VERSION ""

NS_ :

BS_:

BU_: PPIM HCP VDCM APM2 SGW IDCM EVCU2 BPCM

BO_ 2564455666 DIAGNOSTIC_REQUEST_FD_SGCP: 64 SGW
 SG_ N_PDU_18DA7CF2 : 7|64@0+ (1,0) [0|0] "" EVCU2

BO_ 1064 SGCP_DATA2: 64 EVCU2
 SG_ SGCP_Temp : 7|8@0+ (1,-40) [-40|215] "°C"  SGW

BO_ 263 PT_SYSTEM_FD_1: 64 EVCU2
 SG_ PowertrainPrplsnActv_PT : 146|1@0+ (1,0) [0|1] "" IDCM,BPCM
 SG_ GearEngagedForDisplay_PT : 12|5@0+ (1,0) [0|31] "" IDCM,BPCM
 SG_ GearEngaged_PT : 132|4@0+ (1,0) [0|15] "" Vector__XXX
 SG_ DriveReady_PT : 166|1@0+ (1,0) [0|1] "" BPCM

BO_ 2654339197 PDC_INFO_FD_IDCM: 32 IDCM
 SG_ EOL_FD11_IDCM : 7|1@0+ (1,0) [0|1] "-"  EVCU2,SGW
 SG_ WakeupSource_FD11_IDCM : 95|8@0+ (1,0) [0|255] "" EVCU2,SGW
 SG_ StayActiveSource_FD11_IDCM : 111|64@0+ (1,0) [0|0] "" EVCU2,SGW
 SG_ PreviousCanNMState_FD11_IDCM : 103|4@0+ (1,0) [0|15] "" EVCU2,SGW
 SG_ GenericFailSts_FD11_IDCM : 180|1@0+ (1,0) [0|1] "" EVCU2,SGW
 SG_ DES_FD11_IDCM : 183|2@0+ (1,0) [0|3] "" EVCU2,SGW
 SG_ CurrentFailSts_FD11_IDCM : 181|1@0+ (1,0) [0|1] "" EVCU2,SGW
 SG_ CurrentCanNMState_FD11_IDCM : 99|4@0+ (1,0) [0|15] "" EVCU2,SGW
 SG_ WakeupSource_FD05_IDCM : 23|8@0+ (1,0) [0|255] "" EVCU2,SGW
 SG_ StayActiveSource_FD05_IDCM : 31|64@0+ (1,0) [0|0] "" EVCU2,SGW
 SG_ PreviousCanNMState_FD05_IDCM : 11|4@0+ (1,0) [0|15] "" EVCU2,SGW
 SG_ GenericFailSts_FD05_IDCM : 5|1@0+ (1,0) [0|1] "" EVCU2,SGW
 SG_ EOL_FD05_IDCM : 2|1@0+ (1,0) [0|1] "-"  EVCU2,SGW
 SG_ DES_FD05_IDCM : 4|2@0+ (1,0) [0|3] "" EVCU2,SGW
 SG_ CurrentFailSts_FD05_IDCM : 6|1@0+ (1,0) [0|1] "" EVCU2,SGW
 SG_ CurrentCanNMState_FD05_IDCM : 15|4@0+ (1,0) [0|15] "" EVCU2,SGW

BO_ 216 PT_ENERGY_FD_1: 64 EVCU2
 SG_ MC_PT_ENERGY_FD_1 : 435|4@0+ (1,0) [0|15] "-"  IDCM,BPCM
 SG_ DCChrgVoltMin_PT : 55|14@0+ (0.1,0) [0|1638.30] "" APM2
 SG_ DCChrgVoltMax_PT : 151|14@0+ (0.1,0) [0|1638.30] "V"  APM2
 SG_ DCChrgPwrLim_PT : 119|14@0+ (0.1,-815) [-815|823.30] "kW"  APM2
 SG_ DCChrgCurrentRq_PT : 95|14@0+ (0.1,-815) [-815|823.30] "A"  APM2
 SG_ DCChrgCurrentLimit_PT : 21|14@0+ (0.1,-815) [-815|823.30] "A"  APM2
 SG_ DCChargeInitialized_PT : 56|1@0+ (1,0) [0|1] "" BPCM
 SG_ DCChargeEnRq_PT : 38|1@0+ (1,0) [0|1] "" APM2
 SG_ CRC_PT_ENERGY_FD_1 : 447|8@0+ (1,0) [0|255] "-"  IDCM,BPCM
 SG_ BPCM_OBCM_AC_ContactorCmd_PT : 140|3@0+ (1,0) [0|7] "" IDCM,BPCM
 SG_ BMS_HV_TracCntctr_Cmd_PT : 4|3@0+ (1,0) [0|7] "" IDCM,BPCM
 SG_ BMS_HV_RefTracHVBus_V_Vldty_PT : 23|1@0+ (1,0) [0|1] "" BPCM
 SG_ BMS_HV_RefTracHVBus_V_PT : 1|10@0+ (1,0) [0|1023] "" BPCM
 SG_ BMS_HV_GFD_Inhibition_PT : 39|1@0+ (1,0) [0|1] "" BPCM
 SG_ BMS_HV_DC_Chrgng_Cntct_K_Cmd_PT : 82|3@0+ (1,0) [0|7] "" APM2,IDCM,BPCM
 SG_ BatteryVoltage_Raw_PT : 97|10@0+ (0.2,0) [0|204.60] "V"  IDCM,BPCM
 SG_ APM2_TypeCtrl_PT : 7|3@0+ (1,0) [0|7] "" APM2
 SG_ APM_LV_VsetPoint_PT : 135|11@0+ (0.01,0) [0|20.47] "V"  IDCM
 SG_ APM_LV_VActual_PT : 71|9@0+ (0.04,0) [0|20.44] "V"  IDCM
 SG_ APM_LV_IMax_PT : 167|9@0+ (1,0) [0|511] "A"  IDCM
 SG_ APM_HV_IMax_PT : 87|5@0+ (0.8,0) [0|24.8] "A"  IDCM
 SG_ APM_TypeCtrl_PT : 78|4@0+ (1,0) [0|15] "" IDCM
 SG_ EVCU_Resp_AUX_LoadTurned_Off : 174|1@0+ (1,0) [0|1] "" BPCM
 SG_ DC_Charge_Type_Command : 121|2@0+ (1,0) [0|3] "" BPCM
 SG_ BMS_HV_Char_Main_Contac_Cmd_PT : 173|3@0+ (1,0) [0|7] "" BPCM
 SG_ APM2_EVSEBusPrechargeReq_PT : 57|1@0+ (1,0) [0|1] "" APM2
 SG_ APM2_EVSEBusVoltSetPoint_PT : 37|14@0+ (0.1,0) [0|1638.30] "V"  APM2
 SG_ APM2ActDischRq_PT : 22|1@0+ (1,0) [0|1] "" APM2
 SG_ APM2_BoostSwitchControl : 137|2@0+ (1,0) [0|3] "" APM2
 SG_ APM2_ModeRequest_PT : 183|4@0+ (1,0) [0|15] "" APM2

BO_ 1042 IDCM_ISO15118_STATUS1: 64 IDCM
 SG_ PMax_RelStart_Interval : 79|24@0+ (1,0) [0|16777215] "Seconds"  EVCU2
 SG_ PMax_RelDuration_Interval : 103|24@0+ (1,0) [0|16777215] "Seconds"  EVCU2
 SG_ ParameterID_Update : 235|1@0+ (1,0) [0|1] "" EVCU2
 SG_ ParameterID_Installation : 192|1@0+ (1,0) [0|1] "" EVCU2
 SG_ ISO15118_VersionNumMinor : 4|3@0+ (1,0) [0|7] "" EVCU2
 SG_ ISO15118_VersionNumMajor : 7|3@0+ (1,0) [0|7] "" EVCU2
 SG_ ISO15118_TLS_Status : 191|3@0+ (1,0) [0|4] "" EVCU2
 SG_ ISO15118_TLS_Offered : 176|1@0+ (1,0) [0|1] "" EVCU2
 SG_ ISO15118_ServiceID : 143|16@0+ (1,0) [0|65535] "" EVCU2
 SG_ ISO15118_SchemaID : 199|7@0+ (1,0) [0|127] "" EVCU2
 SG_ ISO15118_SAScheduleTupleID : 127|8@0+ (1,0) [0|255] "" EVCU2
 SG_ ISO15118_ResponseCode : 181|5@0+ (1,0) [0|31] "" EVCU2
 SG_ ISO15118_PMaxScheduleID : 135|8@0+ (1,0) [0|255] "" EVCU2
 SG_ ISO15118_PMax : 167|18@0+ (1,0) [0|262143] "W"  EVCU2
 SG_ ISO15118_NotificationMaxDelay : 207|18@0+ (1,0) [0|262143] "Seconds"  EVCU2
 SG_ ISO15118_MessageResponse : 188|5@0+ (1,0) [0|31] "" EVCU2
 SG_ ISO15118_EVSETimeStamp : 15|64@0+ (1,0) [0|0] "Unix Time"  EVCU2
 SG_ ISO15118_EVCC_ActionRequest : 1|2@0+ (1,0) [0|3] "" EVCU2
 SG_ ISO15118_EnergyToDeliver : 221|18@0+ (1,0) [0|262143] "Wh"  EVCU2
 SG_ EVSE_Service4_UseCaseInfo : 156|1@0+ (1,0) [0|1] "" EVCU2
 SG_ EVSE_Service4_Free : 152|1@0+ (1,0) [0|1] "" EVCU2
 SG_ EVSE_Service3_Internet : 157|1@0+ (1,0) [0|1] "" EVCU2
 SG_ EVSE_Service3_Free : 153|1@0+ (1,0) [0|1] "" EVCU2
 SG_ EVSE_Service2_Free : 154|1@0+ (1,0) [0|1] "" EVCU2
 SG_ EVSE_Service2_Certificates : 158|1@0+ (1,0) [0|1] "" EVCU2
 SG_ EVSE_Service1_Free : 155|1@0+ (1,0) [0|1] "" EVCU2
 SG_ EVSE_Service1_Charging : 159|1@0+ (1,0) [0|1] "" EVCU2
 SG_ MC_IDCM_ISO15118_STATUS1 : 435|4@0+ (1,0) [0|15] "" EVCU2
 SG_ CRC_IDCM_ISO15118_STATUS1 : 447|8@0+ (1,0) [0|255] "" EVCU2
 SG_ Contract_Certificate_Present : 244|1@0+ (1,0) [0|1] "" EVCU2
 SG_ EVSE_Offered_AC_Single_Phase : 234|1@0+ (1,0) [0|1] "" EVCU2
 SG_ EVSE_Offered_AC_Three_Phase : 233|1@0+ (1,0) [0|1] "" EVCU2
 SG_ EVSE_Offered_DC_Combo_Core : 246|1@0+ (1,0) [0|1] "" EVCU2
 SG_ EVSE_Offered_DC_Core : 232|1@0+ (1,0) [0|1] "" EVCU2
 SG_ EVSE_Offered_DC_Extended : 247|1@0+ (1,0) [0|1] "" EVCU2
 SG_ EVSE_Offered_DC_Unique : 245|1@0+ (1,0) [0|1] "" EVCU2
 SG_ V2X_EVSE_Service_6_Free : 242|1@0+ (1,0) [0|1] "-"  EVCU2
 SG_ V2X_EVSE_Service_5_Free : 243|1@0+ (1,0) [0|1] "-"  EVCU2

BO_ 1041 EVCU_ISO15118_STATUS1: 64 EVCU2
 SG_ SelectionParameterSetID : 1|2@0+ (1,0) [0|2] "" IDCM
 SG_ Protocol_Priority3 : 3|2@0+ (1,0) [0|3] "" IDCM
 SG_ Protocol_Priority2 : 5|2@0+ (1,0) [0|3] "" IDCM
 SG_ Protocol_Priority1 : 7|2@0+ (1,0) [0|3] "" IDCM
 SG_ MaxEntriesSASScheduleTuple : 127|10@0+ (1,0) [0|1023] "" IDCM
 SG_ ISO15118_TLS_Connected : 152|1@0+ (1,0) [0|1] "" IDCM
 SG_ ISO15118_TimeToFullSOC : 143|21@0+ (1,0) [0|2097151] "Seconds"  IDCM
 SG_ ISO15118_TimeToBulkSOC : 223|21@0+ (1,0) [0|2097151] "Seconds"  IDCM
 SG_ ISO15118_SessionID : 15|64@0+ (1,0) [0|0] "HexBinary"  IDCM
 SG_ ISO15118_EVErrorCode : 133|4@0+ (1,0) [0|15] "" IDCM
 SG_ ISO15118_EVEnergyRequest : 193|18@0+ (1,0) [0|262143] "Wh"  IDCM
 SG_ ISO15118_EVEnergyCapacity : 179|18@0+ (1,0) [0|262143] "Wh"  IDCM
 SG_ ISO15118_EVCCID : 79|48@0+ (1,0) [0|0] "HexBinary"  IDCM
 SG_ ISO15118_DepartureTime : 167|20@0+ (1,0) [0|1048575] "Seconds"  IDCM
 SG_ ISO15118_ChargeSession : 154|2@0+ (1,0) [0|2] "" IDCM
 SG_ ISO15118_ChargeProgress : 129|2@0+ (1,0) [0|3] "" IDCM
 SG_ EVMinCurrent : 264|9@0+ (1,0) [0|511] "A"  IDCM
 SG_ EVMaxVoltage : 233|10@0+ (1,0) [0|1023] "V"  IDCM
 SG_ EVMaxCurrent : 248|9@0+ (1,0) [0|511] "A"  IDCM
 SG_ Eamount : 281|18@0+ (1,0) [0|262143] "Wh"  IDCM
 SG_ MC_EVCU_ISO15118_STATUS1 : 435|4@0+ (1,0) [0|15] "" IDCM
 SG_ CRC_EVCU_ISO15118_STATUS1 : 447|8@0+ (1,0) [0|255] "" IDCM
 SG_ Protocol_Namespace_Priority_4 : 287|3@0+ (1,0) [0|7] "" IDCM
 SG_ Protocol_Namespace_Priority_3 : 271|3@0+ (1,0) [0|7] "" IDCM
 SG_ Protocol_Namespace_Priority_2 : 252|3@0+ (1,0) [0|7] "" IDCM
 SG_ Protocol_Namespace_Priority_1 : 255|3@0+ (1,0) [0|7] "" IDCM

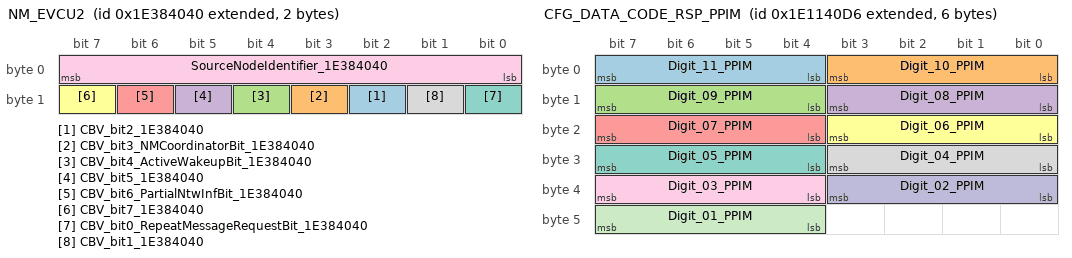
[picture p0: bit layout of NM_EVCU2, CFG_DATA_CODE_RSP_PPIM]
BO_ 2654486592 NM_EVCU2: 2 EVCU2
 SG_ CBV_bit2_1E384040 : 10|1@0+ (1,0) [0|1] "" PPIM,APM2,IDCM,SGW,BPCM,HCP
 SG_ CBV_bit3_NMCoordinatorBit_1E384040 : 11|1@0+ (1,0) [0|1] "" PPIM,APM2,IDCM,SGW,BPCM,HCP
 SG_ CBV_bit4_ActiveWakeupBit_1E384040 : 12|1@0+ (1,0) [0|1] "" PPIM,APM2,IDCM,SGW,BPCM,HCP
 SG_ CBV_bit5_1E384040 : 13|1@0+ (1,0) [0|1] "" PPIM,APM2,IDCM,SGW,BPCM,HCP
 SG_ CBV_bit6_PartialNtwInfBit_1E384040 : 14|1@0+ (1,0) [0|1] "" PPIM,APM2,IDCM,SGW,BPCM,HCP
 SG_ CBV_bit7_1E384040 : 15|1@0+ (1,0) [0|1] "" PPIM,APM2,IDCM,SGW,BPCM,HCP
 SG_ CBV_bit0_RepeatMessageRequestBit_1E384040 : 8|1@0+ (1,0) [0|1] "" PPIM,APM2,IDCM,SGW,BPCM,HCP
 SG_ CBV_bit1_1E384040 : 9|1@0+ (1,0) [0|1] "" PPIM,APM2,IDCM,SGW,BPCM,HCP
 SG_ SourceNodeIdentifier_1E384040 : 7|8@0+ (1,0) [0|255] "-"  PPIM,APM2,IDCM,SGW,BPCM,HCP

BO_ 1044 HYBRID_DISPLAY2: 64 EVCU2
 SG_ DischargingSysStatus : 66|2@0+ (0,0) [0|0] "" PPIM,APM2,IDCM
 SG_ Max_Allwd_AC_Output_Voltage_L1 : 128|9@0+ (1,0) [0|511] "V"  IDCM
 SG_ Max_Allwd_AC_Output_Current_L1 : 134|6@0+ (1,0) [0|63] "A"  IDCM
 SG_ LID_Status_120V_Socket_B : 167|1@0+ (1,0) [0|1] "" IDCM
 SG_ LID_Status_120V_Socket_A : 151|1@0+ (1,0) [0|1] "" IDCM
 SG_ LID_Status_240V_Socket : 135|1@0+ (1,0) [0|1] "" IDCM
 SG_ CRC_HYBRID_DISPLAY2 : 447|8@0+ (1,0) [0|255] "" PPIM,IDCM
 SG_ MC_HYBRID_DISPLAY2 : 435|4@0+ (1,0) [0|15] "" PPIM,IDCM

BO_ 2654408730 PLUG_AND_CHARGE_CONTRACT: 64 SGW
 SG_ PLUG_AND_CHARGE_CONTRACT_Sig8 : 455|64@0+ (0,0) [0|0] "" IDCM
 SG_ PLUG_AND_CHARGE_CONTRACT_Sig7 : 391|64@0+ (0,0) [0|0] "" IDCM
 SG_ PLUG_AND_CHARGE_CONTRACT_Sig6 : 327|64@0+ (0,0) [0|0] "" IDCM
 SG_ PLUG_AND_CHARGE_CONTRACT_Sig5 : 263|64@0+ (0,0) [0|0] "" IDCM
 SG_ PLUG_AND_CHARGE_CONTRACT_Sig4 : 199|64@0+ (0,0) [0|0] "" IDCM
 SG_ PLUG_AND_CHARGE_CONTRACT_Sig3 : 135|64@0+ (0,0) [0|0] "" IDCM
 SG_ PLUG_AND_CHARGE_CONTRACT_Sig2 : 71|64@0+ (0,0) [0|0] "" IDCM
 SG_ PLUG_AND_CHARGE_CONTRACT_Sig1 : 7|64@0+ (0,0) [0|0] "" IDCM

BO_ 2654339286 PDC_INFO_FD_PPIM: 32 PPIM
 SG_ WakeupSource_FD11_PPIM : 95|8@0+ (1,0) [0|255] "" SGW
 SG_ WakeupSource_FD05_PPIM : 23|8@0+ (1,0) [0|255] "" SGW
 SG_ StayActiveSource_FD11_PPIM : 111|64@0+ (1,0) [0|0] "" SGW
 SG_ StayActiveSource_FD05_PPIM : 31|64@0+ (1,0) [0|0] "" SGW
 SG_ PreviousCanNMState_FD11_PPIM : 103|4@0+ (1,0) [0|15] "" SGW
 SG_ PreviousCanNMState_FD05_PPIM : 11|4@0+ (1,0) [0|15] "" SGW
 SG_ GenericFailSts_FD11_PPIM : 180|1@0+ (1,0) [0|1] "" EVCU2,SGW
 SG_ GenericFailSts_FD05_PPIM : 5|1@0+ (1,0) [0|1] "" SGW
 SG_ EOL_FD11_PPIM : 7|1@0+ (1,0) [0|1] "-"  EVCU2,SGW
 SG_ EOL_FD05_PPIM : 2|1@0+ (1,0) [0|1] "-"  SGW
 SG_ DES_FD11_PPIM : 183|2@0+ (1,0) [0|3] "" SGW
 SG_ DES_FD05_PPIM : 4|2@0+ (1,0) [0|3] "" SGW
 SG_ CurrentFailSts_FD11_PPIM : 181|1@0+ (1,0) [0|1] "" EVCU2,SGW
 SG_ CurrentFailSts_FD05_PPIM : 6|1@0+ (1,0) [0|1] "" SGW
 SG_ CurrentCanNMState_FD11_PPIM : 99|4@0+ (1,0) [0|15] "" SGW
 SG_ CurrentCanNMState_FD05_PPIM : 15|4@0+ (1,0) [0|15] "" SGW

BO_ 2564430833 DIAGNOSTIC_REQUEST_PPIM: 8 SGW
 SG_ N_PDU_18DA1BF1 : 7|64@0+ (1,0) [0|0] "" PPIM

BO_ 2564430834 DIAGNOSTIC_REQUEST_FD_PPIM: 64 SGW
 SG_ N_PDU_18DA1BF2 : 7|64@0+ (1,0) [0|0] "" PPIM

BO_ 2651930838 CFG_DATA_CODE_RSP_PPIM: 6 PPIM
 SG_ Digit_11_PPIM : 7|4@0+ (1,0) [0|15] "-"  EVCU2
 SG_ Digit_10_PPIM : 3|4@0+ (1,0) [0|15] "-"  EVCU2
 SG_ Digit_09_PPIM : 15|4@0+ (1,0) [0|15] "-"  EVCU2
 SG_ Digit_08_PPIM : 11|4@0+ (1,0) [0|15] "-"  EVCU2
 SG_ Digit_07_PPIM : 23|4@0+ (1,0) [0|15] "-"  EVCU2
 SG_ Digit_06_PPIM : 19|4@0+ (1,0) [0|15] "-"  EVCU2
 SG_ Digit_05_PPIM : 31|4@0+ (1,0) [0|15] "-"  EVCU2
 SG_ Digit_04_PPIM : 27|4@0+ (1,0) [0|15] "-"  EVCU2
 SG_ Digit_03_PPIM : 39|4@0+ (1,0) [0|15] "-"  EVCU2
 SG_ Digit_02_PPIM : 35|4@0+ (1,0) [0|15] "-"  EVCU2
 SG_ Digit_01_PPIM : 47|4@0+ (1,0) [0|15] "-"  EVCU2

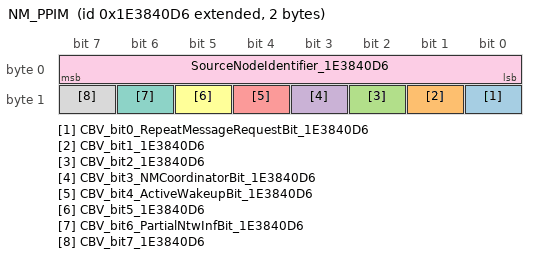
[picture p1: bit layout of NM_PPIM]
BO_ 2654486742 NM_PPIM: 2 PPIM
 SG_ CBV_bit0_RepeatMessageRequestBit_1E3840D6 : 8|1@0+ (1,0) [0|1] "" EVCU2,IDCM,SGW,BPCM,HCP
 SG_ CBV_bit1_1E3840D6 : 9|1@0+ (1,0) [0|1] "" EVCU2,IDCM,SGW,BPCM,HCP
 SG_ CBV_bit2_1E3840D6 : 10|1@0+ (1,0) [0|1] "" EVCU2,IDCM,SGW,BPCM,HCP
 SG_ CBV_bit3_NMCoordinatorBit_1E3840D6 : 11|1@0+ (1,0) [0|1] "" EVCU2,IDCM,SGW,BPCM,HCP
 SG_ CBV_bit4_ActiveWakeupBit_1E3840D6 : 12|1@0+ (1,0) [0|1] "" EVCU2,IDCM,SGW,BPCM,HCP
 SG_ CBV_bit5_1E3840D6 : 13|1@0+ (1,0) [0|1] "" EVCU2,IDCM,SGW,BPCM,HCP
 SG_ CBV_bit6_PartialNtwInfBit_1E3840D6 : 14|1@0+ (1,0) [0|1] "" EVCU2,IDCM,SGW,BPCM,HCP
 SG_ CBV_bit7_1E3840D6 : 15|1@0+ (1,0) [0|1] "" EVCU2,IDCM,SGW,BPCM,HCP
 SG_ SourceNodeIdentifier_1E3840D6 : 7|8@0+ (1,0) [0|255] "-"  EVCU2,IDCM,SGW,BPCM,HCP

BO_ 2564455444 DIAGNOSTIC_RESPONSE_FOTA_SGCP: 64 EVCU2
 SG_ N_PDU_18DA7C14 : 7|64@0+ (1,0) [0|0] "" SGW

BO_ 2564455669 DIAGNOSTIC_REQUEST_FOTA_SGCP: 64 SGW
 SG_ N_PDU_18DA7CF5 : 7|64@0+ (1,0) [0|0] "" EVCU2

BO_ 2564682011 DIAGNOSTIC_ROE_PPIM: 8 PPIM
 SG_ N_PDU_18DDF11B : 7|64@0+ (1,0) [0|0] "" SGW

BO_ 2564682267 DIAGNOSTIC_ROE_FD_PPIM: 64 PPIM
 SG_ N_PDU_18DDF21B : 7|64@0+ (1,0) [0|0] "" SGW

BO_ 2564485403 DIAGNOSTIC_RESPONSE_PPIM: 8 PPIM
 SG_ N_PDU_18DAF11B : 7|64@0+ (1,0) [0|0] "" SGW

BO_ 2564485659 DIAGNOSTIC_RESPONSE_FD_PPIM: 64 PPIM
 SG_ N_PDU_18DAF21B : 7|64@0+ (1,0) [0|0] "" SGW

BO_ 1048 RPF_FD_3: 64 EVCU2
 SG_ V2H_HVCMS_EVMax_P_Limit : 21|14@0+ (0.1,-819.1) [-819.1|819.2] "kW"  IDCM
 SG_ V2X_ModeRequest : 7|2@0+ (1,0) [0|3] "" PPIM
 SG_ DCInputCurrentLimit_V2X : 5|6@0+ (1,0) [0|63] "A"  PPIM
 SG_ ACFrequencyCommand : 13|1@0+ (1,0) [0|1] "" PPIM,IDCM
 SG_ CRC_RPF_FD_3 : 447|8@0+ (1,0) [0|255] "" IDCM
 SG_ MC_RPF_FD_3 : 435|4@0+ (1,0) [0|15] "" IDCM

BO_ 1046 RPF_FD_1: 64 IDCM
 SG_ V2H_HVCMS_EVSEMaxPowerLimit : 7|14@0+ (0.1,-819.1) [-819.1|819.2] "kW"  EVCU2
 SG_ V2X_Status : 343|2@0+ (1,0) [0|3] "" EVCU2
 SG_ V2X_Frequency : 341|10@0+ (1,0) [0|1023] "Hz"  EVCU2
 SG_ DischargeFaultStatus : 319|3@0+ (1,0) [0|7] "" EVCU2
 SG_ DCInputVoltage : 316|13@0+ (0.1,180) [180|999.1] "V"  EVCU2
 SG_ DCInputCurrent : 347|10@0+ (0.1,0) [0|102.3] "A"  EVCU2
 SG_ ACOutputVoltage3 : 387|12@0+ (0.1,0) [0|409.5] "V"  EVCU2
 SG_ ACOutputVoltage2 : 407|12@0+ (0.1,0) [0|409.5] "V"  EVCU2
 SG_ ACOutputVoltage1 : 411|12@0+ (0.1,0) [0|409.5] "V"  EVCU2
 SG_ ACOutputCurrent3 : 353|10@0+ (0.1,0) [0|102.3] "A"  EVCU2
 SG_ ACOutputCurrent2 : 375|10@0+ (0.1,0) [0|102.3] "A"  EVCU2
 SG_ ACOutputCurrent1 : 381|10@0+ (0.1,0) [0|102.3] "A"  EVCU2
 SG_ ACOutput_Frequency : 334|7@0+ (1,0) [0|127] "Hz"  EVCU2
 SG_ IDCM_GFCI_Fault_Status : 335|1@0+ (1,0) [0|1] "" EVCU2
 SG_ CRC_RPF_FD_1 : 447|8@0+ (1,0) [0|255] "" EVCU2
 SG_ MC_RPF_FD_1 : 435|4@0+ (1,0) [0|15] "" EVCU2

BO_ 1050 RPF_FD_2: 64 PPIM
 SG_ V2X_Modefeedback : 7|2@0+ (1,0) [0|3] "" EVCU2
 SG_ V2X_LV_Feed : 79|12@0+ (0.0097703,0) [0|40.00] "V"  EVCU2
 SG_ V2X_InterlockSts : 52|2@0+ (1,0) [0|3] "" EVCU2
 SG_ V2X_InputVoltage : 5|10@0+ (1,0) [0|1023] "V"  EVCU2
 SG_ V2X_InputCurrent : 11|10@0+ (0.1,0) [0|102.3] "A"  EVCU2
 SG_ V2X_FailSts : 17|1@0+ (1,0) [0|1] "" EVCU2
 SG_ V2X_Derate_Status : 16|1@0+ (1,0) [0|1] "" EVCU2
 SG_ V2X_Derate_Reason : 34|3@0+ (1,0) [0|7] "" EVCU2
 SG_ Available_Power : 71|7@0+ (0.1,0) [0|12.70] "kW"  EVCU2
 SG_ AcOutputVoltage : 47|11@0+ (0.1,0) [0|204.70] "V"  EVCU2
 SG_ AcOutputFrequency : 63|7@0+ (1,0) [0|127] "Hz"  EVCU2
 SG_ AcOuputCurrent : 31|10@0+ (0.1,0) [0|102.30] "A"  EVCU2
 SG_ V2X_FaultRsn : 83|4@0+ (1,0) [0|15] "" EVCU2
 SG_ CRC_RPF_FD_2 : 447|8@0+ (1,0) [0|255] "" EVCU2
 SG_ MC_RPF_FD_2 : 435|4@0+ (1,0) [0|15] "" EVCU2

BO_ 505 SGCP_STATUS: 32 EVCU2
 SG_ SGCP_DC_Current_P : 38|15@0+ (0.1,-1638.4) [-1638.4|1638.3] "A"  BPCM

BO_ 504 MCPB_STATUS: 32 EVCU2
 SG_ MCPB_DC_Current_P : 38|15@0+ (0.1,-1638.4) [-1638.4|1638.3] "A"  BPCM
 SG_ MC_MCPB_STATUS : 179|4@0+ (1,0) [0|15] "-"  BPCM
 SG_ CRC_MCPB_STATUS : 191|8@0+ (1,0) [0|255] "-"  BPCM

BO_ 503 MCPA_STATUS: 32 EVCU2
 SG_ MCPA_DC_Current_P : 38|15@0+ (0.1,-1638.4) [-1638.4|1638.3] "A"  BPCM
 SG_ MC_MCPA_STATUS : 179|4@0+ (1,0) [0|15] "-"  BPCM
 SG_ CRC_MCPA_STATUS : 191|8@0+ (1,0) [0|255] "-"  BPCM

BO_ 124 GLIWA_MCPB_TX: 8 EVCU2
 SG_ N_PDU_7C : 7|64@0+ (1,0) [0|0] "" SGW

BO_ 127 GLIWA_MCPB_RX: 8 SGW
 SG_ N_PDU_7F : 7|64@0+ (1,0) [0|0] "" EVCU2

BO_ 123 GLIWA_MCPA_TX: 8 EVCU2
 SG_ N_PDU_7B : 7|64@0+ (1,0) [0|0] "" SGW

BO_ 126 GLIWA_MCPA_RX: 8 SGW
 SG_ N_PDU_7E : 7|64@0+ (1,0) [0|0] "" EVCU2

BO_ 1072 IDCM_CHADEMO_STATUS1: 64 IDCM
 SG_ EVSE_ThrshldVoltage : 399|10@0+ (1,0) [0|1023] "V"  EVCU2
 SG_ EVSE_RemainingSec : 423|8@0+ (10,0) [0|2550] "sec"  EVCU2
 SG_ EVSE_RemainingMin : 415|8@0+ (1,0) [0|255] "min"  EVCU2
 SG_ EVSE_EnergizingState : 402|1@0+ (1,0) [0|1] "" EVCU2
 SG_ EVSE_ChargingSystemError : 400|1@0+ (1,0) [0|1] "" EVCU2
 SG_ EVSE_CHAdeMOProtocol : 405|3@0+ (1,0) [0|7] "" EVCU2
 SG_ EVSE_BatteryCompatibilty : 401|1@0+ (1,0) [0|1] "" EVCU2
 SG_ CdM_Charger_connector_lock : 7|1@0+ (1,0) [0|1] "" EVCU2
 SG_ CdM_ExtFun_Thres_Volt : 356|11@0+ (1,0) [0|2047] "V"  EVCU2
 SG_ CdM_Avail_output_current_EXT : 370|10@0+ (1,0) [0|1023] "A"  EVCU2

BO_ 1073 EVCU_CHADEMO_STATUS1: 64 EVCU2
 SG_ VehicleDriveSts : 402|1@0+ (1,0) [0|1] "" IDCM
 SG_ TotalBatteryCapacity : 415|16@0+ (0.1,0) [0|6553.5] "KWh"  IDCM
 SG_ StopReqBeforeCharge : 400|1@0+ (1,0) [0|1] "" IDCM
 SG_ MinBatteryPackVoltage : 399|10@0+ (1,0) [0|1023] "V"  IDCM
 SG_ EVContactorSts : 401|1@0+ (1,0) [0|1] "" IDCM
 SG_ DisplaySOC : 390|7@0+ (1,0) [0|127] "%"  IDCM
 SG_ ChargedReferenceConstant : 374|7@0+ (1,0) [0|127] "%"  IDCM
 SG_ ChargedCurrentMin : 383|8@0+ (1,0) [0|255] "A"  IDCM
 SG_ CHAdeMOProtocol : 405|3@0+ (1,0) [0|7] "" IDCM
 SG_ BattVoltDeviationErr : 391|1@0+ (1,0) [0|1] "" IDCM
 SG_ EVCU_CP3Cmd : 375|1@0+ (1,0) [0|1] "" IDCM
 SG_ CdM_Remained_batt_capacity : 367|8@0+ (0.1,0) [0|25.5] "kWh"  IDCM
 SG_ CdM_ExtFun_Veh_HC_Control_Comp : 347|1@0+ (1,0) [0|1] "" IDCM
 SG_ CdM_ExtFun_Veh_Dyn_Control_Comp : 348|1@0+ (1,0) [0|1] "" IDCM
 SG_ CdM_ExtFun_Min_Batt_Volt : 346|11@0+ (1,0) [0|2047] "V"  IDCM
 SG_ CdM_Chrg_current_req_ext : 342|10@0+ (1,0) [0|1023] "A"  IDCM

BO_ 577 SYNCHRO_DC_GLOBAL: 32 EVCU2
 SG_ QualifyDriveCycle : 7|1@0+ (1,0) [0|1] "" BPCM

BO_ 129 GLIWA_SGCP_RX: 8 SGW
 SG_ N_PDU_81 : 7|64@0+ (1,0) [0|0] "" EVCU2

BO_ 219 J1979_03_CARB_1: 64 BPCM
 SG_ HVBat_Rsrv_Enrgy_Remain : 31|16@0+ (0.1,0) [0|6553.5] "kwh"  SGW
 SG_ HVBatSOH_Distance_Last_Calc : 15|16@0+ (1,0) [0|65535] "km"  SGW
 SG_ HVBatSOH_reg : 7|8@0+ (0.4,0) [0|102] "%"  SGW

BO_ 134 GLIWA_SGCP_TX: 8 EVCU2
 SG_ N_PDU_86 : 7|64@0+ (1,0) [0|0] "" SGW

BO_ 222 IDCM_OBD_DTC: 32 IDCM
 SG_ IDCM_DTC_Idx8 : 79|5@0+ (1,0) [0|31] "" EVCU2
 SG_ IDCM_DTC_Stat1 : 18|3@0+ (1,0) [0|7] "" EVCU2
 SG_ IDCM_DTC_Stat2 : 26|3@0+ (1,0) [0|7] "" EVCU2
 SG_ IDCM_DTC_Stat3 : 34|3@0+ (1,0) [0|7] "" EVCU2
 SG_ IDCM_DTC_Stat4 : 42|3@0+ (1,0) [0|7] "" EVCU2
 SG_ IDCM_DTC_Stat5 : 50|3@0+ (1,0) [0|7] "" EVCU2
 SG_ IDCM_DTC_Idx2 : 31|5@0+ (1,0) [0|31] "" EVCU2
 SG_ IDCM_DTC_Idx3 : 39|5@0+ (1,0) [0|31] "" EVCU2
 SG_ IDCM_DTC_Idx4 : 47|5@0+ (1,0) [0|31] "" EVCU2
 SG_ IDCM_DTC_Idx5 : 55|5@0+ (1,0) [0|31] "" EVCU2
 SG_ IDCM_DTC_Idx6 : 63|5@0+ (1,0) [0|31] "" EVCU2
 SG_ IDCM_DTC_Idx7 : 71|5@0+ (1,0) [0|31] "" EVCU2
 SG_ CRC_IDCM_OBD_DTC : 191|8@0+ (1,0) [0|255] "" EVCU2
 SG_ IDCM_CAL_ID : 7|6@0+ (1,0) [0|63] "" EVCU2
 SG_ IDCM_CAL_VN : 95|8@0+ (1,0) [0|255] "" EVCU2
 SG_ IDCM_DTC_Idx1 : 23|5@0+ (1,0) [0|31] "" EVCU2
 SG_ IDCM_DTC_Stat6 : 58|3@0+ (1,0) [0|7] "" EVCU2
 SG_ IDCM_DTC_Stat7 : 66|3@0+ (1,0) [0|7] "" EVCU2
 SG_ IDCM_DTC_Stat8 : 74|3@0+ (1,0) [0|7] "" EVCU2
 SG_ IDCM_RBM_Idx : 87|5@0+ (1,0) [0|31] "" EVCU2
 SG_ IDCM_RBM_Stat : 82|3@0+ (1,0) [0|7] "" EVCU2
 SG_ MessageCounter_IDCM_OBD_DTC : 179|4@0+ (1,0) [0|15] "" EVCU2

CM_ SG_ 2654339197 EOL_FD11_IDCM "Indicates if the ECU requires configuration data at the assembly plant End Of Line";
CM_ SG_ 1064 SGCP_Temp "SGCP temperature";
CM_ SG_ 2654339197 WakeupSource_FD11_IDCM "Indicates the reason the ECU was most recently awakened";
CM_ SG_ 2654339197 StayActiveSource_FD11_IDCM "Indicates the source that requests the ECU to stay active";
CM_ SG_ 2654339197 PreviousCanNMState_FD11_IDCM "Indicates the last CanNM state that the ECU existed in";
CM_ SG_ 2654339197 GenericFailSts_FD11_IDCM "Indicates the presence/absent of at least one DTC in the System Memory";
CM_ SG_ 2654339197 DES_FD11_IDCM "Indicates whether the ECU?s CAN cell is in either ErrorActive, or ErrorPassive state OR has just now recovered from a BusOff condition";
CM_ SG_ 2654339197 CurrentFailSts_FD11_IDCM "Indicates the presence/absence of at least one DTC with DTCStatus = present in the System Memory";
CM_ SG_ 2654339197 CurrentCanNMState_FD11_IDCM "Indicates that CanNM state the ECU is currently executing";
CM_ SG_ 263 PowertrainPrplsnActv_PT "Powertrain Propulsion System Status";
CM_ SG_ 263 GearEngagedForDisplay_PT "Transmission Gear Engaged signal for the instrument cluster display";
CM_ SG_ 263 GearEngaged_PT "Current engaged gear";
CM_ SG_ 263 DriveReady_PT "Drive Ready allowed status";
CM_ SG_ 216 MC_PT_ENERGY_FD_1 "Message counter according to SAE J1850 standard that has to be calculated from bit 63 to bit 8 at each frame transmission.";
CM_ SG_ 216 DCChrgVoltMin_PT "This signal indicates the DC charging voltage min for DC-DC";
CM_ SG_ 216 DCChrgVoltMax_PT "This signal indicates the DC charging voltage max for DC-DC";
CM_ SG_ 216 DCChrgPwrLim_PT "This signal indicates the DC Charging power limit for the DC-DC";
CM_ SG_ 216 DCChrgCurrentRq_PT "This signal indicates the Requested charging current to DC-DC";
CM_ SG_ 216 DCChrgCurrentLimit_PT "This signal indicates the DC charging current limit to DC-DC";
CM_ SG_ 216 DCChargeEnRq_PT "This signal indicates the DC charge enable request";
CM_ SG_ 216 CRC_PT_ENERGY_FD_1 "CRC according to SAE J1850 standard that has to be calculated from bit 63 to bit 8 at each frame transmission.";
CM_ SG_ 216 BPCM_OBCM_AC_ContactorCmd_PT "AC Charging Strategy Status";
CM_ SG_ 216 BMS_HV_TracCntctr_Cmd_PT "This signal indicates the contactor closure command";
CM_ SG_ 216 BMS_HV_RefTracHVBus_V_Vldty_PT "This signal indicates the HV bus voltage reference for HV Precharge validity";
CM_ SG_ 216 BMS_HV_RefTracHVBus_V_PT "This signal indicates the HV bus volatage reference for HV Precharge";
CM_ SG_ 216 BMS_HV_GFD_Inhibition_PT "This signal indicates the Battery GFD Inhibition, used when an external GFD detection is performed";
CM_ SG_ 216 BMS_HV_DC_Chrgng_Cntct_K_Cmd_PT "DC Charging K7 contactor command signal";
CM_ SG_ 216 BatteryVoltage_Raw_PT "Battery Voltage value measured from the electrified powertrain control module pin";
CM_ SG_ 216 APM2_TypeCtrl_PT "This signal indicates the DC-DC control type";
CM_ SG_ 216 APM_LV_VsetPoint_PT "The signal indicates the desired Low Voltage Set Point of Electronic Voltage Regulator";
CM_ SG_ 216 APM_LV_VActual_PT "This signal indicates the Low Voltage bus actual voltage";
CM_ SG_ 216 APM_LV_IMax_PT "This signal indicates the DC-DC maximun current limitations from the LV";
CM_ SG_ 216 APM_HV_IMax_PT "This signal indicates the DC-DC maximum current limitation from HV";
CM_ SG_ 2654339197 WakeupSource_FD05_IDCM "Indicates the reason the ECU was most recently awakened";
CM_ SG_ 2654339197 StayActiveSource_FD05_IDCM "Indicates the source that requests the ECU to stay active";
CM_ SG_ 2654339197 PreviousCanNMState_FD05_IDCM "Indicates the last CanNM state that the ECU existed in";
CM_ SG_ 2654339197 GenericFailSts_FD05_IDCM "Indicates the presence/absent of at least one DTC in the System Memory";
CM_ SG_ 2654339197 EOL_FD05_IDCM "Indicates if the ECU requires configuration data at the assembly plant End Of Line";
CM_ SG_ 2654339197 DES_FD05_IDCM "Indicates whether the ECU?s CAN cell is in either ErrorActive, or ErrorPassive state OR has just now recovered from a BusOff condition";
CM_ SG_ 2654339197 CurrentFailSts_FD05_IDCM "Indicates the presence/absence of at least one DTC with DTCStatus = present in the System Memory";
CM_ SG_ 2654339197 CurrentCanNMState_FD05_IDCM "Indicates that CanNM state the ECU is currently executing";
CM_ SG_ 1042 PMax_RelStart_Interval "Relative time interval from which the specific maximum power is valid";
CM_ SG_ 1042 PMax_RelDuration_Interval "Relative duration the specified maximum power is valid";
CM_ SG_ 1042 ParameterID_Update "Availability of certificate update service";
CM_ SG_ 1042 ParameterID_Installation "Availability of installation service";
CM_ SG_ 1042 ISO15118_VersionNumMinor "Minor version number of the protocol indicated by the EVCC";
CM_ SG_ 1042 ISO15118_VersionNumMajor "Major version number of the protocol indicated by the EVCC";
CM_ SG_ 1042 ISO15118_TLS_Status "Transport Layer Security connection status";
CM_ SG_ 1042 ISO15118_TLS_Offered "TLS offered";
CM_ SG_ 1042 ISO15118_ServiceID "The unique identifier of the services offered by the EVSE";
CM_ SG_ 1042 ISO15118_SchemaID "Schema ID assigned by the EVCC to the protocol";
CM_ SG_ 1042 ISO15118_SAScheduleTupleID "Schedule tuple ID for charging";
CM_ SG_ 1042 ISO15118_ResponseCode "Response Code received from the EVCC by the SECC";
CM_ SG_ 1042 ISO15118_PMaxScheduleID "PMax Schedule ID";
CM_ SG_ 1042 ISO15118_PMax "Maximum amount of power for a time interval to be drawn from the EVSE";
CM_ SG_ 1042 ISO15118_NotificationMaxDelay "Time (in seconds) until the SECC expects the EVCC to react on the action request";
CM_ SG_ 1042 ISO15118_MessageResponse "Message response";
CM_ SG_ 1042 ISO15118_EVSETimeStamp "Unix time timestamp received from the EVSE";
CM_ SG_ 1042 ISO15118_EVCC_ActionRequest "Action request from SECC to EVCC";
CM_ SG_ 1042 ISO15118_EnergyToDeliver "Energy to be delivered to the EV";
CM_ SG_ 1042 EVSE_Service4_UseCaseInfo "Use case information is available via the EVSE";
CM_ SG_ 1042 EVSE_Service4_Free "Use case information free/paid status";
CM_ SG_ 1042 EVSE_Service3_Internet "Internet access is available via the EVSE";
CM_ SG_ 1042 EVSE_Service3_Free "Internet access free/paid status";
CM_ SG_ 1042 EVSE_Service2_Free "Certificate services free/paid status";
CM_ SG_ 1042 EVSE_Service2_Certificates "Certificate services are available at the EVSE";
CM_ SG_ 1042 EVSE_Service1_Free "AC/DC charging free/paid status";
CM_ SG_ 1042 EVSE_Service1_Charging "AC/DC charging is available at the EVSE";
CM_ SG_ 1041 SelectionParameterSetID "This signal is used to select a specific parameter set for a specific Service ID";
CM_ SG_ 1041 Protocol_Priority3 "Third priority for protocol selection";
CM_ SG_ 1041 Protocol_Priority2 "Second priority for protocol selection";
CM_ SG_ 1041 Protocol_Priority1 "First priority for protocol selection";
CM_ SG_ 1041 MaxEntriesSASScheduleTuple "Maximum number of entries in the SAS Schedule Tuple";
CM_ SG_ 1041 ISO15118_TLS_Connected "TLS communication established";
CM_ SG_ 1041 ISO15118_TimeToFullSOC "Time remaining to reach full SOC";
CM_ SG_ 1041 ISO15118_TimeToBulkSOC "Time remaining to reach bulk SOC";
CM_ SG_ 1041 ISO15118_SessionID "Session ID sent from the vehicle to the EVSE";
CM_ SG_ 1041 ISO15118_EVErrorCode "EV internal status";
CM_ SG_ 1041 ISO15118_EVEnergyRequest "HVCMS Energy Request";
CM_ SG_ 1041 ISO15118_EVEnergyCapacity "HVCMS Energy Capacity";
CM_ SG_ 1041 ISO15118_EVCCID "Electric Vehicle Communications Controller ID";
CM_ SG_ 1041 ISO15118_DepartureTime "This signal is used to indicate when the vehicel intends to finish the charging process";
CM_ SG_ 1041 ISO15118_ChargeSession "EVCC intention to pause or terminate the session";
CM_ SG_ 1041 ISO15118_ChargeProgress "Charge Process status request to EVSE";
CM_ SG_ 2654339286 WakeupSource_FD11_PPIM "Indicates the reason the ECU was most recently awakened";
CM_ SG_ 2654339286 WakeupSource_FD05_PPIM "Indicates the reason the ECU was most recently awakened";
CM_ SG_ 2654339286 StayActiveSource_FD11_PPIM "Indicates the source that requests the ECU to stay active";
CM_ SG_ 2654339286 StayActiveSource_FD05_PPIM "Indicates the source that requests the ECU to stay active";
CM_ SG_ 2654339286 PreviousCanNMState_FD11_PPIM "Indicates the last CanNM state that the ECU existed in";
CM_ SG_ 2654339286 PreviousCanNMState_FD05_PPIM "Indicates the last CanNM state that the ECU existed in";
CM_ SG_ 2654339286 GenericFailSts_FD11_PPIM "Indicates the presence/absent of at least one DTC in the System Memory";
CM_ SG_ 2654339286 GenericFailSts_FD05_PPIM "Indicates the presence/absent of at least one DTC in the System Memory";
CM_ SG_ 2654339286 EOL_FD11_PPIM "Indicates if the ECU requires configuration data at the assembly plant End Of Line";
CM_ SG_ 2654339286 EOL_FD05_PPIM "Indicates if the ECU requires configuration data at the assembly plant End Of Line";
CM_ SG_ 2654339286 DES_FD11_PPIM "Indicates whether the ECU?s CAN cell is in either ErrorActive, or ErrorPassive state OR has just now recovered from a BusOff condition";
CM_ SG_ 2654339286 DES_FD05_PPIM "Indicates whether the ECU?s CAN cell is in either ErrorActive, or ErrorPassive state OR has just now recovered from a BusOff condition";
CM_ SG_ 2654339286 CurrentFailSts_FD11_PPIM "Indicates the presence/absence of at least one DTC with DTCStatus = present in the System Memory";
CM_ SG_ 2654339286 CurrentFailSts_FD05_PPIM "Indicates the presence/absence of at least one DTC with DTCStatus = present in the System Memory";
CM_ SG_ 2654339286 CurrentCanNMState_FD11_PPIM "Indicates that CanNM state the ECU is currently executing";
CM_ SG_ 2654339286 CurrentCanNMState_FD05_PPIM "Indicates that CanNM state the ECU is currently executing";
CM_ SG_ 2564430833 N_PDU_18DA1BF1 "This signal is used for diagnostic purposes";
CM_ SG_ 2564455666 N_PDU_18DA7CF2 "This signal is used for diagnostic purposes";
CM_ SG_ 2564430834 N_PDU_18DA1BF2 "This signal is used for diagnostic purposes";
CM_ SG_ 2654486742 CBV_bit0_RepeatMessageRequestBit_1E3840D6 "Repeat Message Request Bit";
CM_ SG_ 2654486742 CBV_bit3_NMCoordinatorBit_1E3840D6 "NM Coordinator Sleep Bit";
CM_ SG_ 2654486742 CBV_bit4_ActiveWakeupBit_1E3840D6 "Active Wakeup Bit";
CM_ SG_ 2654486742 CBV_bit6_PartialNtwInfBit_1E3840D6 "Partial Network Information Bit (PNI)";
CM_ SG_ 2654486742 SourceNodeIdentifier_1E3840D6 "Source Node Identifier";
CM_ SG_ 2564455444 N_PDU_18DA7C14 "This signal is used for diagnostic purposes";
CM_ SG_ 2564455669 N_PDU_18DA7CF5 "This signal is used for diagnostic purposes";
CM_ SG_ 2564682011 N_PDU_18DDF11B "This signal is used for diagnostic purposes";
CM_ SG_ 2564682267 N_PDU_18DDF21B "This signal is used for diagnostic purposes";
CM_ SG_ 2564485403 N_PDU_18DAF11B "This signal is used for diagnostic purposes";
CM_ SG_ 2564485659 N_PDU_18DAF21B "This signal is used for diagnostic purposes";
CM_ SG_ 1044 DischargingSysStatus "Vehicle to Load/Vehicle - Discharging system status";
CM_ SG_ 1048 V2H_HVCMS_EVMax_P_Limit "This signal indicates the HVCMS EV Max Power Limit.";
CM_ SG_ 1046 V2H_HVCMS_EVSEMaxPowerLimit "This signal indicates the HVCMS EVSE Max Power Limit.";
CM_ SG_ 1041 EVMinCurrent "EV Minumum current below which it is not energy or cost efficient";
CM_ SG_ 1041 EVMaxVoltage "RMS of the maximum voltage vehicle can accept";
CM_ SG_ 1041 EVMaxCurrent "EV Maximum current supported per Phase";
CM_ SG_ 1041 Eamount "Estimated Energy to Full charge";
CM_ SG_ 1048 V2X_ModeRequest "PowerPanel Inverter Module mode request";
CM_ SG_ 1048 DCInputCurrentLimit_V2X "DC input current limit for PowerPanel Inverter Module";
CM_ SG_ 1050 V2X_Modefeedback "PowerPanel Inverter Module Mode feedback";
CM_ SG_ 1050 V2X_LV_Feed "PowerPanel Inverter Module  LV feed Voltage";
CM_ SG_ 1050 V2X_InterlockSts "PPIM  interlock status";
CM_ SG_ 1050 V2X_InputVoltage "PowerPanel Inverter Module input voltage";
CM_ SG_ 1050 V2X_InputCurrent "PowerPanel Inverter Module  input current";
CM_ SG_ 1050 V2X_FailSts "PowerPanel Inverter Module  fail status";
CM_ SG_ 1050 V2X_Derate_Status "PowerPanel Inverter Module  Derating status";
CM_ SG_ 1050 V2X_Derate_Reason "PowerPanel Inverter Module  derating reason";
CM_ SG_ 1050 Available_Power "PowerPanel Inverter Module  Available output power";
CM_ SG_ 1050 AcOutputVoltage "PowerPanel Inverter Module  AC output voltage";
CM_ SG_ 1050 AcOutputFrequency "PowerPanel Inverter Module  AC output frequency";
CM_ SG_ 1050 AcOuputCurrent "PowerPanel Inverter Module  AC output current";
CM_ SG_ 1046 V2X_Status "Vehicle to Load/Vehicle coupler detection by IDCM";
CM_ SG_ 1046 V2X_Frequency "Vehicle to Load/Vehicle frequency detected by IDCM";
CM_ SG_ 1046 DischargeFaultStatus "Discharging Fault reported by the IDCM";
CM_ SG_ 1046 DCInputVoltage "IDCM DC Input Voltage";
CM_ SG_ 1046 DCInputCurrent "IDCM DC Input Current";
CM_ SG_ 1046 ACOutputVoltage3 "IDCM AC Output Voltage  - Phase 3";
CM_ SG_ 1046 ACOutputVoltage2 "IDCM AC Output Voltage  - Phase 2";
CM_ SG_ 1046 ACOutputVoltage1 "IDCM AC Output Voltage  - Phase 1";
CM_ SG_ 1046 ACOutputCurrent3 "IDCM AC Output Current - Phase 3";
CM_ SG_ 1046 ACOutputCurrent2 "IDCM AC Output Current - Phase 2";
CM_ SG_ 1046 ACOutputCurrent1 "IDCM AC Output Current - Phase 1";
CM_ SG_ 1046 ACOutput_Frequency "IDCM AC Output Frequency";
CM_ SG_ 216 APM_TypeCtrl_PT "This signal indicates the DC-DC request mode";
CM_ SG_ 1072 EVSE_ThrshldVoltage "Voltage to judge changing stop which shall be used for the protection of traction battery";
CM_ SG_ 1072 EVSE_RemainingSec "Remaining charging time managed by charger";
CM_ SG_ 1072 EVSE_RemainingMin "Remaining charging time managed by charger";
CM_ SG_ 1072 EVSE_EnergizingState "Status flag indicating a state in which voltage can be applied from charge";
CM_ SG_ 1072 EVSE_ChargingSystemError "flag indicating vehicle error or charger error";
CM_ SG_ 1072 EVSE_CHAdeMOProtocol "Charging control version that charger corresponds with.";
CM_ SG_ 1072 EVSE_BatteryCompatibilty "available output voltage of charger  is not suitable for charging to battery.";
CM_ SG_ 1073 VehicleDriveSts "flag indicating position of a shift lever of vehicle";
CM_ SG_ 1073 TotalBatteryCapacity "Charged rate of battery calculated by vehicle that is only used for display on charger";
CM_ SG_ 1073 StopReqBeforeCharge "Stop request of charging control from vehicle before charging";
CM_ SG_ 1073 MinBatteryPackVoltage "The minimum voltage of the vehicle traction battery";
CM_ SG_ 1073 EVContactorSts "closing / opening of EV contactor and a termination of weldingdetection";
CM_ SG_ 1073 DisplaySOC "Charged rate of battery calculated by vehicle that is only used for display on charger";
CM_ SG_ 1073 ChargedReferenceConstant "Fixed value to display charged rate";
CM_ SG_ 1073 ChargedCurrentMin "Minimum current required for charging";
CM_ SG_ 1073 CHAdeMOProtocol "Charging control version that charger corresponds with.";
CM_ SG_ 1073 BattVoltDeviationErr "Error flag indicating a voltage deviation";
CM_ SG_ 216 EVCU_Resp_AUX_LoadTurned_Off "Status of AUX load turned off";
CM_ SG_ 216 DC_Charge_Type_Command "800 V charging type information";
CM_ SG_ 1050 V2X_FaultRsn "PowerPanel Inverter Module  Fault reason";
CM_ SG_ 216 BMS_HV_Char_Main_Contac_Cmd_PT "DC charging main contactor command";
CM_ SG_ 1042 MC_IDCM_ISO15118_STATUS1 "This signal is a counter used for safety checks strategies. This counter is incremented of 1 (one) unit at each frame transmission.";
CM_ SG_ 1042 CRC_IDCM_ISO15118_STATUS1 "CRC according to SAE J1850 standard at each frame transmission.";
CM_ SG_ 1041 MC_EVCU_ISO15118_STATUS1 "This signal is a counter used for safety checks strategies. This counter is incremented of 1 (one) unit at each frame transmission.";
CM_ SG_ 1041 CRC_EVCU_ISO15118_STATUS1 "CRC according to SAE J1850 standard at each frame transmission.";
CM_ SG_ 505 SGCP_DC_Current_P "SGCP DC Current";
CM_ SG_ 504 MCPB_DC_Current_P "Motor B DC Current";
CM_ SG_ 504 MC_MCPB_STATUS "Message counter according to SAE J1850 standard that has to be calculated from bit 63 to bit 8 at each frame transmission.";
CM_ SG_ 504 CRC_MCPB_STATUS "CRC according to SAE J1850 standard that has to be calculated from bit 63 to bit 8 at each frame transmission.";
CM_ SG_ 503 MCPA_DC_Current_P "Motor A DC Current";
CM_ SG_ 503 MC_MCPA_STATUS "Message counter according to SAE J1850 standard that has to be calculated from bit 63 to bit 8 at each frame transmission.";
CM_ SG_ 503 CRC_MCPA_STATUS "CRC according to SAE J1850 standard that has to be calculated from bit 63 to bit 8 at each frame transmission.";
CM_ SG_ 1041 Protocol_Namespace_Priority_4 "Fourth priority for protocol selection";
CM_ SG_ 1041 Protocol_Namespace_Priority_3 "Third priority for protocol selection";
CM_ SG_ 1041 Protocol_Namespace_Priority_2 "Second priority for protocol selection";
CM_ SG_ 1041 Protocol_Namespace_Priority_1 "First priority for protocol selection";
CM_ SG_ 1042 Contract_Certificate_Present "If a contract certifiacte is available";
CM_ SG_ 1042 EVSE_Offered_AC_Single_Phase "AC Single Phase is offered";
CM_ SG_ 1042 EVSE_Offered_AC_Three_Phase "AC Three Phase is offered";
CM_ SG_ 1042 EVSE_Offered_DC_Combo_Core "DC Combo Core is offered";
CM_ SG_ 1042 EVSE_Offered_DC_Core "DC Core is offered";
CM_ SG_ 1042 EVSE_Offered_DC_Extended "DC Extended is offered";
CM_ SG_ 1042 EVSE_Offered_DC_Unique "DC Unique is offered";
CM_ SG_ 216 APM2_EVSEBusPrechargeReq_PT "This signal indicates the request to the DC-DC to precharge the external bus - only in GBT/CHADEMO markets";
CM_ SG_ 216 APM2_EVSEBusVoltSetPoint_PT "This signal indicates the Voltage set point for the DC-DC input side";
CM_ SG_ 216 APM2ActDischRq_PT "This signal indicates the Active discharge request";
CM_ SG_ 1072 CdM_Charger_connector_lock "This signal was created for LP3. Requester is Daniel Grobbel. CR number is 17996.";
CM_ SG_ 1073 EVCU_CP3Cmd "Vehicle charge permission command for CHAdeMO";
CM_ SG_ 1073 CdM_Remained_batt_capacity "CHAdeMO - Remaining capacitance of the vehicle mounted battery (used so that the charger can display charge rate) - Backwords Compatibily";
CM_ SG_ 1048 ACFrequencyCommand "AC discharge frequency command";
CM_ SG_ 1042 V2X_EVSE_Service_6_Free "V2G Services Available on EVSE";
CM_ SG_ 1042 V2X_EVSE_Service_5_Free "V2H Services Available on EVSE";
CM_ SG_ 1044 Max_Allwd_AC_Output_Voltage_L1 "Maximum allowed voltage from Line 1";
CM_ SG_ 1044 Max_Allwd_AC_Output_Current_L1 "Maximum allowed current draw from Line 1";
CM_ SG_ 1044 LID_Status_120V_Socket_B "Status of 120V socket B";
CM_ SG_ 1044 LID_Status_120V_Socket_A "Status of 120V socket A";
CM_ SG_ 577 QualifyDriveCycle "Qualified Drive Cycle";
CM_ SG_ 1048 CRC_RPF_FD_3 "CRC according to SAE J1850 standard at each frame transmission.";
CM_ SG_ 1048 MC_RPF_FD_3 "This signal is a counter used for safety checks strategies. This counter is incremented of 1 (one) unit at each frame transmission.";
CM_ SG_ 1050 CRC_RPF_FD_2 "CRC according to SAE J1850 standard at each frame transmission.";
CM_ SG_ 1050 MC_RPF_FD_2 "This signal is a counter used for safety checks strategies. This counter is incremented of 1 (one) unit at each frame transmission.";
CM_ SG_ 1046 IDCM_GFCI_Fault_Status "IDCM shutdown due to GFCI fault status sent to EVCU2";
CM_ SG_ 1046 CRC_RPF_FD_1 "CRC according to SAE J1850 standard at each frame transmission.";
CM_ SG_ 1046 MC_RPF_FD_1 "This signal is a counter used for safety checks strategies. This counter is incremented of 1 (one) unit at each frame transmission.";
CM_ SG_ 1044 LID_Status_240V_Socket "Status of 240V socket";
CM_ SG_ 1044 CRC_HYBRID_DISPLAY2 "CRC according to SAE J1850 standard at each frame transmission.";
CM_ SG_ 1044 MC_HYBRID_DISPLAY2 "This signal is a counter used for safety checks strategies. This counter is incremented of 1 (one) unit at each frame transmission.";
CM_ SG_ 216 APM2_BoostSwitchControl "This signal indicates the APM2 Boost Swtch control.";
CM_ SG_ 216 APM2_ModeRequest_PT "This signal indicates the DC-DC Mode Request";
CM_ SG_ 219 HVBat_Rsrv_Enrgy_Remain "Remaining Energy Storage System Reserve Energy";
CM_ SG_ 219 HVBatSOH_Distance_Last_Calc "Distance since last SOH Update";
CM_ SG_ 219 HVBatSOH_reg "HV Battery percentage of State of Health.  Last-Known value to be stored in EEPROM.";
CM_ SG_ 1072 CdM_ExtFun_Thres_Volt "\"Voltage to judge changing stop which shall be used for the protection of traction battery.\"";
CM_ SG_ 1072 CdM_Avail_output_current_EXT "Maximum output current value of the charger";
CM_ SG_ 1073 CdM_ExtFun_Veh_HC_Control_Comp "A flag indicating a vehicle is compatible with high current control";
CM_ SG_ 1073 CdM_ExtFun_Veh_Dyn_Control_Comp "Flag indicating vehicle that is compatible with dynamic control.";
CM_ SG_ 1073 CdM_ExtFun_Min_Batt_Volt "The minimum voltage of the vehicle traction battery (voltage at the vehicle inlet).";
CM_ SG_ 1073 CdM_Chrg_current_req_ext "Current value that vehicle requests charger during charging";
CM_ SG_ 222 IDCM_DTC_Idx8 "Integrated Dual Charger Module DTC Index 8.";
CM_ SG_ 222 IDCM_DTC_Stat1 "Diagnostic Trouble Code status 1.";
CM_ SG_ 222 IDCM_DTC_Stat2 "Diagnostic Trouble Code status 2.";
CM_ SG_ 222 IDCM_DTC_Stat3 "Diagnostic Trouble Code status 3.";
CM_ SG_ 222 IDCM_DTC_Stat4 "Diagnostic Trouble Code status 4.";
CM_ SG_ 222 IDCM_DTC_Stat5 "Diagnostic Trouble Code status 5.";
CM_ SG_ 222 IDCM_DTC_Idx2 "Integrated Dual Charger Module DTC Index 2.";
CM_ SG_ 222 IDCM_DTC_Idx3 "Integrated Dual Charger Module DTC Index 3.";
CM_ SG_ 222 IDCM_DTC_Idx4 "Integrated Dual Charger Module DTC Index 4.";
CM_ SG_ 222 IDCM_DTC_Idx5 "Integrated Dual Charger Module DTC Index 5.";
CM_ SG_ 222 IDCM_DTC_Idx6 "Integrated Dual Charger Module DTC Index 6.";
CM_ SG_ 222 IDCM_DTC_Idx7 "Integrated Dual Charger Module DTC Index 7.";
CM_ SG_ 222 CRC_IDCM_OBD_DTC "CRC according to SAE J1850 standard at each frame transmission.";
CM_ SG_ 222 IDCM_CAL_ID "Integrated Dual Charger Module calibration ID index.";
CM_ SG_ 222 IDCM_CAL_VN "Integrated Dual Charger Module calibration verification number.";
CM_ SG_ 222 IDCM_DTC_Idx1 "Integrated Dual Charger Module DTC Index 1.";
CM_ SG_ 222 IDCM_DTC_Stat6 "Diagnostic Trouble Code status 6.";
CM_ SG_ 222 IDCM_DTC_Stat7 "Diagnostic Trouble Code status 7.";
CM_ SG_ 222 IDCM_DTC_Stat8 "Diagnostic Trouble Code status 8.";
CM_ SG_ 222 IDCM_RBM_Idx "Integrated Dual Charger Module Rate-Based Monitor index.";
CM_ SG_ 222 IDCM_RBM_Stat "Integrated Dual Charger Module Rate-Based Monitor status.";
CM_ SG_ 222 MessageCounter_IDCM_OBD_DTC "This signal is a counter used for safety checks strategies. This counter is incremented of 1 (one) unit at each frame transmission.";
BA_DEF_ SG_ "GenSigTimeoutTime_HCP" INT 0 65535;
BA_DEF_ SG_ "GenSigTimeoutTime_PPIM" INT 0 65535;
BA_DEF_ SG_ "GenSigTimeoutTime_APM2" INT 0 65535;
BA_DEF_ SG_ "GenSigTimeoutTime_VDCM" INT 0 65535;
BA_DEF_ SG_ "GenSigStartValue" INT 0 2147483647;
BA_DEF_ SG_ "GenSigInactiveValue" INT 0 2147483647;
BA_DEF_ SG_ "GenSigSendType" ENUM "NotUsed","OnWrite","OnWriteWithRepetition","OnChange","OnChangeWithRepetition","IfActive","IfActiveWithRepetition","NoSigSendType";
BA_DEF_ SG_ "SystemSignalLongSymbol" STRING ;
BA_DEF_ SG_ "GenSigTimeoutTime_BPCM" INT 0 65535;
BA_DEF_ SG_ "GenSigTimeoutTime_EVCU2" INT 0 65535;
BA_DEF_ SG_ "GenSigTimeoutTime_IDCM" INT 0 65535;
BA_DEF_ SG_ "GenSigTimeoutTime_SGW" INT 0 65535;
BA_DEF_ BO_ "DiagRequest" ENUM "No","Yes";
BA_DEF_ BO_ "Type" ENUM "P","C","PE","COC","PE_Cntrl","E","E_Cntrl","OC","S","BAF","DC","EM","MM","ISO-TP","-";
BA_DEF_ BO_ "DiagResponse" ENUM "No","Yes";
BA_DEF_ BO_ "NmMessage" ENUM "No","Yes";
BA_DEF_ BO_ "GenMsgSendType" ENUM "Cyclic","NotUsed","NotUsed","NotUsed","NotUsed","NotUsed","NotUsed","NotUsed","NoMsgSendType";
BA_DEF_ BO_ "GenMsgNrOfRepetition" INT 0 255;
BA_DEF_ BO_ "GenMsgILSupport" ENUM "No","Yes";
BA_DEF_ BO_ "GenMsgStartDelayTime" INT 0 65535;
BA_DEF_ BO_ "GenMsgCycleTimeFast" INT 0 65535;
BA_DEF_ BO_ "GenMsgCycleTime" INT 0 65535;
BA_DEF_ BO_ "GenMsgDelayTime" INT 0 65535;
BA_DEF_ BO_ "NmAsrMessage" ENUM "No","Yes";
BA_DEF_ BO_ "DiagState" ENUM "No","Yes";
BA_DEF_ BO_ "DiagConnection" HEX 0 65535;
BA_DEF_ BO_ "CanTpFcFrameId" HEX 0 2147483647;
BA_DEF_ BO_ "VFrameFormat" ENUM "StandardCAN","ExtendedCAN","reserved","reserved","reserved","reserved","reserved","reserved","reserved","reserved","reserved","reserved","reserved","reserved","StandardCAN_FD","ExtendedCAN_FD";
BA_DEF_ BO_ "CANFD_BRS" ENUM "0","1";
BA_DEF_DEF_ "GenSigTimeoutTime_HCP" 2500;
BA_DEF_DEF_ "GenSigTimeoutTime_PPIM" 2500;
BA_DEF_DEF_ "GenSigTimeoutTime_APM2" 2500;
BA_DEF_DEF_ "GenSigTimeoutTime_VDCM" 2500;
BA_DEF_DEF_ "GenSigStartValue" 0;
BA_DEF_DEF_ "GenSigInactiveValue" 0;
BA_DEF_DEF_ "GenSigSendType" "NoSigSendType";
BA_DEF_DEF_ "SystemSignalLongSymbol" "";
BA_DEF_DEF_ "GenSigTimeoutTime_BPCM" 2500;
BA_DEF_DEF_ "GenSigTimeoutTime_EVCU2" 2500;
BA_DEF_DEF_ "GenSigTimeoutTime_IDCM" 2500;
BA_DEF_DEF_ "GenSigTimeoutTime_SGW" 2500;
BA_DEF_DEF_ "DiagRequest" "No";
BA_DEF_DEF_ "Type" "-";
BA_DEF_DEF_ "DiagResponse" "No";
BA_DEF_DEF_ "NmMessage" "No";
BA_DEF_DEF_ "GenMsgSendType" "NoMsgSendType";
BA_DEF_DEF_ "GenMsgNrOfRepetition" 0;
BA_DEF_DEF_ "GenMsgILSupport" "No";
BA_DEF_DEF_ "GenMsgStartDelayTime" 0;
BA_DEF_DEF_ "GenMsgCycleTimeFast" 0;
BA_DEF_DEF_ "GenMsgCycleTime" 0;
BA_DEF_DEF_ "GenMsgDelayTime" 0;
BA_DEF_DEF_ "NmAsrMessage" "No";
BA_DEF_DEF_ "DiagState" "No";
BA_DEF_DEF_ "DiagConnection" 0;
BA_DEF_DEF_ "CanTpFcFrameId" 2147483647;
BA_DEF_DEF_ "VFrameFormat" "StandardCAN_FD";
BA_DEF_DEF_ "CANFD_BRS" "0";
BA_ "DiagRequest" BO_ 2564455666 1;
BA_ "Type" BO_ 2564455666 8;
BA_ "DiagConnection" BO_ 2564455666 62076;
BA_ "VFrameFormat" BO_ 2564455666 15;
BA_ "CANFD_BRS" BO_ 2564455666 1;
BA_ "Type" BO_ 1064 1;
BA_ "GenMsgSendType" BO_ 1064 0;
BA_ "GenMsgILSupport" BO_ 1064 1;
BA_ "GenMsgCycleTime" BO_ 1064 100;
BA_ "CANFD_BRS" BO_ 1064 1;
BA_ "Type" BO_ 263 1;
BA_ "GenMsgSendType" BO_ 263 0;
BA_ "GenMsgILSupport" BO_ 263 1;
BA_ "GenMsgCycleTime" BO_ 263 10;
BA_ "CANFD_BRS" BO_ 263 1;
BA_ "Type" BO_ 2654339197 1;
BA_ "GenMsgSendType" BO_ 2654339197 0;
BA_ "GenMsgILSupport" BO_ 2654339197 1;
BA_ "GenMsgCycleTime" BO_ 2654339197 1000;
BA_ "VFrameFormat" BO_ 2654339197 15;
BA_ "CANFD_BRS" BO_ 2654339197 1;
BA_ "Type" BO_ 216 1;
BA_ "GenMsgSendType" BO_ 216 0;
BA_ "GenMsgILSupport" BO_ 216 1;
BA_ "GenMsgCycleTime" BO_ 216 10;
BA_ "CANFD_BRS" BO_ 216 1;
BA_ "GenMsgCycleTime" BO_ 1042 100;
BA_ "CANFD_BRS" BO_ 1042 1;
BA_ "Type" BO_ 1042 1;
BA_ "GenMsgSendType" BO_ 1042 0;
BA_ "GenMsgILSupport" BO_ 1042 1;
BA_ "Type" BO_ 1041 1;
BA_ "GenMsgSendType" BO_ 1041 0;
BA_ "GenMsgILSupport" BO_ 1041 1;
BA_ "GenMsgCycleTime" BO_ 1041 100;
BA_ "CANFD_BRS" BO_ 1041 1;
BA_ "Type" BO_ 2654486592 8;
BA_ "NmMessage" BO_ 2654486592 1;
BA_ "NmAsrMessage" BO_ 2654486592 1;
BA_ "VFrameFormat" BO_ 2654486592 15;
BA_ "CANFD_BRS" BO_ 2654486592 1;
BA_ "CANFD_BRS" BO_ 1044 1;
BA_ "Type" BO_ 1044 1;
BA_ "GenMsgSendType" BO_ 1044 0;
BA_ "GenMsgILSupport" BO_ 1044 1;
BA_ "GenMsgCycleTime" BO_ 1044 100;
BA_ "GenMsgDelayTime" BO_ 1044 20;
BA_ "Type" BO_ 2654408730 13;
BA_ "GenMsgILSupport" BO_ 2654408730 1;
BA_ "GenMsgDelayTime" BO_ 2654408730 20;
BA_ "CanTpFcFrameId" BO_ 2654408730 506929178;
BA_ "VFrameFormat" BO_ 2654408730 15;
BA_ "CANFD_BRS" BO_ 2654408730 1;
BA_ "Type" BO_ 2654339286 1;
BA_ "GenMsgSendType" BO_ 2654339286 0;
BA_ "GenMsgILSupport" BO_ 2654339286 1;
BA_ "GenMsgCycleTime" BO_ 2654339286 1000;
BA_ "VFrameFormat" BO_ 2654339286 15;
BA_ "CANFD_BRS" BO_ 2654339286 1;
BA_ "DiagRequest" BO_ 2564430833 1;
BA_ "Type" BO_ 2564430833 8;
BA_ "DiagConnection" BO_ 2564430833 61723;
BA_ "VFrameFormat" BO_ 2564430833 1;
BA_ "DiagRequest" BO_ 2564430834 1;
BA_ "Type" BO_ 2564430834 8;
BA_ "DiagConnection" BO_ 2564430834 61979;
BA_ "VFrameFormat" BO_ 2564430834 15;
BA_ "CANFD_BRS" BO_ 2564430834 1;
BA_ "Type" BO_ 2651930838 11;
BA_ "GenMsgILSupport" BO_ 2651930838 1;
BA_ "VFrameFormat" BO_ 2651930838 15;
BA_ "CANFD_BRS" BO_ 2651930838 1;
BA_ "Type" BO_ 2654486742 8;
BA_ "NmMessage" BO_ 2654486742 1;
BA_ "NmAsrMessage" BO_ 2654486742 1;
BA_ "VFrameFormat" BO_ 2654486742 15;
BA_ "CANFD_BRS" BO_ 2654486742 1;
BA_ "Type" BO_ 2564455444 8;
BA_ "DiagResponse" BO_ 2564455444 1;
BA_ "DiagConnection" BO_ 2564455444 31764;
BA_ "VFrameFormat" BO_ 2564455444 15;
BA_ "CANFD_BRS" BO_ 2564455444 1;
BA_ "DiagRequest" BO_ 2564455669 1;
BA_ "Type" BO_ 2564455669 8;
BA_ "DiagConnection" BO_ 2564455669 62844;
BA_ "VFrameFormat" BO_ 2564455669 15;
BA_ "CANFD_BRS" BO_ 2564455669 1;
BA_ "Type" BO_ 2564682011 8;
BA_ "DiagResponse" BO_ 2564682011 1;
BA_ "DiagConnection" BO_ 2564682011 61723;
BA_ "VFrameFormat" BO_ 2564682011 1;
BA_ "Type" BO_ 2564682267 8;
BA_ "DiagResponse" BO_ 2564682267 1;
BA_ "DiagConnection" BO_ 2564682267 61979;
BA_ "VFrameFormat" BO_ 2564682267 15;
BA_ "CANFD_BRS" BO_ 2564682267 1;
BA_ "Type" BO_ 2564485403 8;
BA_ "DiagResponse" BO_ 2564485403 1;
BA_ "DiagConnection" BO_ 2564485403 61723;
BA_ "VFrameFormat" BO_ 2564485403 1;
BA_ "Type" BO_ 2564485659 8;
BA_ "DiagResponse" BO_ 2564485659 1;
BA_ "DiagConnection" BO_ 2564485659 61979;
BA_ "VFrameFormat" BO_ 2564485659 15;
BA_ "CANFD_BRS" BO_ 2564485659 1;
BA_ "Type" BO_ 1048 1;
BA_ "GenMsgSendType" BO_ 1048 0;
BA_ "GenMsgILSupport" BO_ 1048 1;
BA_ "GenMsgCycleTime" BO_ 1048 100;
BA_ "CANFD_BRS" BO_ 1048 1;
BA_ "Type" BO_ 1046 1;
BA_ "GenMsgSendType" BO_ 1046 0;
BA_ "GenMsgILSupport" BO_ 1046 1;
BA_ "GenMsgCycleTime" BO_ 1046 100;
BA_ "CANFD_BRS" BO_ 1046 1;
BA_ "Type" BO_ 1050 1;
BA_ "GenMsgSendType" BO_ 1050 0;
BA_ "GenMsgILSupport" BO_ 1050 1;
BA_ "GenMsgCycleTime" BO_ 1050 100;
BA_ "CANFD_BRS" BO_ 1050 1;
BA_ "Type" BO_ 505 1;
BA_ "GenMsgSendType" BO_ 505 0;
BA_ "GenMsgILSupport" BO_ 505 1;
BA_ "GenMsgCycleTime" BO_ 505 20;
BA_ "CANFD_BRS" BO_ 505 1;
BA_ "Type" BO_ 504 1;
BA_ "GenMsgSendType" BO_ 504 0;
BA_ "GenMsgILSupport" BO_ 504 1;
BA_ "GenMsgCycleTime" BO_ 504 20;
BA_ "CANFD_BRS" BO_ 504 1;
BA_ "Type" BO_ 503 1;
BA_ "GenMsgSendType" BO_ 503 0;
BA_ "GenMsgILSupport" BO_ 503 1;
BA_ "GenMsgCycleTime" BO_ 503 20;
BA_ "CANFD_BRS" BO_ 503 1;
BA_ "Type" BO_ 124 8;
BA_ "GenMsgILSupport" BO_ 124 1;
BA_ "CANFD_BRS" BO_ 124 1;
BA_ "Type" BO_ 127 8;
BA_ "GenMsgILSupport" BO_ 127 1;
BA_ "CANFD_BRS" BO_ 127 1;
BA_ "Type" BO_ 123 8;
BA_ "GenMsgILSupport" BO_ 123 1;
BA_ "CANFD_BRS" BO_ 123 1;
BA_ "Type" BO_ 126 8;
BA_ "GenMsgILSupport" BO_ 126 1;
BA_ "CANFD_BRS" BO_ 126 1;
BA_ "Type" BO_ 1072 1;
BA_ "GenMsgSendType" BO_ 1072 0;
BA_ "GenMsgILSupport" BO_ 1072 1;
BA_ "GenMsgCycleTime" BO_ 1072 100;
BA_ "CANFD_BRS" BO_ 1072 1;
BA_ "Type" BO_ 1073 1;
BA_ "GenMsgSendType" BO_ 1073 0;
BA_ "GenMsgILSupport" BO_ 1073 1;
BA_ "GenMsgCycleTime" BO_ 1073 100;
BA_ "CANFD_BRS" BO_ 1073 1;
BA_ "Type" BO_ 577 3;
BA_ "GenMsgSendType" BO_ 577 0;
BA_ "GenMsgILSupport" BO_ 577 1;
BA_ "GenMsgCycleTime" BO_ 577 1000;
BA_ "GenMsgDelayTime" BO_ 577 20;
BA_ "CANFD_BRS" BO_ 577 1;
BA_ "Type" BO_ 129 8;
BA_ "GenMsgILSupport" BO_ 129 1;
BA_ "CANFD_BRS" BO_ 129 1;
BA_ "Type" BO_ 219 1;
BA_ "GenMsgSendType" BO_ 219 0;
BA_ "GenMsgILSupport" BO_ 219 1;
BA_ "GenMsgCycleTime" BO_ 219 100;
BA_ "GenMsgDelayTime" BO_ 219 20;
BA_ "CANFD_BRS" BO_ 219 1;
BA_ "Type" BO_ 134 8;
BA_ "GenMsgILSupport" BO_ 134 1;
BA_ "CANFD_BRS" BO_ 134 1;
BA_ "Type" BO_ 222 1;
BA_ "GenMsgSendType" BO_ 222 0;
BA_ "GenMsgILSupport" BO_ 222 1;
BA_ "GenMsgCycleTime" BO_ 222 100;
BA_ "GenMsgDelayTime" BO_ 222 20;
BA_ "CANFD_BRS" BO_ 222 1;
BA_ "GenSigTimeoutTime_SGW" SG_ 1041 Eamount 0;
BA_ "GenSigTimeoutTime_BPCM" SG_ 1041 ISO15118_ChargeProgress 0;
BA_ "GenSigTimeoutTime_EVCU2" SG_ 1041 ISO15118_ChargeProgress 0;
BA_ "GenSigTimeoutTime_SGW" SG_ 1041 ISO15118_ChargeProgress 0;
BA_ "GenSigTimeoutTime_BPCM" SG_ 1042 ISO15118_SchemaID 0;
BA_ "GenSigTimeoutTime_IDCM" SG_ 1042 ISO15118_SchemaID 0;
BA_ "GenSigTimeoutTime_SGW" SG_ 1042 ISO15118_SchemaID 0;
BA_ "GenSigTimeoutTime_HCP" SG_ 1042 ISO15118_SchemaID 0;
BA_ "GenSigTimeoutTime_PPIM" SG_ 1042 ISO15118_SchemaID 0;
BA_ "GenSigTimeoutTime_APM2" SG_ 1042 ISO15118_SchemaID 0;
BA_ "GenSigTimeoutTime_VDCM" SG_ 1042 ISO15118_SchemaID 0;
BA_ "GenSigTimeoutTime_HCP" SG_ 1042 ISO15118_ResponseCode 0;
BA_ "GenSigTimeoutTime_PPIM" SG_ 1042 ISO15118_ResponseCode 0;
BA_ "GenSigTimeoutTime_APM2" SG_ 1042 ISO15118_ResponseCode 0;
BA_ "GenSigTimeoutTime_VDCM" SG_ 1042 ISO15118_ResponseCode 0;
BA_ "GenSigTimeoutTime_HCP" SG_ 1042 ISO15118_PMaxScheduleID 0;
BA_ "GenSigTimeoutTime_PPIM" SG_ 1042 ISO15118_PMaxScheduleID 0;
BA_ "GenSigTimeoutTime_APM2" SG_ 1042 ISO15118_PMaxScheduleID 0;
BA_ "GenSigTimeoutTime_VDCM" SG_ 1042 ISO15118_PMaxScheduleID 0;
BA_ "GenSigTimeoutTime_HCP" SG_ 1042 ISO15118_PMax 0;
BA_ "GenSigTimeoutTime_PPIM" SG_ 1042 ISO15118_PMax 0;
BA_ "GenSigTimeoutTime_APM2" SG_ 1042 ISO15118_PMax 0;
BA_ "GenSigTimeoutTime_VDCM" SG_ 1042 ISO15118_PMax 0;
BA_ "GenSigTimeoutTime_HCP" SG_ 1042 ISO15118_NotificationMaxDelay 0;
BA_ "GenSigTimeoutTime_PPIM" SG_ 1042 ISO15118_NotificationMaxDelay 0;
BA_ "GenSigTimeoutTime_APM2" SG_ 1042 ISO15118_NotificationMaxDelay 0;
BA_ "GenSigTimeoutTime_VDCM" SG_ 1042 ISO15118_NotificationMaxDelay 0;
BA_ "GenSigTimeoutTime_HCP" SG_ 1042 ISO15118_MessageResponse 0;
BA_ "GenSigTimeoutTime_PPIM" SG_ 1042 ISO15118_MessageResponse 0;
BA_ "GenSigTimeoutTime_APM2" SG_ 1042 ISO15118_MessageResponse 0;
BA_ "GenSigTimeoutTime_VDCM" SG_ 1042 ISO15118_MessageResponse 0;
BA_ "GenSigTimeoutTime_HCP" SG_ 1042 ISO15118_EVSETimeStamp 0;
BA_ "GenSigTimeoutTime_PPIM" SG_ 1042 ISO15118_EVSETimeStamp 0;
BA_ "GenSigTimeoutTime_APM2" SG_ 1042 ISO15118_EVSETimeStamp 0;
BA_ "GenSigTimeoutTime_VDCM" SG_ 1042 ISO15118_EVSETimeStamp 0;
BA_ "GenSigTimeoutTime_HCP" SG_ 1042 ISO15118_EVCC_ActionRequest 0;
BA_ "GenSigTimeoutTime_PPIM" SG_ 1042 ISO15118_EVCC_ActionRequest 0;
BA_ "GenSigTimeoutTime_APM2" SG_ 1042 ISO15118_EVCC_ActionRequest 0;
BA_ "GenSigTimeoutTime_VDCM" SG_ 1042 ISO15118_EVCC_ActionRequest 0;
BA_ "GenSigTimeoutTime_HCP" SG_ 1042 ISO15118_EnergyToDeliver 0;
BA_ "GenSigTimeoutTime_PPIM" SG_ 1042 ISO15118_EnergyToDeliver 0;
BA_ "GenSigTimeoutTime_APM2" SG_ 1042 ISO15118_EnergyToDeliver 0;
BA_ "GenSigTimeoutTime_VDCM" SG_ 1042 ISO15118_EnergyToDeliver 0;
BA_ "GenSigTimeoutTime_HCP" SG_ 1042 EVSE_Service4_UseCaseInfo 0;
BA_ "GenSigTimeoutTime_PPIM" SG_ 1042 EVSE_Service4_UseCaseInfo 0;
BA_ "GenSigTimeoutTime_APM2" SG_ 1042 EVSE_Service4_UseCaseInfo 0;
BA_ "GenSigTimeoutTime_VDCM" SG_ 1042 EVSE_Service4_UseCaseInfo 0;
BA_ "GenSigTimeoutTime_HCP" SG_ 1042 EVSE_Service4_Free 0;
BA_ "GenSigTimeoutTime_PPIM" SG_ 1042 EVSE_Service4_Free 0;
BA_ "GenSigTimeoutTime_APM2" SG_ 1042 EVSE_Service4_Free 0;
BA_ "GenSigTimeoutTime_VDCM" SG_ 1042 EVSE_Service4_Free 0;
BA_ "GenSigTimeoutTime_HCP" SG_ 1042 EVSE_Service3_Internet 0;
BA_ "GenSigTimeoutTime_PPIM" SG_ 1042 EVSE_Service3_Internet 0;
BA_ "GenSigTimeoutTime_APM2" SG_ 1042 EVSE_Service3_Internet 0;
BA_ "GenSigTimeoutTime_VDCM" SG_ 1042 EVSE_Service3_Internet 0;
BA_ "GenSigTimeoutTime_HCP" SG_ 1042 EVSE_Service3_Free 0;
BA_ "GenSigTimeoutTime_PPIM" SG_ 1042 EVSE_Service3_Free 0;
BA_ "GenSigTimeoutTime_APM2" SG_ 1042 EVSE_Service3_Free 0;
BA_ "GenSigTimeoutTime_VDCM" SG_ 1042 EVSE_Service3_Free 0;
BA_ "GenSigTimeoutTime_HCP" SG_ 1042 EVSE_Service2_Free 0;
BA_ "GenSigTimeoutTime_PPIM" SG_ 1042 EVSE_Service2_Free 0;
BA_ "GenSigTimeoutTime_APM2" SG_ 1042 EVSE_Service2_Free 0;
BA_ "GenSigTimeoutTime_VDCM" SG_ 1042 EVSE_Service2_Free 0;
BA_ "GenSigTimeoutTime_HCP" SG_ 1042 EVSE_Service2_Certificates 0;
BA_ "GenSigTimeoutTime_PPIM" SG_ 1042 EVSE_Service2_Certificates 0;
BA_ "GenSigTimeoutTime_APM2" SG_ 1042 EVSE_Service2_Certificates 0;
BA_ "GenSigTimeoutTime_VDCM" SG_ 1042 EVSE_Service2_Certificates 0;
BA_ "GenSigTimeoutTime_HCP" SG_ 1042 EVSE_Service1_Free 0;
BA_ "GenSigTimeoutTime_PPIM" SG_ 1042 EVSE_Service1_Free 0;
BA_ "GenSigTimeoutTime_APM2" SG_ 1042 EVSE_Service1_Free 0;
BA_ "GenSigTimeoutTime_VDCM" SG_ 1042 EVSE_Service1_Free 0;
BA_ "GenSigTimeoutTime_HCP" SG_ 1042 EVSE_Service1_Charging 0;
BA_ "GenSigTimeoutTime_PPIM" SG_ 1042 EVSE_Service1_Charging 0;
BA_ "GenSigTimeoutTime_APM2" SG_ 1042 EVSE_Service1_Charging 0;
BA_ "GenSigTimeoutTime_VDCM" SG_ 1042 EVSE_Service1_Charging 0;
BA_ "GenSigTimeoutTime_BPCM" SG_ 1041 SelectionParameterSetID 0;
BA_ "GenSigTimeoutTime_EVCU2" SG_ 1041 SelectionParameterSetID 0;
BA_ "GenSigTimeoutTime_SGW" SG_ 1041 SelectionParameterSetID 0;
BA_ "GenSigTimeoutTime_BPCM" SG_ 1041 Protocol_Priority3 0;
BA_ "GenSigTimeoutTime_EVCU2" SG_ 1041 Protocol_Priority3 0;
BA_ "GenSigTimeoutTime_SGW" SG_ 1041 Protocol_Priority3 0;
BA_ "GenSigTimeoutTime_BPCM" SG_ 1041 Protocol_Priority2 0;
BA_ "GenSigTimeoutTime_EVCU2" SG_ 1041 Protocol_Priority2 0;
BA_ "GenSigTimeoutTime_SGW" SG_ 1041 Protocol_Priority2 0;
BA_ "GenSigTimeoutTime_BPCM" SG_ 1041 Protocol_Priority1 0;
BA_ "GenSigTimeoutTime_EVCU2" SG_ 1041 Protocol_Priority1 0;
BA_ "GenSigTimeoutTime_SGW" SG_ 1041 Protocol_Priority1 0;
BA_ "GenSigStartValue" SG_ 1041 MaxEntriesSASScheduleTuple 1;
BA_ "GenSigTimeoutTime_BPCM" SG_ 1041 MaxEntriesSASScheduleTuple 0;
BA_ "GenSigTimeoutTime_EVCU2" SG_ 1041 MaxEntriesSASScheduleTuple 0;
BA_ "GenSigTimeoutTime_SGW" SG_ 1041 MaxEntriesSASScheduleTuple 0;
BA_ "GenSigTimeoutTime_BPCM" SG_ 1041 ISO15118_TimeToFullSOC 0;
BA_ "GenSigTimeoutTime_EVCU2" SG_ 1041 ISO15118_TimeToFullSOC 0;
BA_ "GenSigTimeoutTime_SGW" SG_ 1041 ISO15118_TimeToFullSOC 0;
BA_ "GenSigTimeoutTime_BPCM" SG_ 1041 ISO15118_TLS_Connected 0;
BA_ "GenSigTimeoutTime_EVCU2" SG_ 1041 ISO15118_TLS_Connected 0;
BA_ "GenSigTimeoutTime_SGW" SG_ 1041 ISO15118_TLS_Connected 0;
BA_ "GenSigTimeoutTime_BPCM" SG_ 1041 ISO15118_EVCCID 0;
BA_ "GenSigTimeoutTime_EVCU2" SG_ 1041 ISO15118_EVCCID 0;
BA_ "GenSigTimeoutTime_SGW" SG_ 1041 ISO15118_EVCCID 0;
BA_ "GenSigStartValue" SG_ 1041 ISO15118_DepartureTime 1;
BA_ "GenSigTimeoutTime_BPCM" SG_ 1041 ISO15118_DepartureTime 0;
BA_ "GenSigTimeoutTime_EVCU2" SG_ 1041 ISO15118_DepartureTime 0;
BA_ "GenSigTimeoutTime_SGW" SG_ 1041 ISO15118_DepartureTime 0;
BA_ "GenSigTimeoutTime_BPCM" SG_ 1041 ISO15118_ChargeSession 0;
BA_ "GenSigTimeoutTime_EVCU2" SG_ 1041 ISO15118_ChargeSession 0;
BA_ "GenSigTimeoutTime_SGW" SG_ 1041 ISO15118_ChargeSession 0;
BA_ "GenSigTimeoutTime_HCP" SG_ 1042 PMax_RelStart_Interval 0;
BA_ "GenSigTimeoutTime_PPIM" SG_ 1042 PMax_RelStart_Interval 0;
BA_ "GenSigTimeoutTime_APM2" SG_ 1042 PMax_RelStart_Interval 0;
BA_ "GenSigTimeoutTime_VDCM" SG_ 1042 PMax_RelStart_Interval 0;
BA_ "GenSigTimeoutTime_HCP" SG_ 1042 PMax_RelDuration_Interval 0;
BA_ "GenSigTimeoutTime_PPIM" SG_ 1042 PMax_RelDuration_Interval 0;
BA_ "GenSigTimeoutTime_APM2" SG_ 1042 PMax_RelDuration_Interval 0;
BA_ "GenSigTimeoutTime_VDCM" SG_ 1042 PMax_RelDuration_Interval 0;
BA_ "GenSigTimeoutTime_HCP" SG_ 1042 ParameterID_Update 0;
BA_ "GenSigTimeoutTime_PPIM" SG_ 1042 ParameterID_Update 0;
BA_ "GenSigTimeoutTime_APM2" SG_ 1042 ParameterID_Update 0;
BA_ "GenSigTimeoutTime_VDCM" SG_ 1042 ParameterID_Update 0;
BA_ "GenSigTimeoutTime_HCP" SG_ 1042 ParameterID_Installation 0;
BA_ "GenSigTimeoutTime_PPIM" SG_ 1042 ParameterID_Installation 0;
BA_ "GenSigTimeoutTime_APM2" SG_ 1042 ParameterID_Installation 0;
BA_ "GenSigTimeoutTime_VDCM" SG_ 1042 ParameterID_Installation 0;
BA_ "GenSigTimeoutTime_VDCM" SG_ 1042 ISO15118_VersionNumMinor 0;
BA_ "GenSigTimeoutTime_HCP" SG_ 1042 ISO15118_VersionNumMinor 0;
BA_ "GenSigTimeoutTime_PPIM" SG_ 1042 ISO15118_VersionNumMinor 0;
BA_ "GenSigTimeoutTime_APM2" SG_ 1042 ISO15118_VersionNumMinor 0;
BA_ "GenSigTimeoutTime_HCP" SG_ 1042 ISO15118_VersionNumMajor 0;
BA_ "GenSigTimeoutTime_PPIM" SG_ 1042 ISO15118_VersionNumMajor 0;
BA_ "GenSigTimeoutTime_APM2" SG_ 1042 ISO15118_VersionNumMajor 0;
BA_ "GenSigTimeoutTime_VDCM" SG_ 1042 ISO15118_VersionNumMajor 0;
BA_ "GenSigTimeoutTime_HCP" SG_ 1042 ISO15118_TLS_Status 0;
BA_ "GenSigTimeoutTime_PPIM" SG_ 1042 ISO15118_TLS_Status 0;
BA_ "GenSigTimeoutTime_APM2" SG_ 1042 ISO15118_TLS_Status 0;
BA_ "GenSigTimeoutTime_VDCM" SG_ 1042 ISO15118_TLS_Status 0;
BA_ "GenSigTimeoutTime_BPCM" SG_ 1042 ISO15118_TLS_Offered 0;
BA_ "GenSigTimeoutTime_IDCM" SG_ 1042 ISO15118_TLS_Offered 0;
BA_ "GenSigTimeoutTime_HCP" SG_ 1042 ISO15118_TLS_Offered 0;
BA_ "GenSigTimeoutTime_PPIM" SG_ 1042 ISO15118_TLS_Offered 0;
BA_ "GenSigTimeoutTime_APM2" SG_ 1042 ISO15118_TLS_Offered 0;
BA_ "GenSigTimeoutTime_VDCM" SG_ 1042 ISO15118_TLS_Offered 0;
BA_ "GenSigTimeoutTime_BPCM" SG_ 1042 ISO15118_ServiceID 0;
BA_ "GenSigTimeoutTime_IDCM" SG_ 1042 ISO15118_ServiceID 0;
BA_ "GenSigTimeoutTime_SGW" SG_ 1042 ISO15118_ServiceID 0;
BA_ "GenSigTimeoutTime_HCP" SG_ 1042 ISO15118_ServiceID 0;
BA_ "GenSigTimeoutTime_PPIM" SG_ 1042 ISO15118_ServiceID 0;
BA_ "GenSigTimeoutTime_APM2" SG_ 1042 ISO15118_ServiceID 0;
BA_ "GenSigTimeoutTime_VDCM" SG_ 1042 ISO15118_ServiceID 0;
BA_ "GenSigTimeoutTime_BPCM" SG_ 1042 ISO15118_SAScheduleTupleID 0;
BA_ "GenSigTimeoutTime_IDCM" SG_ 1042 ISO15118_SAScheduleTupleID 0;
BA_ "GenSigTimeoutTime_SGW" SG_ 1042 ISO15118_SAScheduleTupleID 0;
BA_ "GenSigTimeoutTime_HCP" SG_ 1042 ISO15118_SAScheduleTupleID 0;
BA_ "GenSigTimeoutTime_PPIM" SG_ 1042 ISO15118_SAScheduleTupleID 0;
BA_ "GenSigTimeoutTime_APM2" SG_ 1042 ISO15118_SAScheduleTupleID 0;
BA_ "GenSigTimeoutTime_VDCM" SG_ 1042 ISO15118_SAScheduleTupleID 0;
BA_ "GenSigTimeoutTime_HCP" SG_ 2654486742 CBV_bit0_RepeatMessageRequestBit_1E3840D6 0;
BA_ "GenSigTimeoutTime_PPIM" SG_ 2654486742 CBV_bit0_RepeatMessageRequestBit_1E3840D6 0;
BA_ "GenSigTimeoutTime_BPCM" SG_ 2654486742 CBV_bit0_RepeatMessageRequestBit_1E3840D6 0;
BA_ "GenSigTimeoutTime_EVCU2" SG_ 2654486742 CBV_bit0_RepeatMessageRequestBit_1E3840D6 0;
BA_ "GenSigTimeoutTime_IDCM" SG_ 2654486742 CBV_bit0_RepeatMessageRequestBit_1E3840D6 0;
BA_ "GenSigTimeoutTime_SGW" SG_ 2654486742 CBV_bit0_RepeatMessageRequestBit_1E3840D6 0;
BA_ "GenSigTimeoutTime_HCP" SG_ 2654486742 CBV_bit2_1E3840D6 0;
BA_ "GenSigTimeoutTime_PPIM" SG_ 2654486742 CBV_bit2_1E3840D6 0;
BA_ "GenSigTimeoutTime_BPCM" SG_ 2654486742 CBV_bit2_1E3840D6 0;
BA_ "GenSigTimeoutTime_EVCU2" SG_ 2654486742 CBV_bit2_1E3840D6 0;
BA_ "GenSigTimeoutTime_IDCM" SG_ 2654486742 CBV_bit2_1E3840D6 0;
BA_ "GenSigTimeoutTime_SGW" SG_ 2654486742 CBV_bit2_1E3840D6 0;
BA_ "GenSigTimeoutTime_HCP" SG_ 2654486742 CBV_bit1_1E3840D6 0;
BA_ "GenSigTimeoutTime_PPIM" SG_ 2654486742 CBV_bit1_1E3840D6 0;
BA_ "GenSigTimeoutTime_BPCM" SG_ 2654486742 CBV_bit1_1E3840D6 0;
BA_ "GenSigTimeoutTime_EVCU2" SG_ 2654486742 CBV_bit1_1E3840D6 0;
BA_ "GenSigTimeoutTime_IDCM" SG_ 2654486742 CBV_bit1_1E3840D6 0;
BA_ "GenSigTimeoutTime_SGW" SG_ 2654486742 CBV_bit1_1E3840D6 0;
BA_ "GenSigTimeoutTime_HCP" SG_ 2654486742 CBV_bit7_1E3840D6 0;
BA_ "GenSigTimeoutTime_PPIM" SG_ 2654486742 CBV_bit7_1E3840D6 0;
BA_ "GenSigTimeoutTime_BPCM" SG_ 2654486742 CBV_bit7_1E3840D6 0;
BA_ "GenSigTimeoutTime_EVCU2" SG_ 2654486742 CBV_bit7_1E3840D6 0;
BA_ "GenSigTimeoutTime_IDCM" SG_ 2654486742 CBV_bit7_1E3840D6 0;
BA_ "GenSigTimeoutTime_SGW" SG_ 2654486742 CBV_bit7_1E3840D6 0;
BA_ "GenSigTimeoutTime_HCP" SG_ 2654486742 SourceNodeIdentifier_1E3840D6 0;
BA_ "GenSigTimeoutTime_PPIM" SG_ 2654486742 SourceNodeIdentifier_1E3840D6 0;
BA_ "GenSigTimeoutTime_BPCM" SG_ 2654486742 SourceNodeIdentifier_1E3840D6 0;
BA_ "GenSigTimeoutTime_EVCU2" SG_ 2654486742 SourceNodeIdentifier_1E3840D6 0;
BA_ "GenSigTimeoutTime_IDCM" SG_ 2654486742 SourceNodeIdentifier_1E3840D6 0;
BA_ "GenSigTimeoutTime_SGW" SG_ 2654486742 SourceNodeIdentifier_1E3840D6 0;
BA_ "GenSigTimeoutTime_HCP" SG_ 2654486742 CBV_bit6_PartialNtwInfBit_1E3840D6 0;
BA_ "GenSigTimeoutTime_PPIM" SG_ 2654486742 CBV_bit6_PartialNtwInfBit_1E3840D6 0;
BA_ "GenSigTimeoutTime_BPCM" SG_ 2654486742 CBV_bit6_PartialNtwInfBit_1E3840D6 0;
BA_ "GenSigTimeoutTime_EVCU2" SG_ 2654486742 CBV_bit6_PartialNtwInfBit_1E3840D6 0;
BA_ "GenSigTimeoutTime_IDCM" SG_ 2654486742 CBV_bit6_PartialNtwInfBit_1E3840D6 0;
BA_ "GenSigTimeoutTime_SGW" SG_ 2654486742 CBV_bit6_PartialNtwInfBit_1E3840D6 0;
BA_ "GenSigTimeoutTime_HCP" SG_ 2654486742 CBV_bit5_1E3840D6 0;
BA_ "GenSigTimeoutTime_PPIM" SG_ 2654486742 CBV_bit5_1E3840D6 0;
BA_ "GenSigTimeoutTime_BPCM" SG_ 2654486742 CBV_bit5_1E3840D6 0;
BA_ "GenSigTimeoutTime_EVCU2" SG_ 2654486742 CBV_bit5_1E3840D6 0;
BA_ "GenSigTimeoutTime_IDCM" SG_ 2654486742 CBV_bit5_1E3840D6 0;
BA_ "GenSigTimeoutTime_SGW" SG_ 2654486742 CBV_bit5_1E3840D6 0;
BA_ "GenSigTimeoutTime_HCP" SG_ 2654486742 CBV_bit4_ActiveWakeupBit_1E3840D6 0;
BA_ "GenSigTimeoutTime_PPIM" SG_ 2654486742 CBV_bit4_ActiveWakeupBit_1E3840D6 0;
BA_ "GenSigTimeoutTime_BPCM" SG_ 2654486742 CBV_bit4_ActiveWakeupBit_1E3840D6 0;
BA_ "GenSigTimeoutTime_EVCU2" SG_ 2654486742 CBV_bit4_ActiveWakeupBit_1E3840D6 0;
BA_ "GenSigTimeoutTime_IDCM" SG_ 2654486742 CBV_bit4_ActiveWakeupBit_1E3840D6 0;
BA_ "GenSigTimeoutTime_SGW" SG_ 2654486742 CBV_bit4_ActiveWakeupBit_1E3840D6 0;
BA_ "GenSigTimeoutTime_HCP" SG_ 2654486742 CBV_bit3_NMCoordinatorBit_1E3840D6 0;
BA_ "GenSigTimeoutTime_PPIM" SG_ 2654486742 CBV_bit3_NMCoordinatorBit_1E3840D6 0;
BA_ "GenSigTimeoutTime_BPCM" SG_ 2654486742 CBV_bit3_NMCoordinatorBit_1E3840D6 0;
BA_ "GenSigTimeoutTime_EVCU2" SG_ 2654486742 CBV_bit3_NMCoordinatorBit_1E3840D6 0;
BA_ "GenSigTimeoutTime_IDCM" SG_ 2654486742 CBV_bit3_NMCoordinatorBit_1E3840D6 0;
BA_ "GenSigTimeoutTime_SGW" SG_ 2654486742 CBV_bit3_NMCoordinatorBit_1E3840D6 0;
BA_ "GenSigTimeoutTime_HCP" SG_ 2564430834 N_PDU_18DA1BF2 0;
BA_ "GenSigTimeoutTime_PPIM" SG_ 2564430834 N_PDU_18DA1BF2 0;
BA_ "GenSigTimeoutTime_BPCM" SG_ 2564430834 N_PDU_18DA1BF2 0;
BA_ "GenSigTimeoutTime_EVCU2" SG_ 2564430834 N_PDU_18DA1BF2 0;
BA_ "GenSigTimeoutTime_IDCM" SG_ 2564430834 N_PDU_18DA1BF2 0;
BA_ "GenSigTimeoutTime_SGW" SG_ 2564430834 N_PDU_18DA1BF2 0;
BA_ "GenSigTimeoutTime_HCP" SG_ 2564485659 N_PDU_18DAF21B 0;
BA_ "GenSigTimeoutTime_PPIM" SG_ 2564485659 N_PDU_18DAF21B 0;
BA_ "GenSigTimeoutTime_BPCM" SG_ 2564485659 N_PDU_18DAF21B 0;
BA_ "GenSigTimeoutTime_EVCU2" SG_ 2564485659 N_PDU_18DAF21B 0;
BA_ "GenSigTimeoutTime_IDCM" SG_ 2564485659 N_PDU_18DAF21B 0;
BA_ "GenSigTimeoutTime_SGW" SG_ 2564485659 N_PDU_18DAF21B 0;
BA_ "GenSigTimeoutTime_HCP" SG_ 2564485403 N_PDU_18DAF11B 0;
BA_ "GenSigTimeoutTime_PPIM" SG_ 2564485403 N_PDU_18DAF11B 0;
BA_ "GenSigTimeoutTime_BPCM" SG_ 2564485403 N_PDU_18DAF11B 0;
BA_ "GenSigTimeoutTime_EVCU2" SG_ 2564485403 N_PDU_18DAF11B 0;
BA_ "GenSigTimeoutTime_IDCM" SG_ 2564485403 N_PDU_18DAF11B 0;
BA_ "GenSigTimeoutTime_SGW" SG_ 2564485403 N_PDU_18DAF11B 0;
BA_ "GenSigTimeoutTime_HCP" SG_ 2564682267 N_PDU_18DDF21B 0;
BA_ "GenSigTimeoutTime_PPIM" SG_ 2564682267 N_PDU_18DDF21B 0;
BA_ "GenSigTimeoutTime_BPCM" SG_ 2564682267 N_PDU_18DDF21B 0;
BA_ "GenSigTimeoutTime_EVCU2" SG_ 2564682267 N_PDU_18DDF21B 0;
BA_ "GenSigTimeoutTime_IDCM" SG_ 2564682267 N_PDU_18DDF21B 0;
BA_ "GenSigTimeoutTime_SGW" SG_ 2564682267 N_PDU_18DDF21B 0;
BA_ "GenSigTimeoutTime_HCP" SG_ 2564682011 N_PDU_18DDF11B 0;
BA_ "GenSigTimeoutTime_PPIM" SG_ 2564682011 N_PDU_18DDF11B 0;
BA_ "GenSigTimeoutTime_BPCM" SG_ 2564682011 N_PDU_18DDF11B 0;
BA_ "GenSigTimeoutTime_EVCU2" SG_ 2564682011 N_PDU_18DDF11B 0;
BA_ "GenSigTimeoutTime_IDCM" SG_ 2564682011 N_PDU_18DDF11B 0;
BA_ "GenSigTimeoutTime_SGW" SG_ 2564682011 N_PDU_18DDF11B 0;
BA_ "GenSigTimeoutTime_HCP" SG_ 2651930838 Digit_02_PPIM 0;
BA_ "GenSigTimeoutTime_PPIM" SG_ 2651930838 Digit_02_PPIM 0;
BA_ "GenSigTimeoutTime_BPCM" SG_ 2651930838 Digit_02_PPIM 0;
BA_ "GenSigTimeoutTime_IDCM" SG_ 2651930838 Digit_02_PPIM 0;
BA_ "GenSigTimeoutTime_SGW" SG_ 2651930838 Digit_02_PPIM 0;
BA_ "GenSigTimeoutTime_HCP" SG_ 2651930838 Digit_01_PPIM 0;
BA_ "GenSigTimeoutTime_PPIM" SG_ 2651930838 Digit_01_PPIM 0;
BA_ "GenSigSendType" SG_ 2651930838 Digit_01_PPIM 1;
BA_ "GenSigTimeoutTime_BPCM" SG_ 2651930838 Digit_01_PPIM 0;
BA_ "GenSigTimeoutTime_IDCM" SG_ 2651930838 Digit_01_PPIM 0;
BA_ "GenSigTimeoutTime_SGW" SG_ 2651930838 Digit_01_PPIM 0;
BA_ "GenSigTimeoutTime_HCP" SG_ 1050 V2X_Modefeedback 0;
BA_ "GenSigTimeoutTime_PPIM" SG_ 1050 V2X_Modefeedback 0;
BA_ "GenSigTimeoutTime_BPCM" SG_ 1050 V2X_Modefeedback 0;
BA_ "GenSigTimeoutTime_IDCM" SG_ 1050 V2X_Modefeedback 0;
BA_ "GenSigTimeoutTime_SGW" SG_ 1050 V2X_Modefeedback 0;
BA_ "GenSigTimeoutTime_BPCM" SG_ 1050 CRC_RPF_FD_2 0;
BA_ "GenSigTimeoutTime_IDCM" SG_ 1050 CRC_RPF_FD_2 0;
BA_ "GenSigTimeoutTime_SGW" SG_ 1050 CRC_RPF_FD_2 0;
BA_ "GenSigTimeoutTime_HCP" SG_ 1050 V2X_FailSts 0;
BA_ "GenSigTimeoutTime_PPIM" SG_ 1050 V2X_FailSts 0;
BA_ "GenSigTimeoutTime_BPCM" SG_ 1050 V2X_FailSts 0;
BA_ "GenSigTimeoutTime_IDCM" SG_ 1050 V2X_FailSts 0;
BA_ "GenSigTimeoutTime_SGW" SG_ 1050 V2X_FailSts 0;
BA_ "GenSigTimeoutTime_HCP" SG_ 1050 V2X_FaultRsn 0;
BA_ "GenSigTimeoutTime_PPIM" SG_ 1050 V2X_FaultRsn 0;
BA_ "GenSigTimeoutTime_BPCM" SG_ 1050 V2X_FaultRsn 0;
BA_ "GenSigTimeoutTime_IDCM" SG_ 1050 V2X_FaultRsn 0;
BA_ "GenSigTimeoutTime_SGW" SG_ 1050 V2X_FaultRsn 0;
BA_ "GenSigTimeoutTime_HCP" SG_ 1050 V2X_LV_Feed 0;
BA_ "GenSigTimeoutTime_PPIM" SG_ 1050 V2X_LV_Feed 0;
BA_ "GenSigTimeoutTime_BPCM" SG_ 1050 V2X_LV_Feed 0;
BA_ "GenSigTimeoutTime_IDCM" SG_ 1050 V2X_LV_Feed 0;
BA_ "GenSigTimeoutTime_SGW" SG_ 1050 V2X_LV_Feed 0;
BA_ "GenSigTimeoutTime_HCP" SG_ 1050 V2X_InterlockSts 0;
BA_ "GenSigTimeoutTime_PPIM" SG_ 1050 V2X_InterlockSts 0;
BA_ "GenSigTimeoutTime_BPCM" SG_ 1050 V2X_InterlockSts 0;
BA_ "GenSigTimeoutTime_IDCM" SG_ 1050 V2X_InterlockSts 0;
BA_ "GenSigTimeoutTime_SGW" SG_ 1050 V2X_InterlockSts 0;
BA_ "GenSigTimeoutTime_HCP" SG_ 1050 V2X_InputVoltage 0;
BA_ "GenSigTimeoutTime_PPIM" SG_ 1050 V2X_InputVoltage 0;
BA_ "GenSigTimeoutTime_BPCM" SG_ 1050 V2X_InputVoltage 0;
BA_ "GenSigTimeoutTime_IDCM" SG_ 1050 V2X_InputVoltage 0;
BA_ "GenSigTimeoutTime_SGW" SG_ 1050 V2X_InputVoltage 0;
BA_ "GenSigTimeoutTime_HCP" SG_ 1050 V2X_InputCurrent 0;
BA_ "GenSigTimeoutTime_PPIM" SG_ 1050 V2X_InputCurrent 0;
BA_ "GenSigTimeoutTime_BPCM" SG_ 1050 V2X_InputCurrent 0;
BA_ "GenSigTimeoutTime_IDCM" SG_ 1050 V2X_InputCurrent 0;
BA_ "GenSigTimeoutTime_SGW" SG_ 1050 V2X_InputCurrent 0;
BA_ "GenSigTimeoutTime_HCP" SG_ 2651930838 Digit_11_PPIM 0;
BA_ "GenSigTimeoutTime_PPIM" SG_ 2651930838 Digit_11_PPIM 0;
BA_ "GenSigTimeoutTime_BPCM" SG_ 2651930838 Digit_11_PPIM 0;
BA_ "GenSigTimeoutTime_IDCM" SG_ 2651930838 Digit_11_PPIM 0;
BA_ "GenSigTimeoutTime_SGW" SG_ 2651930838 Digit_11_PPIM 0;
BA_ "GenSigTimeoutTime_HCP" SG_ 2651930838 Digit_03_PPIM 0;
BA_ "GenSigTimeoutTime_PPIM" SG_ 2651930838 Digit_03_PPIM 0;
BA_ "GenSigTimeoutTime_BPCM" SG_ 2651930838 Digit_03_PPIM 0;
BA_ "GenSigTimeoutTime_IDCM" SG_ 2651930838 Digit_03_PPIM 0;
BA_ "GenSigTimeoutTime_SGW" SG_ 2651930838 Digit_03_PPIM 0;
BA_ "GenSigTimeoutTime_HCP" SG_ 2651930838 Digit_04_PPIM 0;
BA_ "GenSigTimeoutTime_PPIM" SG_ 2651930838 Digit_04_PPIM 0;
BA_ "GenSigTimeoutTime_BPCM" SG_ 2651930838 Digit_04_PPIM 0;
BA_ "GenSigTimeoutTime_IDCM" SG_ 2651930838 Digit_04_PPIM 0;
BA_ "GenSigTimeoutTime_SGW" SG_ 2651930838 Digit_04_PPIM 0;
BA_ "GenSigTimeoutTime_HCP" SG_ 2651930838 Digit_05_PPIM 0;
BA_ "GenSigTimeoutTime_PPIM" SG_ 2651930838 Digit_05_PPIM 0;
BA_ "GenSigTimeoutTime_BPCM" SG_ 2651930838 Digit_05_PPIM 0;
BA_ "GenSigTimeoutTime_IDCM" SG_ 2651930838 Digit_05_PPIM 0;
BA_ "GenSigTimeoutTime_SGW" SG_ 2651930838 Digit_05_PPIM 0;
BA_ "GenSigTimeoutTime_HCP" SG_ 2651930838 Digit_06_PPIM 0;
BA_ "GenSigTimeoutTime_PPIM" SG_ 2651930838 Digit_06_PPIM 0;
BA_ "GenSigTimeoutTime_BPCM" SG_ 2651930838 Digit_06_PPIM 0;
BA_ "GenSigTimeoutTime_IDCM" SG_ 2651930838 Digit_06_PPIM 0;
BA_ "GenSigTimeoutTime_SGW" SG_ 2651930838 Digit_06_PPIM 0;
BA_ "GenSigTimeoutTime_HCP" SG_ 2651930838 Digit_07_PPIM 0;
BA_ "GenSigTimeoutTime_PPIM" SG_ 2651930838 Digit_07_PPIM 0;
BA_ "GenSigTimeoutTime_BPCM" SG_ 2651930838 Digit_07_PPIM 0;
BA_ "GenSigTimeoutTime_IDCM" SG_ 2651930838 Digit_07_PPIM 0;
BA_ "GenSigTimeoutTime_SGW" SG_ 2651930838 Digit_07_PPIM 0;
BA_ "GenSigTimeoutTime_IDCM" SG_ 2651930838 Digit_08_PPIM 0;
BA_ "GenSigTimeoutTime_SGW" SG_ 2651930838 Digit_08_PPIM 0;
BA_ "GenSigTimeoutTime_HCP" SG_ 2651930838 Digit_08_PPIM 0;
BA_ "GenSigTimeoutTime_PPIM" SG_ 2651930838 Digit_08_PPIM 0;
BA_ "GenSigTimeoutTime_BPCM" SG_ 2651930838 Digit_08_PPIM 0;
BA_ "GenSigTimeoutTime_HCP" SG_ 2651930838 Digit_09_PPIM 0;
BA_ "GenSigTimeoutTime_PPIM" SG_ 2651930838 Digit_09_PPIM 0;
BA_ "GenSigTimeoutTime_BPCM" SG_ 2651930838 Digit_09_PPIM 0;
BA_ "GenSigTimeoutTime_IDCM" SG_ 2651930838 Digit_09_PPIM 0;
BA_ "GenSigTimeoutTime_SGW" SG_ 2651930838 Digit_09_PPIM 0;
BA_ "GenSigTimeoutTime_HCP" SG_ 2651930838 Digit_10_PPIM 0;
BA_ "GenSigTimeoutTime_PPIM" SG_ 2651930838 Digit_10_PPIM 0;
BA_ "GenSigTimeoutTime_BPCM" SG_ 2651930838 Digit_10_PPIM 0;
BA_ "GenSigTimeoutTime_IDCM" SG_ 2651930838 Digit_10_PPIM 0;
BA_ "GenSigTimeoutTime_SGW" SG_ 2651930838 Digit_10_PPIM 0;
BA_ "GenSigTimeoutTime_HCP" SG_ 2654339286 CurrentCanNMState_FD05_PPIM 0;
BA_ "GenSigTimeoutTime_PPIM" SG_ 2654339286 CurrentCanNMState_FD05_PPIM 0;
BA_ "GenSigTimeoutTime_BPCM" SG_ 2654339286 CurrentCanNMState_FD05_PPIM 0;
BA_ "GenSigTimeoutTime_EVCU2" SG_ 2654339286 CurrentCanNMState_FD05_PPIM 0;
BA_ "GenSigTimeoutTime_IDCM" SG_ 2654339286 CurrentCanNMState_FD05_PPIM 0;
BA_ "GenSigTimeoutTime_HCP" SG_ 2654339286 CurrentCanNMState_FD11_PPIM 0;
BA_ "GenSigTimeoutTime_PPIM" SG_ 2654339286 CurrentCanNMState_FD11_PPIM 0;
BA_ "GenSigTimeoutTime_BPCM" SG_ 2654339286 CurrentCanNMState_FD11_PPIM 0;
BA_ "GenSigTimeoutTime_EVCU2" SG_ 2654339286 CurrentCanNMState_FD11_PPIM 0;
BA_ "GenSigTimeoutTime_IDCM" SG_ 2654339286 CurrentCanNMState_FD11_PPIM 0;
BA_ "GenSigTimeoutTime_HCP" SG_ 2654339286 CurrentFailSts_FD05_PPIM 0;
BA_ "GenSigTimeoutTime_PPIM" SG_ 2654339286 CurrentFailSts_FD05_PPIM 0;
BA_ "GenSigTimeoutTime_BPCM" SG_ 2654339286 CurrentFailSts_FD05_PPIM 0;
BA_ "GenSigTimeoutTime_EVCU2" SG_ 2654339286 CurrentFailSts_FD05_PPIM 0;
BA_ "GenSigTimeoutTime_IDCM" SG_ 2654339286 CurrentFailSts_FD05_PPIM 0;
BA_ "GenSigTimeoutTime_HCP" SG_ 2654339286 CurrentFailSts_FD11_PPIM 0;
BA_ "GenSigTimeoutTime_PPIM" SG_ 2654339286 CurrentFailSts_FD11_PPIM 0;
BA_ "GenSigTimeoutTime_BPCM" SG_ 2654339286 CurrentFailSts_FD11_PPIM 0;
BA_ "GenSigTimeoutTime_IDCM" SG_ 2654339286 CurrentFailSts_FD11_PPIM 0;
BA_ "GenSigTimeoutTime_HCP" SG_ 2654339286 DES_FD05_PPIM 0;
BA_ "GenSigTimeoutTime_PPIM" SG_ 2654339286 DES_FD05_PPIM 0;
BA_ "GenSigTimeoutTime_BPCM" SG_ 2654339286 DES_FD05_PPIM 0;
BA_ "GenSigTimeoutTime_EVCU2" SG_ 2654339286 DES_FD05_PPIM 0;
BA_ "GenSigTimeoutTime_IDCM" SG_ 2654339286 DES_FD05_PPIM 0;
BA_ "GenSigTimeoutTime_HCP" SG_ 2654339286 DES_FD11_PPIM 0;
BA_ "GenSigTimeoutTime_PPIM" SG_ 2654339286 DES_FD11_PPIM 0;
BA_ "GenSigTimeoutTime_BPCM" SG_ 2654339286 DES_FD11_PPIM 0;
BA_ "GenSigTimeoutTime_EVCU2" SG_ 2654339286 DES_FD11_PPIM 0;
BA_ "GenSigTimeoutTime_IDCM" SG_ 2654339286 DES_FD11_PPIM 0;
BA_ "GenSigTimeoutTime_HCP" SG_ 2654339286 EOL_FD05_PPIM 0;
BA_ "GenSigTimeoutTime_PPIM" SG_ 2654339286 EOL_FD05_PPIM 0;
BA_ "GenSigTimeoutTime_BPCM" SG_ 2654339286 EOL_FD05_PPIM 0;
BA_ "GenSigTimeoutTime_EVCU2" SG_ 2654339286 EOL_FD05_PPIM 0;
BA_ "GenSigTimeoutTime_IDCM" SG_ 2654339286 EOL_FD05_PPIM 0;
BA_ "GenSigTimeoutTime_HCP" SG_ 2654339286 WakeupSource_FD11_PPIM 0;
BA_ "GenSigTimeoutTime_PPIM" SG_ 2654339286 WakeupSource_FD11_PPIM 0;
BA_ "GenSigTimeoutTime_BPCM" SG_ 2654339286 WakeupSource_FD11_PPIM 0;
BA_ "GenSigTimeoutTime_EVCU2" SG_ 2654339286 WakeupSource_FD11_PPIM 0;
BA_ "GenSigTimeoutTime_IDCM" SG_ 2654339286 WakeupSource_FD11_PPIM 0;
BA_ "GenSigTimeoutTime_HCP" SG_ 2654339286 EOL_FD11_PPIM 0;
BA_ "GenSigTimeoutTime_PPIM" SG_ 2654339286 EOL_FD11_PPIM 0;
BA_ "GenSigTimeoutTime_BPCM" SG_ 2654339286 EOL_FD11_PPIM 0;
BA_ "GenSigTimeoutTime_IDCM" SG_ 2654339286 EOL_FD11_PPIM 0;
BA_ "GenSigTimeoutTime_HCP" SG_ 2654339286 GenericFailSts_FD05_PPIM 0;
BA_ "GenSigTimeoutTime_PPIM" SG_ 2654339286 GenericFailSts_FD05_PPIM 0;
BA_ "GenSigTimeoutTime_BPCM" SG_ 2654339286 GenericFailSts_FD05_PPIM 0;
BA_ "GenSigTimeoutTime_EVCU2" SG_ 2654339286 GenericFailSts_FD05_PPIM 0;
BA_ "GenSigTimeoutTime_IDCM" SG_ 2654339286 GenericFailSts_FD05_PPIM 0;
BA_ "GenSigTimeoutTime_HCP" SG_ 2654339286 GenericFailSts_FD11_PPIM 0;
BA_ "GenSigTimeoutTime_PPIM" SG_ 2654339286 GenericFailSts_FD11_PPIM 0;
BA_ "GenSigTimeoutTime_BPCM" SG_ 2654339286 GenericFailSts_FD11_PPIM 0;
BA_ "GenSigTimeoutTime_IDCM" SG_ 2654339286 GenericFailSts_FD11_PPIM 0;
BA_ "GenSigTimeoutTime_HCP" SG_ 2654339286 PreviousCanNMState_FD05_PPIM 0;
BA_ "GenSigTimeoutTime_PPIM" SG_ 2654339286 PreviousCanNMState_FD05_PPIM 0;
BA_ "GenSigTimeoutTime_BPCM" SG_ 2654339286 PreviousCanNMState_FD05_PPIM 0;
BA_ "GenSigTimeoutTime_EVCU2" SG_ 2654339286 PreviousCanNMState_FD05_PPIM 0;
BA_ "GenSigTimeoutTime_IDCM" SG_ 2654339286 PreviousCanNMState_FD05_PPIM 0;
BA_ "GenSigTimeoutTime_HCP" SG_ 2654339286 PreviousCanNMState_FD11_PPIM 0;
BA_ "GenSigTimeoutTime_PPIM" SG_ 2654339286 PreviousCanNMState_FD11_PPIM 0;
BA_ "GenSigTimeoutTime_BPCM" SG_ 2654339286 PreviousCanNMState_FD11_PPIM 0;
BA_ "GenSigTimeoutTime_EVCU2" SG_ 2654339286 PreviousCanNMState_FD11_PPIM 0;
BA_ "GenSigTimeoutTime_IDCM" SG_ 2654339286 PreviousCanNMState_FD11_PPIM 0;
BA_ "GenSigTimeoutTime_HCP" SG_ 2654339286 StayActiveSource_FD05_PPIM 0;
BA_ "GenSigTimeoutTime_PPIM" SG_ 2654339286 StayActiveSource_FD05_PPIM 0;
BA_ "GenSigTimeoutTime_BPCM" SG_ 2654339286 StayActiveSource_FD05_PPIM 0;
BA_ "GenSigTimeoutTime_EVCU2" SG_ 2654339286 StayActiveSource_FD05_PPIM 0;
BA_ "GenSigTimeoutTime_IDCM" SG_ 2654339286 StayActiveSource_FD05_PPIM 0;
BA_ "GenSigTimeoutTime_HCP" SG_ 2654339286 StayActiveSource_FD11_PPIM 0;
BA_ "GenSigTimeoutTime_PPIM" SG_ 2654339286 StayActiveSource_FD11_PPIM 0;
BA_ "GenSigTimeoutTime_BPCM" SG_ 2654339286 StayActiveSource_FD11_PPIM 0;
BA_ "GenSigTimeoutTime_EVCU2" SG_ 2654339286 StayActiveSource_FD11_PPIM 0;
BA_ "GenSigTimeoutTime_IDCM" SG_ 2654339286 StayActiveSource_FD11_PPIM 0;
BA_ "GenSigTimeoutTime_HCP" SG_ 2654339286 WakeupSource_FD05_PPIM 0;
BA_ "GenSigTimeoutTime_PPIM" SG_ 2654339286 WakeupSource_FD05_PPIM 0;
BA_ "GenSigTimeoutTime_BPCM" SG_ 2654339286 WakeupSource_FD05_PPIM 0;
BA_ "GenSigTimeoutTime_EVCU2" SG_ 2654339286 WakeupSource_FD05_PPIM 0;
BA_ "GenSigTimeoutTime_IDCM" SG_ 2654339286 WakeupSource_FD05_PPIM 0;
BA_ "GenSigTimeoutTime_BPCM" SG_ 2564430833 N_PDU_18DA1BF1 0;
BA_ "GenSigTimeoutTime_EVCU2" SG_ 2564430833 N_PDU_18DA1BF1 0;
BA_ "GenSigTimeoutTime_IDCM" SG_ 2564430833 N_PDU_18DA1BF1 0;
BA_ "GenSigTimeoutTime_SGW" SG_ 2564430833 N_PDU_18DA1BF1 0;
BA_ "GenSigTimeoutTime_VDCM" SG_ 219 HVBat_Rsrv_Enrgy_Remain 0;
BA_ "GenSigTimeoutTime_APM2" SG_ 219 HVBat_Rsrv_Enrgy_Remain 0;
BA_ "GenSigTimeoutTime_BPCM" SG_ 219 HVBat_Rsrv_Enrgy_Remain 0;
BA_ "GenSigTimeoutTime_EVCU2" SG_ 219 HVBat_Rsrv_Enrgy_Remain 0;
BA_ "GenSigTimeoutTime_IDCM" SG_ 219 HVBat_Rsrv_Enrgy_Remain 0;
BA_ "GenSigTimeoutTime_VDCM" SG_ 219 HVBatSOH_reg 0;
BA_ "GenSigTimeoutTime_APM2" SG_ 219 HVBatSOH_reg 0;
BA_ "GenSigTimeoutTime_BPCM" SG_ 219 HVBatSOH_reg 0;
BA_ "GenSigTimeoutTime_EVCU2" SG_ 219 HVBatSOH_reg 0;
BA_ "GenSigTimeoutTime_IDCM" SG_ 219 HVBatSOH_reg 0;
BA_ "GenSigTimeoutTime_VDCM" SG_ 219 HVBatSOH_Distance_Last_Calc 0;
BA_ "GenSigTimeoutTime_APM2" SG_ 219 HVBatSOH_Distance_Last_Calc 0;
BA_ "GenSigTimeoutTime_BPCM" SG_ 219 HVBatSOH_Distance_Last_Calc 0;
BA_ "GenSigTimeoutTime_EVCU2" SG_ 219 HVBatSOH_Distance_Last_Calc 0;
BA_ "GenSigTimeoutTime_IDCM" SG_ 219 HVBatSOH_Distance_Last_Calc 0;
BA_ "GenSigTimeoutTime_HCP" SG_ 1046 V2H_HVCMS_EVSEMaxPowerLimit 0;
BA_ "GenSigTimeoutTime_PPIM" SG_ 1046 V2H_HVCMS_EVSEMaxPowerLimit 0;
BA_ "GenSigTimeoutTime_APM2" SG_ 1046 V2H_HVCMS_EVSEMaxPowerLimit 0;
BA_ "GenSigTimeoutTime_BPCM" SG_ 1046 V2H_HVCMS_EVSEMaxPowerLimit 0;
BA_ "GenSigTimeoutTime_IDCM" SG_ 1046 V2H_HVCMS_EVSEMaxPowerLimit 0;
BA_ "GenSigTimeoutTime_SGW" SG_ 1046 V2H_HVCMS_EVSEMaxPowerLimit 0;
BA_ "GenSigTimeoutTime_EVCU2" SG_ 503 CRC_MCPA_STATUS 0;
BA_ "GenSigTimeoutTime_IDCM" SG_ 503 CRC_MCPA_STATUS 0;
BA_ "GenSigTimeoutTime_SGW" SG_ 503 CRC_MCPA_STATUS 0;
BA_ "GenSigTimeoutTime_HCP" SG_ 504 MCPB_DC_Current_P 0;
BA_ "GenSigTimeoutTime_PPIM" SG_ 504 MCPB_DC_Current_P 0;
BA_ "GenSigTimeoutTime_APM2" SG_ 504 MCPB_DC_Current_P 0;
BA_ "GenSigTimeoutTime_VDCM" SG_ 504 MCPB_DC_Current_P 0;
BA_ "GenSigStartValue" SG_ 504 MCPB_DC_Current_P 16384;
BA_ "GenSigTimeoutTime_EVCU2" SG_ 504 MCPB_DC_Current_P 0;
BA_ "GenSigTimeoutTime_IDCM" SG_ 504 MCPB_DC_Current_P 0;
BA_ "GenSigTimeoutTime_SGW" SG_ 504 MCPB_DC_Current_P 0;
BA_ "GenSigTimeoutTime_EVCU2" SG_ 503 MC_MCPA_STATUS 0;
BA_ "GenSigTimeoutTime_IDCM" SG_ 503 MC_MCPA_STATUS 0;
BA_ "GenSigTimeoutTime_SGW" SG_ 503 MC_MCPA_STATUS 0;
BA_ "GenSigStartValue" SG_ 503 MCPA_DC_Current_P 16384;
BA_ "GenSigTimeoutTime_EVCU2" SG_ 503 MCPA_DC_Current_P 0;
BA_ "GenSigTimeoutTime_IDCM" SG_ 503 MCPA_DC_Current_P 0;
BA_ "GenSigTimeoutTime_SGW" SG_ 503 MCPA_DC_Current_P 0;
BA_ "GenSigTimeoutTime_HCP" SG_ 504 CRC_MCPB_STATUS 0;
BA_ "GenSigTimeoutTime_PPIM" SG_ 504 CRC_MCPB_STATUS 0;
BA_ "GenSigTimeoutTime_APM2" SG_ 504 CRC_MCPB_STATUS 0;
BA_ "GenSigTimeoutTime_EVCU2" SG_ 504 CRC_MCPB_STATUS 0;
BA_ "GenSigTimeoutTime_IDCM" SG_ 504 CRC_MCPB_STATUS 0;
BA_ "GenSigTimeoutTime_SGW" SG_ 504 CRC_MCPB_STATUS 0;
BA_ "GenSigTimeoutTime_HCP" SG_ 504 MC_MCPB_STATUS 0;
BA_ "GenSigTimeoutTime_PPIM" SG_ 504 MC_MCPB_STATUS 0;
BA_ "GenSigTimeoutTime_APM2" SG_ 504 MC_MCPB_STATUS 0;
BA_ "GenSigTimeoutTime_EVCU2" SG_ 504 MC_MCPB_STATUS 0;
BA_ "GenSigTimeoutTime_IDCM" SG_ 504 MC_MCPB_STATUS 0;
BA_ "GenSigTimeoutTime_SGW" SG_ 504 MC_MCPB_STATUS 0;
BA_ "GenSigTimeoutTime_PPIM" SG_ 2564455669 N_PDU_18DA7CF5 0;
BA_ "GenSigTimeoutTime_BPCM" SG_ 2564455669 N_PDU_18DA7CF5 0;
BA_ "GenSigTimeoutTime_EVCU2" SG_ 2564455669 N_PDU_18DA7CF5 0;
BA_ "GenSigTimeoutTime_IDCM" SG_ 2564455669 N_PDU_18DA7CF5 0;
BA_ "GenSigTimeoutTime_SGW" SG_ 2564455669 N_PDU_18DA7CF5 0;
BA_ "GenSigTimeoutTime_HCP" SG_ 2564455669 N_PDU_18DA7CF5 0;
BA_ "GenSigTimeoutTime_HCP" SG_ 2564455444 N_PDU_18DA7C14 0;
BA_ "GenSigTimeoutTime_PPIM" SG_ 2564455444 N_PDU_18DA7C14 0;
BA_ "GenSigTimeoutTime_BPCM" SG_ 2564455444 N_PDU_18DA7C14 0;
BA_ "GenSigTimeoutTime_EVCU2" SG_ 2564455444 N_PDU_18DA7C14 0;
BA_ "GenSigTimeoutTime_IDCM" SG_ 2564455444 N_PDU_18DA7C14 0;
BA_ "GenSigTimeoutTime_SGW" SG_ 2564455444 N_PDU_18DA7C14 0;
BA_ "GenSigTimeoutTime_HCP" SG_ 505 SGCP_DC_Current_P 0;
BA_ "GenSigTimeoutTime_PPIM" SG_ 505 SGCP_DC_Current_P 0;
BA_ "GenSigStartValue" SG_ 505 SGCP_DC_Current_P 16384;
BA_ "GenSigTimeoutTime_EVCU2" SG_ 505 SGCP_DC_Current_P 0;
BA_ "GenSigTimeoutTime_IDCM" SG_ 505 SGCP_DC_Current_P 0;
BA_ "GenSigTimeoutTime_SGW" SG_ 505 SGCP_DC_Current_P 0;
BA_ "GenSigTimeoutTime_HCP" SG_ 1048 CRC_RPF_FD_3 0;
BA_ "GenSigTimeoutTime_PPIM" SG_ 1048 CRC_RPF_FD_3 0;
BA_ "GenSigTimeoutTime_BPCM" SG_ 1048 CRC_RPF_FD_3 0;
BA_ "GenSigTimeoutTime_EVCU2" SG_ 1048 CRC_RPF_FD_3 0;
BA_ "GenSigTimeoutTime_SGW" SG_ 1048 CRC_RPF_FD_3 0;
BA_ "GenSigTimeoutTime_HCP" SG_ 1048 MC_RPF_FD_3 0;
BA_ "GenSigTimeoutTime_PPIM" SG_ 1048 MC_RPF_FD_3 0;
BA_ "GenSigTimeoutTime_BPCM" SG_ 1048 MC_RPF_FD_3 0;
BA_ "GenSigTimeoutTime_EVCU2" SG_ 1048 MC_RPF_FD_3 0;
BA_ "GenSigTimeoutTime_SGW" SG_ 1048 MC_RPF_FD_3 0;
BA_ "GenSigTimeoutTime_HCP" SG_ 1048 DCInputCurrentLimit_V2X 0;
BA_ "GenSigTimeoutTime_BPCM" SG_ 1048 DCInputCurrentLimit_V2X 0;
BA_ "GenSigTimeoutTime_EVCU2" SG_ 1048 DCInputCurrentLimit_V2X 0;
BA_ "GenSigTimeoutTime_IDCM" SG_ 1048 DCInputCurrentLimit_V2X 0;
BA_ "GenSigTimeoutTime_SGW" SG_ 1048 DCInputCurrentLimit_V2X 0;
BA_ "GenSigTimeoutTime_HCP" SG_ 1048 V2X_ModeRequest 0;
BA_ "GenSigTimeoutTime_BPCM" SG_ 1048 V2X_ModeRequest 0;
BA_ "GenSigTimeoutTime_EVCU2" SG_ 1048 V2X_ModeRequest 0;
BA_ "GenSigTimeoutTime_IDCM" SG_ 1048 V2X_ModeRequest 0;
BA_ "GenSigTimeoutTime_SGW" SG_ 1048 V2X_ModeRequest 0;
BA_ "GenSigTimeoutTime_HCP" SG_ 1048 V2H_HVCMS_EVMax_P_Limit 0;
BA_ "GenSigTimeoutTime_PPIM" SG_ 1048 V2H_HVCMS_EVMax_P_Limit 0;
BA_ "GenSigTimeoutTime_APM2" SG_ 1048 V2H_HVCMS_EVMax_P_Limit 0;
BA_ "GenSigTimeoutTime_BPCM" SG_ 1048 V2H_HVCMS_EVMax_P_Limit 0;
BA_ "GenSigTimeoutTime_EVCU2" SG_ 1048 V2H_HVCMS_EVMax_P_Limit 0;
BA_ "GenSigTimeoutTime_SGW" SG_ 1048 V2H_HVCMS_EVMax_P_Limit 0;
BA_ "GenSigTimeoutTime_HCP" SG_ 1048 ACFrequencyCommand 0;
BA_ "GenSigTimeoutTime_APM2" SG_ 1048 ACFrequencyCommand 0;
BA_ "GenSigTimeoutTime_BPCM" SG_ 1048 ACFrequencyCommand 0;
BA_ "GenSigTimeoutTime_EVCU2" SG_ 1048 ACFrequencyCommand 0;
BA_ "GenSigTimeoutTime_SGW" SG_ 1048 ACFrequencyCommand 0;
BA_ "GenSigTimeoutTime_HCP" SG_ 1046 IDCM_GFCI_Fault_Status 0;
BA_ "GenSigTimeoutTime_PPIM" SG_ 1046 IDCM_GFCI_Fault_Status 0;
BA_ "GenSigTimeoutTime_BPCM" SG_ 1046 IDCM_GFCI_Fault_Status 0;
BA_ "GenSigTimeoutTime_IDCM" SG_ 1046 IDCM_GFCI_Fault_Status 0;
BA_ "GenSigTimeoutTime_SGW" SG_ 1046 IDCM_GFCI_Fault_Status 0;
BA_ "GenSigTimeoutTime_HCP" SG_ 1046 ACOutputCurrent2 0;
BA_ "GenSigTimeoutTime_PPIM" SG_ 1046 ACOutputCurrent2 0;
BA_ "GenSigTimeoutTime_APM2" SG_ 1046 ACOutputCurrent2 0;
BA_ "GenSigTimeoutTime_VDCM" SG_ 1046 ACOutputCurrent2 0;
BA_ "GenSigTimeoutTime_BPCM" SG_ 1046 ACOutputCurrent2 0;
BA_ "GenSigTimeoutTime_IDCM" SG_ 1046 ACOutputCurrent2 0;
BA_ "GenSigTimeoutTime_SGW" SG_ 1046 ACOutputCurrent2 0;
BA_ "GenSigTimeoutTime_HCP" SG_ 1046 ACOutputCurrent1 0;
BA_ "GenSigTimeoutTime_PPIM" SG_ 1046 ACOutputCurrent1 0;
BA_ "GenSigTimeoutTime_APM2" SG_ 1046 ACOutputCurrent1 0;
BA_ "GenSigTimeoutTime_VDCM" SG_ 1046 ACOutputCurrent1 0;
BA_ "GenSigTimeoutTime_BPCM" SG_ 1046 ACOutputCurrent1 0;
BA_ "GenSigTimeoutTime_IDCM" SG_ 1046 ACOutputCurrent1 0;
BA_ "GenSigTimeoutTime_SGW" SG_ 1046 ACOutputCurrent1 0;
BA_ "GenSigTimeoutTime_HCP" SG_ 1046 ACOutputVoltage3 0;
BA_ "GenSigTimeoutTime_PPIM" SG_ 1046 ACOutputVoltage3 0;
BA_ "GenSigTimeoutTime_APM2" SG_ 1046 ACOutputVoltage3 0;
BA_ "GenSigTimeoutTime_VDCM" SG_ 1046 ACOutputVoltage3 0;
BA_ "GenSigTimeoutTime_BPCM" SG_ 1046 ACOutputVoltage3 0;
BA_ "GenSigTimeoutTime_IDCM" SG_ 1046 ACOutputVoltage3 0;
BA_ "GenSigTimeoutTime_SGW" SG_ 1046 ACOutputVoltage3 0;
BA_ "GenSigTimeoutTime_HCP" SG_ 1046 ACOutputVoltage2 0;
BA_ "GenSigTimeoutTime_PPIM" SG_ 1046 ACOutputVoltage2 0;
BA_ "GenSigTimeoutTime_APM2" SG_ 1046 ACOutputVoltage2 0;
BA_ "GenSigTimeoutTime_VDCM" SG_ 1046 ACOutputVoltage2 0;
BA_ "GenSigTimeoutTime_BPCM" SG_ 1046 ACOutputVoltage2 0;
BA_ "GenSigTimeoutTime_IDCM" SG_ 1046 ACOutputVoltage2 0;
BA_ "GenSigTimeoutTime_SGW" SG_ 1046 ACOutputVoltage2 0;
BA_ "GenSigTimeoutTime_HCP" SG_ 1046 ACOutputVoltage1 0;
BA_ "GenSigTimeoutTime_PPIM" SG_ 1046 ACOutputVoltage1 0;
BA_ "GenSigTimeoutTime_APM2" SG_ 1046 ACOutputVoltage1 0;
BA_ "GenSigTimeoutTime_VDCM" SG_ 1046 ACOutputVoltage1 0;
BA_ "GenSigTimeoutTime_BPCM" SG_ 1046 ACOutputVoltage1 0;
BA_ "GenSigTimeoutTime_IDCM" SG_ 1046 ACOutputVoltage1 0;
BA_ "GenSigTimeoutTime_SGW" SG_ 1046 ACOutputVoltage1 0;
BA_ "GenSigTimeoutTime_HCP" SG_ 1046 ACOutputCurrent3 0;
BA_ "GenSigTimeoutTime_PPIM" SG_ 1046 ACOutputCurrent3 0;
BA_ "GenSigTimeoutTime_APM2" SG_ 1046 ACOutputCurrent3 0;
BA_ "GenSigTimeoutTime_VDCM" SG_ 1046 ACOutputCurrent3 0;
BA_ "GenSigTimeoutTime_BPCM" SG_ 1046 ACOutputCurrent3 0;
BA_ "GenSigTimeoutTime_IDCM" SG_ 1046 ACOutputCurrent3 0;
BA_ "GenSigTimeoutTime_SGW" SG_ 1046 ACOutputCurrent3 0;
BA_ "GenSigTimeoutTime_HCP" SG_ 1046 V2X_Status 0;
BA_ "GenSigTimeoutTime_PPIM" SG_ 1046 V2X_Status 0;
BA_ "GenSigTimeoutTime_APM2" SG_ 1046 V2X_Status 0;
BA_ "GenSigTimeoutTime_VDCM" SG_ 1046 V2X_Status 0;
BA_ "GenSigTimeoutTime_BPCM" SG_ 1046 V2X_Status 0;
BA_ "GenSigTimeoutTime_IDCM" SG_ 1046 V2X_Status 0;
BA_ "GenSigTimeoutTime_SGW" SG_ 1046 V2X_Status 0;
BA_ "GenSigTimeoutTime_HCP" SG_ 1046 V2X_Frequency 0;
BA_ "GenSigTimeoutTime_PPIM" SG_ 1046 V2X_Frequency 0;
BA_ "GenSigTimeoutTime_APM2" SG_ 1046 V2X_Frequency 0;
BA_ "GenSigTimeoutTime_VDCM" SG_ 1046 V2X_Frequency 0;
BA_ "GenSigTimeoutTime_BPCM" SG_ 1046 V2X_Frequency 0;
BA_ "GenSigTimeoutTime_IDCM" SG_ 1046 V2X_Frequency 0;
BA_ "GenSigTimeoutTime_SGW" SG_ 1046 V2X_Frequency 0;
BA_ "GenSigTimeoutTime_HCP" SG_ 1046 DischargeFaultStatus 0;
BA_ "GenSigTimeoutTime_PPIM" SG_ 1046 DischargeFaultStatus 0;
BA_ "GenSigTimeoutTime_APM2" SG_ 1046 DischargeFaultStatus 0;
BA_ "GenSigTimeoutTime_VDCM" SG_ 1046 DischargeFaultStatus 0;
BA_ "GenSigTimeoutTime_BPCM" SG_ 1046 DischargeFaultStatus 0;
BA_ "GenSigTimeoutTime_IDCM" SG_ 1046 DischargeFaultStatus 0;
BA_ "GenSigTimeoutTime_SGW" SG_ 1046 DischargeFaultStatus 0;
BA_ "GenSigTimeoutTime_HCP" SG_ 1046 DCInputVoltage 0;
BA_ "GenSigTimeoutTime_PPIM" SG_ 1046 DCInputVoltage 0;
BA_ "GenSigTimeoutTime_APM2" SG_ 1046 DCInputVoltage 0;
BA_ "GenSigTimeoutTime_VDCM" SG_ 1046 DCInputVoltage 0;
BA_ "GenSigTimeoutTime_BPCM" SG_ 1046 DCInputVoltage 0;
BA_ "GenSigTimeoutTime_IDCM" SG_ 1046 DCInputVoltage 0;
BA_ "GenSigTimeoutTime_SGW" SG_ 1046 DCInputVoltage 0;
BA_ "GenSigTimeoutTime_HCP" SG_ 1046 DCInputCurrent 0;
BA_ "GenSigTimeoutTime_PPIM" SG_ 1046 DCInputCurrent 0;
BA_ "GenSigTimeoutTime_APM2" SG_ 1046 DCInputCurrent 0;
BA_ "GenSigTimeoutTime_VDCM" SG_ 1046 DCInputCurrent 0;
BA_ "GenSigTimeoutTime_BPCM" SG_ 1046 DCInputCurrent 0;
BA_ "GenSigTimeoutTime_IDCM" SG_ 1046 DCInputCurrent 0;
BA_ "GenSigTimeoutTime_SGW" SG_ 1046 DCInputCurrent 0;
BA_ "GenSigTimeoutTime_HCP" SG_ 1046 ACOutput_Frequency 0;
BA_ "GenSigTimeoutTime_PPIM" SG_ 1046 ACOutput_Frequency 0;
BA_ "GenSigTimeoutTime_APM2" SG_ 1046 ACOutput_Frequency 0;
BA_ "GenSigTimeoutTime_VDCM" SG_ 1046 ACOutput_Frequency 0;
BA_ "GenSigTimeoutTime_BPCM" SG_ 1046 ACOutput_Frequency 0;
BA_ "GenSigTimeoutTime_IDCM" SG_ 1046 ACOutput_Frequency 0;
BA_ "GenSigTimeoutTime_SGW" SG_ 1046 ACOutput_Frequency 0;
BA_ "GenSigTimeoutTime_HCP" SG_ 1046 CRC_RPF_FD_1 0;
BA_ "GenSigTimeoutTime_PPIM" SG_ 1046 CRC_RPF_FD_1 0;
BA_ "GenSigTimeoutTime_BPCM" SG_ 1046 CRC_RPF_FD_1 0;
BA_ "GenSigTimeoutTime_IDCM" SG_ 1046 CRC_RPF_FD_1 0;
BA_ "GenSigTimeoutTime_SGW" SG_ 1046 CRC_RPF_FD_1 0;
BA_ "GenSigTimeoutTime_HCP" SG_ 1046 MC_RPF_FD_1 0;
BA_ "GenSigTimeoutTime_PPIM" SG_ 1046 MC_RPF_FD_1 0;
BA_ "GenSigTimeoutTime_BPCM" SG_ 1046 MC_RPF_FD_1 0;
BA_ "GenSigTimeoutTime_IDCM" SG_ 1046 MC_RPF_FD_1 0;
BA_ "GenSigTimeoutTime_SGW" SG_ 1046 MC_RPF_FD_1 0;
BA_ "GenSigTimeoutTime_HCP" SG_ 2654486592 SourceNodeIdentifier_1E384040 0;
BA_ "GenSigTimeoutTime_PPIM" SG_ 2654486592 SourceNodeIdentifier_1E384040 0;
BA_ "GenSigTimeoutTime_APM2" SG_ 2654486592 SourceNodeIdentifier_1E384040 0;
BA_ "GenSigTimeoutTime_VDCM" SG_ 2654486592 SourceNodeIdentifier_1E384040 0;
BA_ "GenSigTimeoutTime_BPCM" SG_ 2654486592 SourceNodeIdentifier_1E384040 0;
BA_ "GenSigTimeoutTime_EVCU2" SG_ 2654486592 SourceNodeIdentifier_1E384040 0;
BA_ "GenSigTimeoutTime_IDCM" SG_ 2654486592 SourceNodeIdentifier_1E384040 0;
BA_ "GenSigTimeoutTime_SGW" SG_ 2654486592 SourceNodeIdentifier_1E384040 0;
BA_ "GenSigTimeoutTime_HCP" SG_ 2654486592 CBV_bit1_1E384040 0;
BA_ "GenSigTimeoutTime_PPIM" SG_ 2654486592 CBV_bit1_1E384040 0;
BA_ "GenSigTimeoutTime_APM2" SG_ 2654486592 CBV_bit1_1E384040 0;
BA_ "GenSigTimeoutTime_VDCM" SG_ 2654486592 CBV_bit1_1E384040 0;
BA_ "GenSigTimeoutTime_BPCM" SG_ 2654486592 CBV_bit1_1E384040 0;
BA_ "GenSigTimeoutTime_EVCU2" SG_ 2654486592 CBV_bit1_1E384040 0;
BA_ "GenSigTimeoutTime_IDCM" SG_ 2654486592 CBV_bit1_1E384040 0;
BA_ "GenSigTimeoutTime_SGW" SG_ 2654486592 CBV_bit1_1E384040 0;
BA_ "GenSigTimeoutTime_HCP" SG_ 2654486592 CBV_bit0_RepeatMessageRequestBit_1E384040 0;
BA_ "GenSigTimeoutTime_PPIM" SG_ 2654486592 CBV_bit0_RepeatMessageRequestBit_1E384040 0;
BA_ "GenSigTimeoutTime_APM2" SG_ 2654486592 CBV_bit0_RepeatMessageRequestBit_1E384040 0;
BA_ "GenSigTimeoutTime_VDCM" SG_ 2654486592 CBV_bit0_RepeatMessageRequestBit_1E384040 0;
BA_ "GenSigTimeoutTime_BPCM" SG_ 2654486592 CBV_bit0_RepeatMessageRequestBit_1E384040 0;
BA_ "GenSigTimeoutTime_EVCU2" SG_ 2654486592 CBV_bit0_RepeatMessageRequestBit_1E384040 0;
BA_ "GenSigTimeoutTime_IDCM" SG_ 2654486592 CBV_bit0_RepeatMessageRequestBit_1E384040 0;
BA_ "GenSigTimeoutTime_SGW" SG_ 2654486592 CBV_bit0_RepeatMessageRequestBit_1E384040 0;
BA_ "GenSigTimeoutTime_HCP" SG_ 2654486592 CBV_bit2_1E384040 0;
BA_ "GenSigTimeoutTime_PPIM" SG_ 2654486592 CBV_bit2_1E384040 0;
BA_ "GenSigTimeoutTime_APM2" SG_ 2654486592 CBV_bit2_1E384040 0;
BA_ "GenSigTimeoutTime_VDCM" SG_ 2654486592 CBV_bit2_1E384040 0;
BA_ "GenSigTimeoutTime_BPCM" SG_ 2654486592 CBV_bit2_1E384040 0;
BA_ "GenSigTimeoutTime_EVCU2" SG_ 2654486592 CBV_bit2_1E384040 0;
BA_ "GenSigTimeoutTime_IDCM" SG_ 2654486592 CBV_bit2_1E384040 0;
BA_ "GenSigTimeoutTime_SGW" SG_ 2654486592 CBV_bit2_1E384040 0;
BA_ "GenSigTimeoutTime_HCP" SG_ 2654486592 CBV_bit3_NMCoordinatorBit_1E384040 0;
BA_ "GenSigTimeoutTime_PPIM" SG_ 2654486592 CBV_bit3_NMCoordinatorBit_1E384040 0;
BA_ "GenSigTimeoutTime_APM2" SG_ 2654486592 CBV_bit3_NMCoordinatorBit_1E384040 0;
BA_ "GenSigTimeoutTime_VDCM" SG_ 2654486592 CBV_bit3_NMCoordinatorBit_1E384040 0;
BA_ "GenSigTimeoutTime_BPCM" SG_ 2654486592 CBV_bit3_NMCoordinatorBit_1E384040 0;
BA_ "GenSigTimeoutTime_EVCU2" SG_ 2654486592 CBV_bit3_NMCoordinatorBit_1E384040 0;
BA_ "GenSigTimeoutTime_IDCM" SG_ 2654486592 CBV_bit3_NMCoordinatorBit_1E384040 0;
BA_ "GenSigTimeoutTime_SGW" SG_ 2654486592 CBV_bit3_NMCoordinatorBit_1E384040 0;
BA_ "GenSigTimeoutTime_HCP" SG_ 2654486592 CBV_bit7_1E384040 0;
BA_ "GenSigTimeoutTime_PPIM" SG_ 2654486592 CBV_bit7_1E384040 0;
BA_ "GenSigTimeoutTime_APM2" SG_ 2654486592 CBV_bit7_1E384040 0;
BA_ "GenSigTimeoutTime_VDCM" SG_ 2654486592 CBV_bit7_1E384040 0;
BA_ "GenSigTimeoutTime_BPCM" SG_ 2654486592 CBV_bit7_1E384040 0;
BA_ "GenSigTimeoutTime_EVCU2" SG_ 2654486592 CBV_bit7_1E384040 0;
BA_ "GenSigTimeoutTime_IDCM" SG_ 2654486592 CBV_bit7_1E384040 0;
BA_ "GenSigTimeoutTime_SGW" SG_ 2654486592 CBV_bit7_1E384040 0;
BA_ "GenSigTimeoutTime_HCP" SG_ 2654486592 CBV_bit6_PartialNtwInfBit_1E384040 0;
BA_ "GenSigTimeoutTime_PPIM" SG_ 2654486592 CBV_bit6_PartialNtwInfBit_1E384040 0;
BA_ "GenSigTimeoutTime_APM2" SG_ 2654486592 CBV_bit6_PartialNtwInfBit_1E384040 0;
BA_ "GenSigTimeoutTime_VDCM" SG_ 2654486592 CBV_bit6_PartialNtwInfBit_1E384040 0;
BA_ "GenSigTimeoutTime_BPCM" SG_ 2654486592 CBV_bit6_PartialNtwInfBit_1E384040 0;
BA_ "GenSigTimeoutTime_EVCU2" SG_ 2654486592 CBV_bit6_PartialNtwInfBit_1E384040 0;
BA_ "GenSigTimeoutTime_IDCM" SG_ 2654486592 CBV_bit6_PartialNtwInfBit_1E384040 0;
BA_ "GenSigTimeoutTime_SGW" SG_ 2654486592 CBV_bit6_PartialNtwInfBit_1E384040 0;
BA_ "GenSigTimeoutTime_HCP" SG_ 2654486592 CBV_bit5_1E384040 0;
BA_ "GenSigTimeoutTime_PPIM" SG_ 2654486592 CBV_bit5_1E384040 0;
BA_ "GenSigTimeoutTime_APM2" SG_ 2654486592 CBV_bit5_1E384040 0;
BA_ "GenSigTimeoutTime_VDCM" SG_ 2654486592 CBV_bit5_1E384040 0;
BA_ "GenSigTimeoutTime_BPCM" SG_ 2654486592 CBV_bit5_1E384040 0;
BA_ "GenSigTimeoutTime_EVCU2" SG_ 2654486592 CBV_bit5_1E384040 0;
BA_ "GenSigTimeoutTime_IDCM" SG_ 2654486592 CBV_bit5_1E384040 0;
BA_ "GenSigTimeoutTime_SGW" SG_ 2654486592 CBV_bit5_1E384040 0;
BA_ "GenSigTimeoutTime_HCP" SG_ 2654486592 CBV_bit4_ActiveWakeupBit_1E384040 0;
BA_ "GenSigTimeoutTime_PPIM" SG_ 2654486592 CBV_bit4_ActiveWakeupBit_1E384040 0;
BA_ "GenSigTimeoutTime_APM2" SG_ 2654486592 CBV_bit4_ActiveWakeupBit_1E384040 0;
BA_ "GenSigTimeoutTime_VDCM" SG_ 2654486592 CBV_bit4_ActiveWakeupBit_1E384040 0;
BA_ "GenSigTimeoutTime_BPCM" SG_ 2654486592 CBV_bit4_ActiveWakeupBit_1E384040 0;
BA_ "GenSigTimeoutTime_EVCU2" SG_ 2654486592 CBV_bit4_ActiveWakeupBit_1E384040 0;
BA_ "GenSigTimeoutTime_IDCM" SG_ 2654486592 CBV_bit4_ActiveWakeupBit_1E384040 0;
BA_ "GenSigTimeoutTime_SGW" SG_ 2654486592 CBV_bit4_ActiveWakeupBit_1E384040 0;
BA_ "GenSigTimeoutTime_HCP" SG_ 1041 ISO15118_EVCCID 0;
BA_ "GenSigTimeoutTime_PPIM" SG_ 1041 ISO15118_EVCCID 0;
BA_ "GenSigTimeoutTime_APM2" SG_ 1041 ISO15118_EVCCID 0;
BA_ "GenSigTimeoutTime_VDCM" SG_ 1041 ISO15118_EVCCID 0;
BA_ "GenSigTimeoutTime_HCP" SG_ 1041 SelectionParameterSetID 0;
BA_ "GenSigTimeoutTime_PPIM" SG_ 1041 SelectionParameterSetID 0;
BA_ "GenSigTimeoutTime_APM2" SG_ 1041 SelectionParameterSetID 0;
BA_ "GenSigTimeoutTime_VDCM" SG_ 1041 SelectionParameterSetID 0;
BA_ "GenSigTimeoutTime_HCP" SG_ 1041 Protocol_Priority3 0;
BA_ "GenSigTimeoutTime_PPIM" SG_ 1041 Protocol_Priority3 0;
BA_ "GenSigTimeoutTime_APM2" SG_ 1041 Protocol_Priority3 0;
BA_ "GenSigTimeoutTime_VDCM" SG_ 1041 Protocol_Priority3 0;
BA_ "GenSigTimeoutTime_VDCM" SG_ 1041 Protocol_Priority2 0;
BA_ "GenSigTimeoutTime_HCP" SG_ 1041 Protocol_Priority2 0;
BA_ "GenSigTimeoutTime_PPIM" SG_ 1041 Protocol_Priority2 0;
BA_ "GenSigTimeoutTime_APM2" SG_ 1041 Protocol_Priority2 0;
BA_ "GenSigTimeoutTime_HCP" SG_ 1041 Protocol_Priority1 0;
BA_ "GenSigTimeoutTime_PPIM" SG_ 1041 Protocol_Priority1 0;
BA_ "GenSigTimeoutTime_APM2" SG_ 1041 Protocol_Priority1 0;
BA_ "GenSigTimeoutTime_VDCM" SG_ 1041 Protocol_Priority1 0;
BA_ "GenSigTimeoutTime_HCP" SG_ 1041 MaxEntriesSASScheduleTuple 0;
BA_ "GenSigTimeoutTime_PPIM" SG_ 1041 MaxEntriesSASScheduleTuple 0;
BA_ "GenSigTimeoutTime_APM2" SG_ 1041 MaxEntriesSASScheduleTuple 0;
BA_ "GenSigTimeoutTime_VDCM" SG_ 1041 MaxEntriesSASScheduleTuple 0;
BA_ "GenSigTimeoutTime_HCP" SG_ 1041 ISO15118_TLS_Connected 0;
BA_ "GenSigTimeoutTime_PPIM" SG_ 1041 ISO15118_TLS_Connected 0;
BA_ "GenSigTimeoutTime_APM2" SG_ 1041 ISO15118_TLS_Connected 0;
BA_ "GenSigTimeoutTime_VDCM" SG_ 1041 ISO15118_TLS_Connected 0;
BA_ "GenSigTimeoutTime_BPCM" SG_ 1041 ISO15118_TimeToBulkSOC 0;
BA_ "GenSigTimeoutTime_EVCU2" SG_ 1041 ISO15118_TimeToBulkSOC 0;
BA_ "GenSigTimeoutTime_SGW" SG_ 1041 ISO15118_TimeToBulkSOC 0;
BA_ "GenSigTimeoutTime_HCP" SG_ 1041 ISO15118_TimeToBulkSOC 0;
BA_ "GenSigTimeoutTime_PPIM" SG_ 1041 ISO15118_TimeToBulkSOC 0;
BA_ "GenSigTimeoutTime_APM2" SG_ 1041 ISO15118_TimeToBulkSOC 0;
BA_ "GenSigTimeoutTime_VDCM" SG_ 1041 ISO15118_TimeToBulkSOC 0;
BA_ "GenSigTimeoutTime_BPCM" SG_ 1041 ISO15118_EVEnergyRequest 0;
BA_ "GenSigTimeoutTime_EVCU2" SG_ 1041 ISO15118_EVEnergyRequest 0;
BA_ "GenSigTimeoutTime_SGW" SG_ 1041 ISO15118_EVEnergyRequest 0;
BA_ "GenSigTimeoutTime_HCP" SG_ 1041 ISO15118_EVEnergyRequest 0;
BA_ "GenSigTimeoutTime_PPIM" SG_ 1041 ISO15118_EVEnergyRequest 0;
BA_ "GenSigTimeoutTime_APM2" SG_ 1041 ISO15118_EVEnergyRequest 0;
BA_ "GenSigTimeoutTime_VDCM" SG_ 1041 ISO15118_EVEnergyRequest 0;
BA_ "GenSigTimeoutTime_BPCM" SG_ 1041 ISO15118_EVErrorCode 0;
BA_ "GenSigTimeoutTime_EVCU2" SG_ 1041 ISO15118_EVErrorCode 0;
BA_ "GenSigTimeoutTime_SGW" SG_ 1041 ISO15118_EVErrorCode 0;
BA_ "GenSigTimeoutTime_HCP" SG_ 1041 ISO15118_EVErrorCode 0;
BA_ "GenSigTimeoutTime_PPIM" SG_ 1041 ISO15118_EVErrorCode 0;
BA_ "GenSigTimeoutTime_APM2" SG_ 1041 ISO15118_EVErrorCode 0;
BA_ "GenSigTimeoutTime_VDCM" SG_ 1041 ISO15118_EVErrorCode 0;
BA_ "GenSigTimeoutTime_BPCM" SG_ 1041 ISO15118_SessionID 0;
BA_ "GenSigTimeoutTime_EVCU2" SG_ 1041 ISO15118_SessionID 0;
BA_ "GenSigTimeoutTime_SGW" SG_ 1041 ISO15118_SessionID 0;
BA_ "GenSigTimeoutTime_HCP" SG_ 1041 ISO15118_SessionID 0;
BA_ "GenSigTimeoutTime_PPIM" SG_ 1041 ISO15118_SessionID 0;
BA_ "GenSigTimeoutTime_APM2" SG_ 1041 ISO15118_SessionID 0;
BA_ "GenSigTimeoutTime_VDCM" SG_ 1041 ISO15118_SessionID 0;
BA_ "GenSigTimeoutTime_HCP" SG_ 1041 ISO15118_TimeToFullSOC 0;
BA_ "GenSigTimeoutTime_PPIM" SG_ 1041 ISO15118_TimeToFullSOC 0;
BA_ "GenSigTimeoutTime_APM2" SG_ 1041 ISO15118_TimeToFullSOC 0;
BA_ "GenSigTimeoutTime_VDCM" SG_ 1041 ISO15118_TimeToFullSOC 0;
BA_ "GenSigTimeoutTime_BPCM" SG_ 1041 ISO15118_EVEnergyCapacity 0;
BA_ "GenSigTimeoutTime_EVCU2" SG_ 1041 ISO15118_EVEnergyCapacity 0;
BA_ "GenSigTimeoutTime_SGW" SG_ 1041 ISO15118_EVEnergyCapacity 0;
BA_ "GenSigTimeoutTime_HCP" SG_ 1041 ISO15118_EVEnergyCapacity 0;
BA_ "GenSigTimeoutTime_PPIM" SG_ 1041 ISO15118_EVEnergyCapacity 0;
BA_ "GenSigTimeoutTime_APM2" SG_ 1041 ISO15118_EVEnergyCapacity 0;
BA_ "GenSigTimeoutTime_VDCM" SG_ 1041 ISO15118_EVEnergyCapacity 0;
BA_ "GenSigTimeoutTime_HCP" SG_ 1041 ISO15118_DepartureTime 0;
BA_ "GenSigTimeoutTime_PPIM" SG_ 1041 ISO15118_DepartureTime 0;
BA_ "GenSigTimeoutTime_APM2" SG_ 1041 ISO15118_DepartureTime 0;
BA_ "GenSigTimeoutTime_VDCM" SG_ 1041 ISO15118_DepartureTime 0;
BA_ "GenSigTimeoutTime_HCP" SG_ 1041 ISO15118_ChargeSession 0;
BA_ "GenSigTimeoutTime_PPIM" SG_ 1041 ISO15118_ChargeSession 0;
BA_ "GenSigTimeoutTime_APM2" SG_ 1041 ISO15118_ChargeSession 0;
BA_ "GenSigTimeoutTime_VDCM" SG_ 1041 ISO15118_ChargeSession 0;
BA_ "GenSigTimeoutTime_HCP" SG_ 1041 ISO15118_ChargeProgress 0;
BA_ "GenSigTimeoutTime_PPIM" SG_ 1041 ISO15118_ChargeProgress 0;
BA_ "GenSigTimeoutTime_APM2" SG_ 1041 ISO15118_ChargeProgress 0;
BA_ "GenSigTimeoutTime_VDCM" SG_ 1041 ISO15118_ChargeProgress 0;
BA_ "GenSigTimeoutTime_HCP" SG_ 1041 EVMaxVoltage 0;
BA_ "GenSigTimeoutTime_PPIM" SG_ 1041 EVMaxVoltage 0;
BA_ "GenSigTimeoutTime_APM2" SG_ 1041 EVMaxVoltage 0;
BA_ "GenSigTimeoutTime_VDCM" SG_ 1041 EVMaxVoltage 0;
BA_ "GenSigTimeoutTime_HCP" SG_ 1041 Protocol_Namespace_Priority_1 0;
BA_ "GenSigTimeoutTime_PPIM" SG_ 1041 Protocol_Namespace_Priority_1 0;
BA_ "GenSigTimeoutTime_APM2" SG_ 1041 Protocol_Namespace_Priority_1 0;
BA_ "GenSigTimeoutTime_HCP" SG_ 1041 Protocol_Namespace_Priority_2 0;
BA_ "GenSigTimeoutTime_PPIM" SG_ 1041 Protocol_Namespace_Priority_2 0;
BA_ "GenSigTimeoutTime_APM2" SG_ 1041 Protocol_Namespace_Priority_2 0;
BA_ "GenSigTimeoutTime_HCP" SG_ 1041 CRC_EVCU_ISO15118_STATUS1 0;
BA_ "GenSigTimeoutTime_PPIM" SG_ 1041 CRC_EVCU_ISO15118_STATUS1 0;
BA_ "GenSigTimeoutTime_APM2" SG_ 1041 CRC_EVCU_ISO15118_STATUS1 0;
BA_ "GenSigTimeoutTime_HCP" SG_ 1041 MC_EVCU_ISO15118_STATUS1 0;
BA_ "GenSigTimeoutTime_PPIM" SG_ 1041 MC_EVCU_ISO15118_STATUS1 0;
BA_ "GenSigTimeoutTime_APM2" SG_ 1041 MC_EVCU_ISO15118_STATUS1 0;
BA_ "GenSigTimeoutTime_HCP" SG_ 1041 Eamount 0;
BA_ "GenSigTimeoutTime_PPIM" SG_ 1041 Eamount 0;
BA_ "GenSigTimeoutTime_APM2" SG_ 1041 Eamount 0;
BA_ "GenSigTimeoutTime_VDCM" SG_ 1041 Eamount 0;
BA_ "GenSigTimeoutTime_HCP" SG_ 1041 EVMaxCurrent 0;
BA_ "GenSigTimeoutTime_PPIM" SG_ 1041 EVMaxCurrent 0;
BA_ "GenSigTimeoutTime_APM2" SG_ 1041 EVMaxCurrent 0;
BA_ "GenSigTimeoutTime_VDCM" SG_ 1041 EVMaxCurrent 0;
BA_ "GenSigTimeoutTime_HCP" SG_ 1044 LID_Status_240V_Socket 0;
BA_ "GenSigTimeoutTime_PPIM" SG_ 1044 LID_Status_240V_Socket 0;
BA_ "GenSigTimeoutTime_BPCM" SG_ 1044 LID_Status_240V_Socket 0;
BA_ "GenSigTimeoutTime_EVCU2" SG_ 1044 LID_Status_240V_Socket 0;
BA_ "GenSigTimeoutTime_SGW" SG_ 1044 LID_Status_240V_Socket 0;
BA_ "GenSigTimeoutTime_HCP" SG_ 1044 MC_HYBRID_DISPLAY2 0;
BA_ "GenSigTimeoutTime_IDCM" SG_ 1044 MC_HYBRID_DISPLAY2 0;
BA_ "GenSigTimeoutTime_BPCM" SG_ 1044 MC_HYBRID_DISPLAY2 0;
BA_ "GenSigTimeoutTime_EVCU2" SG_ 1044 MC_HYBRID_DISPLAY2 0;
BA_ "GenSigTimeoutTime_SGW" SG_ 1044 MC_HYBRID_DISPLAY2 0;
BA_ "GenSigTimeoutTime_HCP" SG_ 1044 Max_Allwd_AC_Output_Current_L1 0;
BA_ "GenSigTimeoutTime_PPIM" SG_ 1044 Max_Allwd_AC_Output_Current_L1 0;
BA_ "GenSigTimeoutTime_APM2" SG_ 1044 Max_Allwd_AC_Output_Current_L1 0;
BA_ "GenSigTimeoutTime_VDCM" SG_ 1044 Max_Allwd_AC_Output_Current_L1 0;
BA_ "GenSigTimeoutTime_BPCM" SG_ 1044 Max_Allwd_AC_Output_Current_L1 0;
BA_ "GenSigTimeoutTime_EVCU2" SG_ 1044 Max_Allwd_AC_Output_Current_L1 0;
BA_ "GenSigTimeoutTime_SGW" SG_ 1044 Max_Allwd_AC_Output_Current_L1 0;
BA_ "GenSigTimeoutTime_HCP" SG_ 1044 LID_Status_120V_Socket_B 0;
BA_ "GenSigTimeoutTime_PPIM" SG_ 1044 LID_Status_120V_Socket_B 0;
BA_ "GenSigTimeoutTime_BPCM" SG_ 1044 LID_Status_120V_Socket_B 0;
BA_ "GenSigTimeoutTime_EVCU2" SG_ 1044 LID_Status_120V_Socket_B 0;
BA_ "GenSigTimeoutTime_SGW" SG_ 1044 LID_Status_120V_Socket_B 0;
BA_ "GenSigTimeoutTime_HCP" SG_ 1044 LID_Status_120V_Socket_A 0;
BA_ "GenSigTimeoutTime_PPIM" SG_ 1044 LID_Status_120V_Socket_A 0;
BA_ "GenSigTimeoutTime_BPCM" SG_ 1044 LID_Status_120V_Socket_A 0;
BA_ "GenSigTimeoutTime_EVCU2" SG_ 1044 LID_Status_120V_Socket_A 0;
BA_ "GenSigTimeoutTime_SGW" SG_ 1044 LID_Status_120V_Socket_A 0;
BA_ "GenSigTimeoutTime_HCP" SG_ 1044 CRC_HYBRID_DISPLAY2 0;
BA_ "GenSigTimeoutTime_IDCM" SG_ 1044 CRC_HYBRID_DISPLAY2 0;
BA_ "GenSigTimeoutTime_BPCM" SG_ 1044 CRC_HYBRID_DISPLAY2 0;
BA_ "GenSigTimeoutTime_EVCU2" SG_ 1044 CRC_HYBRID_DISPLAY2 0;
BA_ "GenSigTimeoutTime_SGW" SG_ 1044 CRC_HYBRID_DISPLAY2 0;
BA_ "GenSigTimeoutTime_HCP" SG_ 1044 DischargingSysStatus 0;
BA_ "GenSigTimeoutTime_IDCM" SG_ 1044 DischargingSysStatus 0;
BA_ "GenSigTimeoutTime_BPCM" SG_ 1044 DischargingSysStatus 0;
BA_ "GenSigTimeoutTime_EVCU2" SG_ 1044 DischargingSysStatus 0;
BA_ "GenSigTimeoutTime_SGW" SG_ 1044 DischargingSysStatus 0;
BA_ "GenSigTimeoutTime_HCP" SG_ 1044 Max_Allwd_AC_Output_Voltage_L1 0;
BA_ "GenSigTimeoutTime_PPIM" SG_ 1044 Max_Allwd_AC_Output_Voltage_L1 0;
BA_ "GenSigTimeoutTime_APM2" SG_ 1044 Max_Allwd_AC_Output_Voltage_L1 0;
BA_ "GenSigTimeoutTime_VDCM" SG_ 1044 Max_Allwd_AC_Output_Voltage_L1 0;
BA_ "GenSigTimeoutTime_BPCM" SG_ 1044 Max_Allwd_AC_Output_Voltage_L1 0;
BA_ "GenSigTimeoutTime_EVCU2" SG_ 1044 Max_Allwd_AC_Output_Voltage_L1 0;
BA_ "GenSigTimeoutTime_SGW" SG_ 1044 Max_Allwd_AC_Output_Voltage_L1 0;
BA_ "GenSigTimeoutTime_HCP" SG_ 1041 EVMinCurrent 0;
BA_ "GenSigTimeoutTime_PPIM" SG_ 1041 EVMinCurrent 0;
BA_ "GenSigTimeoutTime_APM2" SG_ 1041 EVMinCurrent 0;
BA_ "GenSigTimeoutTime_VDCM" SG_ 1041 EVMinCurrent 0;
BA_ "GenSigTimeoutTime_HCP" SG_ 1041 Protocol_Namespace_Priority_3 0;
BA_ "GenSigTimeoutTime_PPIM" SG_ 1041 Protocol_Namespace_Priority_3 0;
BA_ "GenSigTimeoutTime_APM2" SG_ 1041 Protocol_Namespace_Priority_3 0;
BA_ "GenSigTimeoutTime_HCP" SG_ 1041 Protocol_Namespace_Priority_4 0;
BA_ "GenSigTimeoutTime_PPIM" SG_ 1041 Protocol_Namespace_Priority_4 0;
BA_ "GenSigTimeoutTime_APM2" SG_ 1041 Protocol_Namespace_Priority_4 0;
BA_ "GenSigTimeoutTime_BPCM" SG_ 1042 EVSE_Offered_DC_Unique 0;
BA_ "GenSigTimeoutTime_IDCM" SG_ 1042 EVSE_Offered_DC_Unique 0;
BA_ "GenSigTimeoutTime_SGW" SG_ 1042 EVSE_Offered_DC_Unique 0;
BA_ "GenSigTimeoutTime_BPCM" SG_ 1042 V2X_EVSE_Service_5_Free 0;
BA_ "GenSigTimeoutTime_IDCM" SG_ 1042 V2X_EVSE_Service_5_Free 0;
BA_ "GenSigTimeoutTime_SGW" SG_ 1042 V2X_EVSE_Service_5_Free 0;
BA_ "GenSigTimeoutTime_BPCM" SG_ 1042 V2X_EVSE_Service_6_Free 0;
BA_ "GenSigTimeoutTime_IDCM" SG_ 1042 V2X_EVSE_Service_6_Free 0;
BA_ "GenSigTimeoutTime_SGW" SG_ 1042 V2X_EVSE_Service_6_Free 0;
BA_ "GenSigTimeoutTime_BPCM" SG_ 1042 EVSE_Offered_DC_Combo_Core 0;
BA_ "GenSigTimeoutTime_IDCM" SG_ 1042 EVSE_Offered_DC_Combo_Core 0;
BA_ "GenSigTimeoutTime_SGW" SG_ 1042 EVSE_Offered_DC_Combo_Core 0;
BA_ "GenSigTimeoutTime_BPCM" SG_ 1042 EVSE_Offered_AC_Three_Phase 0;
BA_ "GenSigTimeoutTime_IDCM" SG_ 1042 EVSE_Offered_AC_Three_Phase 0;
BA_ "GenSigTimeoutTime_SGW" SG_ 1042 EVSE_Offered_AC_Three_Phase 0;
BA_ "GenSigTimeoutTime_BPCM" SG_ 1042 EVSE_Offered_AC_Single_Phase 0;
BA_ "GenSigTimeoutTime_IDCM" SG_ 1042 EVSE_Offered_AC_Single_Phase 0;
BA_ "GenSigTimeoutTime_SGW" SG_ 1042 EVSE_Offered_AC_Single_Phase 0;
BA_ "GenSigTimeoutTime_BPCM" SG_ 1042 Contract_Certificate_Present 0;
BA_ "GenSigTimeoutTime_IDCM" SG_ 1042 Contract_Certificate_Present 0;
BA_ "GenSigTimeoutTime_SGW" SG_ 1042 Contract_Certificate_Present 0;
BA_ "GenSigTimeoutTime_BPCM" SG_ 1042 EVSE_Offered_DC_Extended 0;
BA_ "GenSigTimeoutTime_IDCM" SG_ 1042 EVSE_Offered_DC_Extended 0;
BA_ "GenSigTimeoutTime_SGW" SG_ 1042 EVSE_Offered_DC_Extended 0;
BA_ "GenSigTimeoutTime_BPCM" SG_ 1042 EVSE_Offered_DC_Core 0;
BA_ "GenSigTimeoutTime_IDCM" SG_ 1042 EVSE_Offered_DC_Core 0;
BA_ "GenSigTimeoutTime_SGW" SG_ 1042 EVSE_Offered_DC_Core 0;
BA_ "GenSigTimeoutTime_BPCM" SG_ 1042 MC_IDCM_ISO15118_STATUS1 0;
BA_ "GenSigTimeoutTime_IDCM" SG_ 1042 MC_IDCM_ISO15118_STATUS1 0;
BA_ "GenSigTimeoutTime_SGW" SG_ 1042 MC_IDCM_ISO15118_STATUS1 0;
BA_ "GenSigTimeoutTime_BPCM" SG_ 1042 CRC_IDCM_ISO15118_STATUS1 0;
BA_ "GenSigTimeoutTime_IDCM" SG_ 1042 CRC_IDCM_ISO15118_STATUS1 0;
BA_ "GenSigTimeoutTime_SGW" SG_ 1042 CRC_IDCM_ISO15118_STATUS1 0;
BA_ "GenSigTimeoutTime_HCP" SG_ 216 EVCU_Resp_AUX_LoadTurned_Off 0;
BA_ "GenSigTimeoutTime_PPIM" SG_ 216 EVCU_Resp_AUX_LoadTurned_Off 0;
BA_ "GenSigTimeoutTime_EVCU2" SG_ 216 EVCU_Resp_AUX_LoadTurned_Off 0;
BA_ "GenSigTimeoutTime_IDCM" SG_ 216 EVCU_Resp_AUX_LoadTurned_Off 0;
BA_ "GenSigTimeoutTime_SGW" SG_ 216 EVCU_Resp_AUX_LoadTurned_Off 0;
BA_ "GenSigTimeoutTime_VDCM" SG_ 216 APM2_ModeRequest_PT 0;
BA_ "GenSigTimeoutTime_BPCM" SG_ 216 APM2_ModeRequest_PT 0;
BA_ "GenSigTimeoutTime_EVCU2" SG_ 216 APM2_ModeRequest_PT 0;
BA_ "GenSigTimeoutTime_IDCM" SG_ 216 APM2_ModeRequest_PT 0;
BA_ "GenSigTimeoutTime_SGW" SG_ 216 APM2_ModeRequest_PT 0;
BA_ "GenSigTimeoutTime_HCP" SG_ 216 DC_Charge_Type_Command 0;
BA_ "GenSigTimeoutTime_PPIM" SG_ 216 DC_Charge_Type_Command 0;
BA_ "GenSigTimeoutTime_EVCU2" SG_ 216 DC_Charge_Type_Command 0;
BA_ "GenSigTimeoutTime_IDCM" SG_ 216 DC_Charge_Type_Command 0;
BA_ "GenSigTimeoutTime_SGW" SG_ 216 DC_Charge_Type_Command 0;
BA_ "GenSigTimeoutTime_BPCM" SG_ 216 APM2ActDischRq_PT 0;
BA_ "GenSigTimeoutTime_EVCU2" SG_ 216 APM2ActDischRq_PT 0;
BA_ "GenSigTimeoutTime_IDCM" SG_ 216 APM2ActDischRq_PT 0;
BA_ "GenSigTimeoutTime_SGW" SG_ 216 APM2ActDischRq_PT 0;
BA_ "GenSigTimeoutTime_VDCM" SG_ 216 APM2ActDischRq_PT 0;
BA_ "GenSigTimeoutTime_VDCM" SG_ 216 APM2_EVSEBusVoltSetPoint_PT 0;
BA_ "GenSigTimeoutTime_BPCM" SG_ 216 APM2_EVSEBusVoltSetPoint_PT 0;
BA_ "GenSigTimeoutTime_EVCU2" SG_ 216 APM2_EVSEBusVoltSetPoint_PT 0;
BA_ "GenSigTimeoutTime_IDCM" SG_ 216 APM2_EVSEBusVoltSetPoint_PT 0;
BA_ "GenSigTimeoutTime_SGW" SG_ 216 APM2_EVSEBusVoltSetPoint_PT 0;
BA_ "GenSigTimeoutTime_VDCM" SG_ 216 APM2_EVSEBusPrechargeReq_PT 0;
BA_ "GenSigTimeoutTime_BPCM" SG_ 216 APM2_EVSEBusPrechargeReq_PT 0;
BA_ "GenSigTimeoutTime_EVCU2" SG_ 216 APM2_EVSEBusPrechargeReq_PT 0;
BA_ "GenSigTimeoutTime_IDCM" SG_ 216 APM2_EVSEBusPrechargeReq_PT 0;
BA_ "GenSigTimeoutTime_SGW" SG_ 216 APM2_EVSEBusPrechargeReq_PT 0;
BA_ "GenSigTimeoutTime_VDCM" SG_ 216 APM2_BoostSwitchControl 0;
BA_ "GenSigTimeoutTime_BPCM" SG_ 216 APM2_BoostSwitchControl 0;
BA_ "GenSigTimeoutTime_EVCU2" SG_ 216 APM2_BoostSwitchControl 0;
BA_ "GenSigTimeoutTime_IDCM" SG_ 216 APM2_BoostSwitchControl 0;
BA_ "GenSigTimeoutTime_SGW" SG_ 216 APM2_BoostSwitchControl 0;
BA_ "GenSigTimeoutTime_BPCM" SG_ 1042 EVSE_Service4_UseCaseInfo 0;
BA_ "GenSigTimeoutTime_IDCM" SG_ 1042 EVSE_Service4_UseCaseInfo 0;
BA_ "GenSigTimeoutTime_SGW" SG_ 1042 EVSE_Service4_UseCaseInfo 0;
BA_ "GenSigTimeoutTime_BPCM" SG_ 1042 EVSE_Service4_Free 0;
BA_ "GenSigTimeoutTime_IDCM" SG_ 1042 EVSE_Service4_Free 0;
BA_ "GenSigTimeoutTime_SGW" SG_ 1042 EVSE_Service4_Free 0;
BA_ "GenSigTimeoutTime_BPCM" SG_ 1042 EVSE_Service3_Internet 0;
BA_ "GenSigTimeoutTime_IDCM" SG_ 1042 EVSE_Service3_Internet 0;
BA_ "GenSigTimeoutTime_SGW" SG_ 1042 EVSE_Service3_Internet 0;
BA_ "GenSigTimeoutTime_BPCM" SG_ 1042 EVSE_Service3_Free 0;
BA_ "GenSigTimeoutTime_IDCM" SG_ 1042 EVSE_Service3_Free 0;
BA_ "GenSigTimeoutTime_SGW" SG_ 1042 EVSE_Service3_Free 0;
BA_ "GenSigTimeoutTime_BPCM" SG_ 1042 EVSE_Service2_Free 0;
BA_ "GenSigTimeoutTime_IDCM" SG_ 1042 EVSE_Service2_Free 0;
BA_ "GenSigTimeoutTime_SGW" SG_ 1042 EVSE_Service2_Free 0;
BA_ "GenSigTimeoutTime_BPCM" SG_ 1042 EVSE_Service2_Certificates 0;
BA_ "GenSigTimeoutTime_IDCM" SG_ 1042 EVSE_Service2_Certificates 0;
BA_ "GenSigTimeoutTime_SGW" SG_ 1042 EVSE_Service2_Certificates 0;
BA_ "GenSigTimeoutTime_BPCM" SG_ 1042 EVSE_Service1_Free 0;
BA_ "GenSigTimeoutTime_IDCM" SG_ 1042 EVSE_Service1_Free 0;
BA_ "GenSigTimeoutTime_SGW" SG_ 1042 EVSE_Service1_Free 0;
BA_ "GenSigTimeoutTime_BPCM" SG_ 1042 EVSE_Service1_Charging 0;
BA_ "GenSigTimeoutTime_IDCM" SG_ 1042 EVSE_Service1_Charging 0;
BA_ "GenSigTimeoutTime_SGW" SG_ 1042 EVSE_Service1_Charging 0;
BA_ "GenSigTimeoutTime_BPCM" SG_ 1042 ISO15118_MessageResponse 0;
BA_ "GenSigTimeoutTime_IDCM" SG_ 1042 ISO15118_MessageResponse 0;
BA_ "GenSigTimeoutTime_SGW" SG_ 1042 ISO15118_MessageResponse 0;
BA_ "GenSigTimeoutTime_BPCM" SG_ 1042 ISO15118_EVSETimeStamp 0;
BA_ "GenSigTimeoutTime_IDCM" SG_ 1042 ISO15118_EVSETimeStamp 0;
BA_ "GenSigTimeoutTime_SGW" SG_ 1042 ISO15118_EVSETimeStamp 0;
BA_ "GenSigTimeoutTime_BPCM" SG_ 1042 ISO15118_EVCC_ActionRequest 0;
BA_ "GenSigTimeoutTime_IDCM" SG_ 1042 ISO15118_EVCC_ActionRequest 0;
BA_ "GenSigTimeoutTime_SGW" SG_ 1042 ISO15118_EVCC_ActionRequest 0;
BA_ "GenSigTimeoutTime_BPCM" SG_ 1042 ISO15118_EnergyToDeliver 0;
BA_ "GenSigTimeoutTime_IDCM" SG_ 1042 ISO15118_EnergyToDeliver 0;
BA_ "GenSigTimeoutTime_SGW" SG_ 1042 ISO15118_EnergyToDeliver 0;
BA_ "GenSigTimeoutTime_BPCM" SG_ 1042 ISO15118_PMax 0;
BA_ "GenSigTimeoutTime_IDCM" SG_ 1042 ISO15118_PMax 0;
BA_ "GenSigTimeoutTime_SGW" SG_ 1042 ISO15118_PMax 0;
BA_ "GenSigTimeoutTime_BPCM" SG_ 1042 ISO15118_NotificationMaxDelay 0;
BA_ "GenSigTimeoutTime_IDCM" SG_ 1042 ISO15118_NotificationMaxDelay 0;
BA_ "GenSigTimeoutTime_SGW" SG_ 1042 ISO15118_NotificationMaxDelay 0;
BA_ "GenSigTimeoutTime_BPCM" SG_ 1042 ISO15118_PMaxScheduleID 0;
BA_ "GenSigTimeoutTime_IDCM" SG_ 1042 ISO15118_PMaxScheduleID 0;
BA_ "GenSigTimeoutTime_SGW" SG_ 1042 ISO15118_PMaxScheduleID 0;
BA_ "GenSigTimeoutTime_BPCM" SG_ 1042 PMax_RelDuration_Interval 0;
BA_ "GenSigTimeoutTime_IDCM" SG_ 1042 PMax_RelDuration_Interval 0;
BA_ "GenSigTimeoutTime_SGW" SG_ 1042 PMax_RelDuration_Interval 0;
BA_ "GenSigTimeoutTime_BPCM" SG_ 1042 ParameterID_Update 0;
BA_ "GenSigTimeoutTime_IDCM" SG_ 1042 ParameterID_Update 0;
BA_ "GenSigTimeoutTime_SGW" SG_ 1042 ParameterID_Update 0;
BA_ "GenSigTimeoutTime_BPCM" SG_ 1042 ParameterID_Installation 0;
BA_ "GenSigTimeoutTime_IDCM" SG_ 1042 ParameterID_Installation 0;
BA_ "GenSigTimeoutTime_SGW" SG_ 1042 ParameterID_Installation 0;
BA_ "GenSigTimeoutTime_BPCM" SG_ 1042 ISO15118_VersionNumMinor 0;
BA_ "GenSigTimeoutTime_IDCM" SG_ 1042 ISO15118_VersionNumMinor 0;
BA_ "GenSigTimeoutTime_SGW" SG_ 1042 ISO15118_VersionNumMinor 0;
BA_ "GenSigTimeoutTime_BPCM" SG_ 1042 ISO15118_VersionNumMajor 0;
BA_ "GenSigTimeoutTime_IDCM" SG_ 1042 ISO15118_VersionNumMajor 0;
BA_ "GenSigTimeoutTime_SGW" SG_ 1042 ISO15118_VersionNumMajor 0;
BA_ "GenSigTimeoutTime_BPCM" SG_ 1042 ISO15118_TLS_Status 0;
BA_ "GenSigTimeoutTime_IDCM" SG_ 1042 ISO15118_TLS_Status 0;
BA_ "GenSigTimeoutTime_SGW" SG_ 1042 ISO15118_TLS_Status 0;
BA_ "GenSigTimeoutTime_BPCM" SG_ 1042 PMax_RelStart_Interval 0;
BA_ "GenSigTimeoutTime_IDCM" SG_ 1042 PMax_RelStart_Interval 0;
BA_ "GenSigTimeoutTime_SGW" SG_ 1042 PMax_RelStart_Interval 0;
BA_ "GenSigTimeoutTime_SGW" SG_ 1042 ISO15118_TLS_Offered 0;
BA_ "GenSigTimeoutTime_BPCM" SG_ 1042 ISO15118_ResponseCode 0;
BA_ "GenSigTimeoutTime_IDCM" SG_ 1042 ISO15118_ResponseCode 0;
BA_ "GenSigTimeoutTime_SGW" SG_ 1042 ISO15118_ResponseCode 0;
BA_ "GenSigTimeoutTime_HCP" SG_ 216 APM_LV_VActual_PT 0;
BA_ "GenSigTimeoutTime_PPIM" SG_ 216 APM_LV_VActual_PT 0;
BA_ "GenSigTimeoutTime_APM2" SG_ 216 APM_LV_VActual_PT 0;
BA_ "GenSigTimeoutTime_VDCM" SG_ 216 APM2_TypeCtrl_PT 0;
BA_ "GenSigTimeoutTime_BPCM" SG_ 216 APM2_TypeCtrl_PT 0;
BA_ "GenSigTimeoutTime_EVCU2" SG_ 216 APM2_TypeCtrl_PT 0;
BA_ "GenSigTimeoutTime_IDCM" SG_ 216 APM2_TypeCtrl_PT 0;
BA_ "GenSigTimeoutTime_SGW" SG_ 216 APM2_TypeCtrl_PT 0;
BA_ "GenSigTimeoutTime_HCP" SG_ 216 BMS_HV_RefTracHVBus_V_Vldty_PT 0;
BA_ "GenSigTimeoutTime_PPIM" SG_ 216 BMS_HV_RefTracHVBus_V_Vldty_PT 0;
BA_ "GenSigTimeoutTime_APM2" SG_ 216 BMS_HV_RefTracHVBus_V_Vldty_PT 0;
BA_ "GenSigTimeoutTime_VDCM" SG_ 216 BMS_HV_RefTracHVBus_V_Vldty_PT 0;
BA_ "GenSigTimeoutTime_HCP" SG_ 216 BMS_HV_TracCntctr_Cmd_PT 0;
BA_ "GenSigTimeoutTime_PPIM" SG_ 216 BMS_HV_TracCntctr_Cmd_PT 0;
BA_ "GenSigTimeoutTime_APM2" SG_ 216 BMS_HV_TracCntctr_Cmd_PT 0;
BA_ "GenSigTimeoutTime_VDCM" SG_ 216 BMS_HV_TracCntctr_Cmd_PT 0;
BA_ "GenSigTimeoutTime_IDCM" SG_ 216 BMS_HV_TracCntctr_Cmd_PT 0;
BA_ "GenSigTimeoutTime_HCP" SG_ 216 BPCM_OBCM_AC_ContactorCmd_PT 0;
BA_ "GenSigTimeoutTime_PPIM" SG_ 216 BPCM_OBCM_AC_ContactorCmd_PT 0;
BA_ "GenSigTimeoutTime_APM2" SG_ 216 BPCM_OBCM_AC_ContactorCmd_PT 0;
BA_ "GenSigTimeoutTime_VDCM" SG_ 216 BPCM_OBCM_AC_ContactorCmd_PT 0;
BA_ "GenSigTimeoutTime_HCP" SG_ 216 CRC_PT_ENERGY_FD_1 0;
BA_ "GenSigTimeoutTime_PPIM" SG_ 216 CRC_PT_ENERGY_FD_1 0;
BA_ "GenSigTimeoutTime_APM2" SG_ 216 CRC_PT_ENERGY_FD_1 0;
BA_ "GenSigTimeoutTime_VDCM" SG_ 216 CRC_PT_ENERGY_FD_1 0;
BA_ "GenSigTimeoutTime_HCP" SG_ 216 DCChargeEnRq_PT 0;
BA_ "GenSigTimeoutTime_PPIM" SG_ 216 DCChargeEnRq_PT 0;
BA_ "GenSigTimeoutTime_VDCM" SG_ 216 DCChargeEnRq_PT 0;
BA_ "GenSigTimeoutTime_HCP" SG_ 216 DCChargeInitialized_PT 0;
BA_ "GenSigTimeoutTime_PPIM" SG_ 216 DCChargeInitialized_PT 0;
BA_ "GenSigTimeoutTime_APM2" SG_ 216 DCChargeInitialized_PT 0;
BA_ "GenSigTimeoutTime_VDCM" SG_ 216 DCChargeInitialized_PT 0;
BA_ "GenSigTimeoutTime_EVCU2" SG_ 216 DCChargeInitialized_PT 0;
BA_ "GenSigTimeoutTime_IDCM" SG_ 216 DCChargeInitialized_PT 0;
BA_ "GenSigTimeoutTime_SGW" SG_ 216 DCChargeInitialized_PT 0;
BA_ "GenSigTimeoutTime_BPCM" SG_ 216 DCChargeEnRq_PT 0;
BA_ "GenSigTimeoutTime_EVCU2" SG_ 216 DCChargeEnRq_PT 0;
BA_ "GenSigTimeoutTime_IDCM" SG_ 216 DCChargeEnRq_PT 0;
BA_ "GenSigTimeoutTime_SGW" SG_ 216 DCChargeEnRq_PT 0;
BA_ "GenSigTimeoutTime_HCP" SG_ 216 DCChrgCurrentLimit_PT 0;
BA_ "GenSigTimeoutTime_PPIM" SG_ 216 DCChrgCurrentLimit_PT 0;
BA_ "GenSigTimeoutTime_VDCM" SG_ 216 DCChrgCurrentLimit_PT 0;
BA_ "GenSigStartValue" SG_ 216 DCChrgCurrentLimit_PT 815;
BA_ "GenSigTimeoutTime_BPCM" SG_ 216 DCChrgCurrentLimit_PT 0;
BA_ "GenSigTimeoutTime_EVCU2" SG_ 216 DCChrgCurrentLimit_PT 0;
BA_ "GenSigTimeoutTime_IDCM" SG_ 216 DCChrgCurrentLimit_PT 0;
BA_ "GenSigTimeoutTime_SGW" SG_ 216 DCChrgCurrentLimit_PT 0;
BA_ "GenSigTimeoutTime_HCP" SG_ 216 DCChrgCurrentRq_PT 0;
BA_ "GenSigTimeoutTime_PPIM" SG_ 216 DCChrgCurrentRq_PT 0;
BA_ "GenSigTimeoutTime_VDCM" SG_ 216 DCChrgCurrentRq_PT 0;
BA_ "GenSigStartValue" SG_ 216 DCChrgCurrentRq_PT 815;
BA_ "GenSigTimeoutTime_BPCM" SG_ 216 DCChrgCurrentRq_PT 0;
BA_ "GenSigTimeoutTime_EVCU2" SG_ 216 DCChrgCurrentRq_PT 0;
BA_ "GenSigTimeoutTime_IDCM" SG_ 216 DCChrgCurrentRq_PT 0;
BA_ "GenSigTimeoutTime_SGW" SG_ 216 DCChrgCurrentRq_PT 0;
BA_ "GenSigTimeoutTime_HCP" SG_ 216 DCChrgPwrLim_PT 0;
BA_ "GenSigTimeoutTime_PPIM" SG_ 216 DCChrgPwrLim_PT 0;
BA_ "GenSigTimeoutTime_VDCM" SG_ 216 DCChrgPwrLim_PT 0;
BA_ "GenSigStartValue" SG_ 216 DCChrgPwrLim_PT 815;
BA_ "GenSigTimeoutTime_BPCM" SG_ 216 DCChrgPwrLim_PT 0;
BA_ "GenSigTimeoutTime_EVCU2" SG_ 216 DCChrgPwrLim_PT 0;
BA_ "GenSigTimeoutTime_IDCM" SG_ 216 DCChrgPwrLim_PT 0;
BA_ "GenSigTimeoutTime_SGW" SG_ 216 DCChrgPwrLim_PT 0;
BA_ "GenSigTimeoutTime_HCP" SG_ 216 DCChrgVoltMax_PT 0;
BA_ "GenSigTimeoutTime_PPIM" SG_ 216 DCChrgVoltMax_PT 0;
BA_ "GenSigTimeoutTime_VDCM" SG_ 216 DCChrgVoltMax_PT 0;
BA_ "GenSigTimeoutTime_BPCM" SG_ 216 DCChrgVoltMax_PT 0;
BA_ "GenSigTimeoutTime_EVCU2" SG_ 216 DCChrgVoltMax_PT 0;
BA_ "GenSigTimeoutTime_IDCM" SG_ 216 DCChrgVoltMax_PT 0;
BA_ "GenSigTimeoutTime_SGW" SG_ 216 DCChrgVoltMax_PT 0;
BA_ "GenSigTimeoutTime_HCP" SG_ 216 DCChrgVoltMin_PT 0;
BA_ "GenSigTimeoutTime_PPIM" SG_ 216 DCChrgVoltMin_PT 0;
BA_ "GenSigTimeoutTime_VDCM" SG_ 216 DCChrgVoltMin_PT 0;
BA_ "GenSigTimeoutTime_BPCM" SG_ 216 DCChrgVoltMin_PT 0;
BA_ "GenSigTimeoutTime_EVCU2" SG_ 216 DCChrgVoltMin_PT 0;
BA_ "GenSigTimeoutTime_IDCM" SG_ 216 DCChrgVoltMin_PT 0;
BA_ "GenSigTimeoutTime_SGW" SG_ 216 DCChrgVoltMin_PT 0;
BA_ "GenSigTimeoutTime_HCP" SG_ 216 MC_PT_ENERGY_FD_1 0;
BA_ "GenSigTimeoutTime_PPIM" SG_ 216 MC_PT_ENERGY_FD_1 0;
BA_ "GenSigTimeoutTime_APM2" SG_ 216 MC_PT_ENERGY_FD_1 0;
BA_ "GenSigTimeoutTime_VDCM" SG_ 216 MC_PT_ENERGY_FD_1 0;
BA_ "GenSigTimeoutTime_EVCU2" SG_ 216 MC_PT_ENERGY_FD_1 0;
BA_ "GenSigTimeoutTime_SGW" SG_ 216 MC_PT_ENERGY_FD_1 0;
BA_ "GenSigTimeoutTime_EVCU2" SG_ 216 CRC_PT_ENERGY_FD_1 0;
BA_ "GenSigTimeoutTime_SGW" SG_ 216 CRC_PT_ENERGY_FD_1 0;
BA_ "GenSigTimeoutTime_EVCU2" SG_ 216 BPCM_OBCM_AC_ContactorCmd_PT 0;
BA_ "GenSigTimeoutTime_SGW" SG_ 216 BPCM_OBCM_AC_ContactorCmd_PT 0;
BA_ "GenSigTimeoutTime_EVCU2" SG_ 216 BMS_HV_TracCntctr_Cmd_PT 0;
BA_ "GenSigTimeoutTime_SGW" SG_ 216 BMS_HV_TracCntctr_Cmd_PT 0;
BA_ "GenSigTimeoutTime_EVCU2" SG_ 216 BMS_HV_RefTracHVBus_V_Vldty_PT 0;
BA_ "GenSigTimeoutTime_IDCM" SG_ 216 BMS_HV_RefTracHVBus_V_Vldty_PT 0;
BA_ "GenSigTimeoutTime_SGW" SG_ 216 BMS_HV_RefTracHVBus_V_Vldty_PT 0;
BA_ "GenSigTimeoutTime_HCP" SG_ 216 BatteryVoltage_Raw_PT 0;
BA_ "GenSigTimeoutTime_PPIM" SG_ 216 BatteryVoltage_Raw_PT 0;
BA_ "GenSigTimeoutTime_APM2" SG_ 216 BatteryVoltage_Raw_PT 0;
BA_ "GenSigTimeoutTime_VDCM" SG_ 216 BatteryVoltage_Raw_PT 0;
BA_ "GenSigTimeoutTime_BPCM" SG_ 216 BatteryVoltage_Raw_PT 0;
BA_ "GenSigTimeoutTime_IDCM" SG_ 216 BatteryVoltage_Raw_PT 0;
BA_ "GenSigTimeoutTime_EVCU2" SG_ 216 BatteryVoltage_Raw_PT 0;
BA_ "GenSigTimeoutTime_SGW" SG_ 216 BatteryVoltage_Raw_PT 0;
BA_ "GenSigTimeoutTime_HCP" SG_ 216 BMS_HV_DC_Chrgng_Cntct_K_Cmd_PT 0;
BA_ "GenSigTimeoutTime_PPIM" SG_ 216 BMS_HV_DC_Chrgng_Cntct_K_Cmd_PT 0;
BA_ "GenSigTimeoutTime_APM2" SG_ 216 BMS_HV_DC_Chrgng_Cntct_K_Cmd_PT 0;
BA_ "GenSigTimeoutTime_VDCM" SG_ 216 BMS_HV_DC_Chrgng_Cntct_K_Cmd_PT 0;
BA_ "GenSigTimeoutTime_IDCM" SG_ 216 BMS_HV_DC_Chrgng_Cntct_K_Cmd_PT 0;
BA_ "GenSigTimeoutTime_EVCU2" SG_ 216 BMS_HV_DC_Chrgng_Cntct_K_Cmd_PT 0;
BA_ "GenSigTimeoutTime_SGW" SG_ 216 BMS_HV_DC_Chrgng_Cntct_K_Cmd_PT 0;
BA_ "GenSigTimeoutTime_HCP" SG_ 216 BMS_HV_GFD_Inhibition_PT 0;
BA_ "GenSigTimeoutTime_PPIM" SG_ 216 BMS_HV_GFD_Inhibition_PT 0;
BA_ "GenSigTimeoutTime_APM2" SG_ 216 BMS_HV_GFD_Inhibition_PT 0;
BA_ "GenSigTimeoutTime_VDCM" SG_ 216 BMS_HV_GFD_Inhibition_PT 0;
BA_ "GenSigTimeoutTime_EVCU2" SG_ 216 BMS_HV_GFD_Inhibition_PT 0;
BA_ "GenSigTimeoutTime_IDCM" SG_ 216 BMS_HV_GFD_Inhibition_PT 0;
BA_ "GenSigTimeoutTime_SGW" SG_ 216 BMS_HV_GFD_Inhibition_PT 0;
BA_ "GenSigTimeoutTime_HCP" SG_ 216 BMS_HV_RefTracHVBus_V_PT 0;
BA_ "GenSigTimeoutTime_PPIM" SG_ 216 BMS_HV_RefTracHVBus_V_PT 0;
BA_ "GenSigTimeoutTime_APM2" SG_ 216 BMS_HV_RefTracHVBus_V_PT 0;
BA_ "GenSigTimeoutTime_VDCM" SG_ 216 BMS_HV_RefTracHVBus_V_PT 0;
BA_ "GenSigTimeoutTime_EVCU2" SG_ 216 BMS_HV_RefTracHVBus_V_PT 0;
BA_ "GenSigTimeoutTime_IDCM" SG_ 216 BMS_HV_RefTracHVBus_V_PT 0;
BA_ "GenSigTimeoutTime_SGW" SG_ 216 BMS_HV_RefTracHVBus_V_PT 0;
BA_ "GenSigTimeoutTime_HCP" SG_ 216 APM_LV_VsetPoint_PT 0;
BA_ "GenSigTimeoutTime_PPIM" SG_ 216 APM_LV_VsetPoint_PT 0;
BA_ "GenSigTimeoutTime_APM2" SG_ 216 APM_LV_VsetPoint_PT 0;
BA_ "GenSigTimeoutTime_VDCM" SG_ 216 APM_LV_VsetPoint_PT 0;
BA_ "GenSigTimeoutTime_BPCM" SG_ 216 APM_LV_VsetPoint_PT 0;
BA_ "GenSigTimeoutTime_EVCU2" SG_ 216 APM_LV_VsetPoint_PT 0;
BA_ "GenSigTimeoutTime_SGW" SG_ 216 APM_LV_VsetPoint_PT 0;
BA_ "GenSigTimeoutTime_VDCM" SG_ 216 APM_LV_VActual_PT 0;
BA_ "GenSigTimeoutTime_BPCM" SG_ 216 APM_LV_VActual_PT 0;
BA_ "GenSigTimeoutTime_EVCU2" SG_ 216 APM_LV_VActual_PT 0;
BA_ "GenSigTimeoutTime_SGW" SG_ 216 APM_LV_VActual_PT 0;
BA_ "GenSigTimeoutTime_HCP" SG_ 216 APM_LV_IMax_PT 0;
BA_ "GenSigTimeoutTime_PPIM" SG_ 216 APM_LV_IMax_PT 0;
BA_ "GenSigTimeoutTime_APM2" SG_ 216 APM_LV_IMax_PT 0;
BA_ "GenSigTimeoutTime_VDCM" SG_ 216 APM_LV_IMax_PT 0;
BA_ "GenSigTimeoutTime_BPCM" SG_ 216 APM_LV_IMax_PT 0;
BA_ "GenSigTimeoutTime_EVCU2" SG_ 216 APM_LV_IMax_PT 0;
BA_ "GenSigTimeoutTime_SGW" SG_ 216 APM_LV_IMax_PT 0;
BA_ "GenSigTimeoutTime_BPCM" SG_ 2654339197 PreviousCanNMState_FD05_IDCM 0;
BA_ "GenSigTimeoutTime_EVCU2" SG_ 2654339197 PreviousCanNMState_FD05_IDCM 0;
BA_ "GenSigTimeoutTime_IDCM" SG_ 2654339197 PreviousCanNMState_FD05_IDCM 0;
BA_ "GenSigTimeoutTime_HCP" SG_ 2654339197 PreviousCanNMState_FD05_IDCM 0;
BA_ "GenSigTimeoutTime_PPIM" SG_ 2654339197 PreviousCanNMState_FD05_IDCM 0;
BA_ "GenSigTimeoutTime_APM2" SG_ 2654339197 PreviousCanNMState_FD05_IDCM 0;
BA_ "GenSigTimeoutTime_VDCM" SG_ 2654339197 PreviousCanNMState_FD05_IDCM 0;
BA_ "GenSigTimeoutTime_BPCM" SG_ 2654339197 StayActiveSource_FD05_IDCM 0;
BA_ "GenSigTimeoutTime_EVCU2" SG_ 2654339197 StayActiveSource_FD05_IDCM 0;
BA_ "GenSigTimeoutTime_IDCM" SG_ 2654339197 StayActiveSource_FD05_IDCM 0;
BA_ "GenSigTimeoutTime_HCP" SG_ 2654339197 StayActiveSource_FD05_IDCM 0;
BA_ "GenSigTimeoutTime_PPIM" SG_ 2654339197 StayActiveSource_FD05_IDCM 0;
BA_ "GenSigTimeoutTime_APM2" SG_ 2654339197 StayActiveSource_FD05_IDCM 0;
BA_ "GenSigTimeoutTime_VDCM" SG_ 2654339197 StayActiveSource_FD05_IDCM 0;
BA_ "GenSigTimeoutTime_BPCM" SG_ 2654339197 WakeupSource_FD05_IDCM 0;
BA_ "GenSigTimeoutTime_EVCU2" SG_ 2654339197 WakeupSource_FD05_IDCM 0;
BA_ "GenSigTimeoutTime_IDCM" SG_ 2654339197 WakeupSource_FD05_IDCM 0;
BA_ "GenSigTimeoutTime_HCP" SG_ 2654339197 WakeupSource_FD05_IDCM 0;
BA_ "GenSigTimeoutTime_PPIM" SG_ 2654339197 WakeupSource_FD05_IDCM 0;
BA_ "GenSigTimeoutTime_APM2" SG_ 2654339197 WakeupSource_FD05_IDCM 0;
BA_ "GenSigTimeoutTime_VDCM" SG_ 2654339197 WakeupSource_FD05_IDCM 0;
BA_ "GenSigTimeoutTime_HCP" SG_ 216 APM_HV_IMax_PT 0;
BA_ "GenSigTimeoutTime_PPIM" SG_ 216 APM_HV_IMax_PT 0;
BA_ "GenSigTimeoutTime_APM2" SG_ 216 APM_HV_IMax_PT 0;
BA_ "GenSigTimeoutTime_VDCM" SG_ 216 APM_HV_IMax_PT 0;
BA_ "GenSigTimeoutTime_BPCM" SG_ 216 APM_HV_IMax_PT 0;
BA_ "GenSigTimeoutTime_EVCU2" SG_ 216 APM_HV_IMax_PT 0;
BA_ "GenSigTimeoutTime_SGW" SG_ 216 APM_HV_IMax_PT 0;
BA_ "GenSigTimeoutTime_HCP" SG_ 2654339197 CurrentCanNMState_FD05_IDCM 0;
BA_ "GenSigTimeoutTime_PPIM" SG_ 2654339197 CurrentCanNMState_FD05_IDCM 0;
BA_ "GenSigTimeoutTime_APM2" SG_ 2654339197 CurrentCanNMState_FD05_IDCM 0;
BA_ "GenSigTimeoutTime_VDCM" SG_ 2654339197 CurrentCanNMState_FD05_IDCM 0;
BA_ "GenSigTimeoutTime_HCP" SG_ 2654339197 CurrentFailSts_FD05_IDCM 0;
BA_ "GenSigTimeoutTime_PPIM" SG_ 2654339197 CurrentFailSts_FD05_IDCM 0;
BA_ "GenSigTimeoutTime_APM2" SG_ 2654339197 CurrentFailSts_FD05_IDCM 0;
BA_ "GenSigTimeoutTime_VDCM" SG_ 2654339197 CurrentFailSts_FD05_IDCM 0;
BA_ "GenSigTimeoutTime_HCP" SG_ 2654339197 DES_FD05_IDCM 0;
BA_ "GenSigTimeoutTime_PPIM" SG_ 2654339197 DES_FD05_IDCM 0;
BA_ "GenSigTimeoutTime_APM2" SG_ 2654339197 DES_FD05_IDCM 0;
BA_ "GenSigTimeoutTime_VDCM" SG_ 2654339197 DES_FD05_IDCM 0;
BA_ "GenSigTimeoutTime_HCP" SG_ 2654339197 EOL_FD05_IDCM 0;
BA_ "GenSigTimeoutTime_PPIM" SG_ 2654339197 EOL_FD05_IDCM 0;
BA_ "GenSigTimeoutTime_APM2" SG_ 2654339197 EOL_FD05_IDCM 0;
BA_ "GenSigTimeoutTime_VDCM" SG_ 2654339197 EOL_FD05_IDCM 0;
BA_ "GenSigTimeoutTime_BPCM" SG_ 2654339197 GenericFailSts_FD05_IDCM 0;
BA_ "GenSigTimeoutTime_EVCU2" SG_ 2654339197 GenericFailSts_FD05_IDCM 0;
BA_ "GenSigTimeoutTime_IDCM" SG_ 2654339197 GenericFailSts_FD05_IDCM 0;
BA_ "GenSigTimeoutTime_HCP" SG_ 2654339197 GenericFailSts_FD05_IDCM 0;
BA_ "GenSigTimeoutTime_PPIM" SG_ 2654339197 GenericFailSts_FD05_IDCM 0;
BA_ "GenSigTimeoutTime_APM2" SG_ 2654339197 GenericFailSts_FD05_IDCM 0;
BA_ "GenSigTimeoutTime_VDCM" SG_ 2654339197 GenericFailSts_FD05_IDCM 0;
BA_ "GenSigTimeoutTime_HCP" SG_ 2654339197 PreviousCanNMState_FD11_IDCM 0;
BA_ "GenSigTimeoutTime_PPIM" SG_ 2654339197 PreviousCanNMState_FD11_IDCM 0;
BA_ "GenSigTimeoutTime_APM2" SG_ 2654339197 PreviousCanNMState_FD11_IDCM 0;
BA_ "GenSigTimeoutTime_VDCM" SG_ 2654339197 PreviousCanNMState_FD11_IDCM 0;
BA_ "GenSigTimeoutTime_HCP" SG_ 2654339197 StayActiveSource_FD11_IDCM 0;
BA_ "GenSigTimeoutTime_PPIM" SG_ 2654339197 StayActiveSource_FD11_IDCM 0;
BA_ "GenSigTimeoutTime_APM2" SG_ 2654339197 StayActiveSource_FD11_IDCM 0;
BA_ "GenSigTimeoutTime_VDCM" SG_ 2654339197 StayActiveSource_FD11_IDCM 0;
BA_ "GenSigTimeoutTime_HCP" SG_ 2654339197 WakeupSource_FD11_IDCM 0;
BA_ "GenSigTimeoutTime_PPIM" SG_ 2654339197 WakeupSource_FD11_IDCM 0;
BA_ "GenSigTimeoutTime_APM2" SG_ 2654339197 WakeupSource_FD11_IDCM 0;
BA_ "GenSigTimeoutTime_VDCM" SG_ 2654339197 WakeupSource_FD11_IDCM 0;
BA_ "GenSigTimeoutTime_BPCM" SG_ 2654339197 CurrentCanNMState_FD11_IDCM 0;
BA_ "GenSigTimeoutTime_EVCU2" SG_ 2654339197 CurrentCanNMState_FD11_IDCM 0;
BA_ "GenSigTimeoutTime_IDCM" SG_ 2654339197 CurrentCanNMState_FD11_IDCM 0;
BA_ "GenSigTimeoutTime_HCP" SG_ 2654339197 CurrentCanNMState_FD11_IDCM 0;
BA_ "GenSigTimeoutTime_PPIM" SG_ 2654339197 CurrentCanNMState_FD11_IDCM 0;
BA_ "GenSigTimeoutTime_APM2" SG_ 2654339197 CurrentCanNMState_FD11_IDCM 0;
BA_ "GenSigTimeoutTime_VDCM" SG_ 2654339197 CurrentCanNMState_FD11_IDCM 0;
BA_ "GenSigTimeoutTime_BPCM" SG_ 2654339197 CurrentFailSts_FD11_IDCM 0;
BA_ "GenSigTimeoutTime_IDCM" SG_ 2654339197 CurrentFailSts_FD11_IDCM 0;
BA_ "GenSigTimeoutTime_HCP" SG_ 2654339197 CurrentFailSts_FD11_IDCM 0;
BA_ "GenSigTimeoutTime_PPIM" SG_ 2654339197 CurrentFailSts_FD11_IDCM 0;
BA_ "GenSigTimeoutTime_APM2" SG_ 2654339197 CurrentFailSts_FD11_IDCM 0;
BA_ "GenSigTimeoutTime_VDCM" SG_ 2654339197 CurrentFailSts_FD11_IDCM 0;
BA_ "GenSigTimeoutTime_EVCU2" SG_ 2654339197 CurrentFailSts_FD11_IDCM 0;
BA_ "GenSigTimeoutTime_HCP" SG_ 2654339197 DES_FD11_IDCM 0;
BA_ "GenSigTimeoutTime_PPIM" SG_ 2654339197 DES_FD11_IDCM 0;
BA_ "GenSigTimeoutTime_APM2" SG_ 2654339197 DES_FD11_IDCM 0;
BA_ "GenSigTimeoutTime_VDCM" SG_ 2654339197 DES_FD11_IDCM 0;
BA_ "GenSigTimeoutTime_HCP" SG_ 2654339197 GenericFailSts_FD11_IDCM 0;
BA_ "GenSigTimeoutTime_PPIM" SG_ 2654339197 GenericFailSts_FD11_IDCM 0;
BA_ "GenSigTimeoutTime_APM2" SG_ 2654339197 GenericFailSts_FD11_IDCM 0;
BA_ "GenSigTimeoutTime_VDCM" SG_ 2654339197 GenericFailSts_FD11_IDCM 0;
BA_ "GenSigTimeoutTime_EVCU2" SG_ 2654339197 GenericFailSts_FD11_IDCM 0;
BA_ "GenSigTimeoutTime_HCP" SG_ 216 APM_TypeCtrl_PT 0;
BA_ "GenSigTimeoutTime_PPIM" SG_ 216 APM_TypeCtrl_PT 0;
BA_ "GenSigTimeoutTime_APM2" SG_ 216 APM_TypeCtrl_PT 0;
BA_ "GenSigTimeoutTime_VDCM" SG_ 216 APM_TypeCtrl_PT 0;
BA_ "GenSigTimeoutTime_BPCM" SG_ 216 APM_TypeCtrl_PT 0;
BA_ "GenSigTimeoutTime_EVCU2" SG_ 216 APM_TypeCtrl_PT 0;
BA_ "GenSigTimeoutTime_SGW" SG_ 216 APM_TypeCtrl_PT 0;
BA_ "GenSigTimeoutTime_HCP" SG_ 216 BMS_HV_Char_Main_Contac_Cmd_PT 0;
BA_ "GenSigTimeoutTime_PPIM" SG_ 216 BMS_HV_Char_Main_Contac_Cmd_PT 0;
BA_ "GenSigTimeoutTime_APM2" SG_ 216 BMS_HV_Char_Main_Contac_Cmd_PT 0;
BA_ "GenSigTimeoutTime_VDCM" SG_ 216 BMS_HV_Char_Main_Contac_Cmd_PT 0;
BA_ "GenSigTimeoutTime_EVCU2" SG_ 216 BMS_HV_Char_Main_Contac_Cmd_PT 0;
BA_ "GenSigTimeoutTime_IDCM" SG_ 216 BMS_HV_Char_Main_Contac_Cmd_PT 0;
BA_ "GenSigTimeoutTime_SGW" SG_ 216 BMS_HV_Char_Main_Contac_Cmd_PT 0;
BA_ "GenSigTimeoutTime_HCP" SG_ 2564455666 N_PDU_18DA7CF2 0;
BA_ "GenSigTimeoutTime_PPIM" SG_ 2564455666 N_PDU_18DA7CF2 0;
BA_ "GenSigTimeoutTime_BPCM" SG_ 2564455666 N_PDU_18DA7CF2 0;
BA_ "GenSigTimeoutTime_EVCU2" SG_ 2564455666 N_PDU_18DA7CF2 0;
BA_ "GenSigTimeoutTime_IDCM" SG_ 2564455666 N_PDU_18DA7CF2 0;
BA_ "GenSigTimeoutTime_SGW" SG_ 2564455666 N_PDU_18DA7CF2 0;
BA_ "GenSigTimeoutTime_BPCM" SG_ 2654339197 GenericFailSts_FD11_IDCM 0;
BA_ "GenSigTimeoutTime_IDCM" SG_ 2654339197 GenericFailSts_FD11_IDCM 0;
BA_ "GenSigTimeoutTime_BPCM" SG_ 2654339197 DES_FD11_IDCM 0;
BA_ "GenSigTimeoutTime_EVCU2" SG_ 2654339197 DES_FD11_IDCM 0;
BA_ "GenSigTimeoutTime_IDCM" SG_ 2654339197 DES_FD11_IDCM 0;
BA_ "GenSigTimeoutTime_HCP" SG_ 263 PowertrainPrplsnActv_PT 0;
BA_ "GenSigTimeoutTime_PPIM" SG_ 263 PowertrainPrplsnActv_PT 0;
BA_ "GenSigTimeoutTime_APM2" SG_ 263 PowertrainPrplsnActv_PT 0;
BA_ "GenSigTimeoutTime_VDCM" SG_ 263 PowertrainPrplsnActv_PT 0;
BA_ "GenSigTimeoutTime_IDCM" SG_ 263 PowertrainPrplsnActv_PT 0;
BA_ "GenSigTimeoutTime_EVCU2" SG_ 263 PowertrainPrplsnActv_PT 0;
BA_ "GenSigTimeoutTime_SGW" SG_ 263 PowertrainPrplsnActv_PT 0;
BA_ "GenSigTimeoutTime_HCP" SG_ 263 GearEngagedForDisplay_PT 0;
BA_ "GenSigTimeoutTime_PPIM" SG_ 263 GearEngagedForDisplay_PT 0;
BA_ "GenSigTimeoutTime_APM2" SG_ 263 GearEngagedForDisplay_PT 0;
BA_ "GenSigTimeoutTime_VDCM" SG_ 263 GearEngagedForDisplay_PT 0;
BA_ "GenSigTimeoutTime_IDCM" SG_ 263 GearEngagedForDisplay_PT 0;
BA_ "GenSigTimeoutTime_EVCU2" SG_ 263 GearEngagedForDisplay_PT 0;
BA_ "GenSigTimeoutTime_SGW" SG_ 263 GearEngagedForDisplay_PT 0;
BA_ "GenSigTimeoutTime_HCP" SG_ 263 DriveReady_PT 0;
BA_ "GenSigTimeoutTime_PPIM" SG_ 263 DriveReady_PT 0;
BA_ "GenSigTimeoutTime_APM2" SG_ 263 DriveReady_PT 0;
BA_ "GenSigTimeoutTime_VDCM" SG_ 263 DriveReady_PT 0;
BA_ "GenSigTimeoutTime_EVCU2" SG_ 263 DriveReady_PT 0;
BA_ "GenSigTimeoutTime_IDCM" SG_ 263 DriveReady_PT 0;
BA_ "GenSigTimeoutTime_SGW" SG_ 263 DriveReady_PT 0;
BA_ "GenSigTimeoutTime_HCP" SG_ 263 GearEngaged_PT 0;
BA_ "GenSigTimeoutTime_PPIM" SG_ 263 GearEngaged_PT 0;
BA_ "GenSigTimeoutTime_APM2" SG_ 263 GearEngaged_PT 0;
BA_ "GenSigTimeoutTime_VDCM" SG_ 263 GearEngaged_PT 0;
BA_ "GenSigTimeoutTime_BPCM" SG_ 263 GearEngaged_PT 0;
BA_ "GenSigTimeoutTime_EVCU2" SG_ 263 GearEngaged_PT 0;
BA_ "GenSigTimeoutTime_IDCM" SG_ 263 GearEngaged_PT 0;
BA_ "GenSigTimeoutTime_SGW" SG_ 263 GearEngaged_PT 0;
BA_ "GenSigTimeoutTime_BPCM" SG_ 2654339197 WakeupSource_FD11_IDCM 0;
BA_ "GenSigTimeoutTime_EVCU2" SG_ 2654339197 WakeupSource_FD11_IDCM 0;
BA_ "GenSigTimeoutTime_IDCM" SG_ 2654339197 WakeupSource_FD11_IDCM 0;
BA_ "GenSigTimeoutTime_HCP" SG_ 1064 SGCP_Temp 0;
BA_ "GenSigTimeoutTime_PPIM" SG_ 1064 SGCP_Temp 0;
BA_ "GenSigTimeoutTime_BPCM" SG_ 1064 SGCP_Temp 0;
BA_ "GenSigTimeoutTime_EVCU2" SG_ 1064 SGCP_Temp 0;
BA_ "GenSigTimeoutTime_IDCM" SG_ 1064 SGCP_Temp 0;
BA_ "GenSigTimeoutTime_BPCM" SG_ 2654339197 StayActiveSource_FD11_IDCM 0;
BA_ "GenSigTimeoutTime_EVCU2" SG_ 2654339197 StayActiveSource_FD11_IDCM 0;
BA_ "GenSigTimeoutTime_IDCM" SG_ 2654339197 StayActiveSource_FD11_IDCM 0;
BA_ "GenSigTimeoutTime_BPCM" SG_ 2654339197 PreviousCanNMState_FD11_IDCM 0;
BA_ "GenSigTimeoutTime_EVCU2" SG_ 2654339197 PreviousCanNMState_FD11_IDCM 0;
BA_ "GenSigTimeoutTime_IDCM" SG_ 2654339197 PreviousCanNMState_FD11_IDCM 0;
BA_ "GenSigTimeoutTime_BPCM" SG_ 2654339197 EOL_FD05_IDCM 0;
BA_ "GenSigTimeoutTime_EVCU2" SG_ 2654339197 EOL_FD05_IDCM 0;
BA_ "GenSigTimeoutTime_IDCM" SG_ 2654339197 EOL_FD05_IDCM 0;
BA_ "GenSigTimeoutTime_BPCM" SG_ 2654339197 DES_FD05_IDCM 0;
BA_ "GenSigTimeoutTime_EVCU2" SG_ 2654339197 DES_FD05_IDCM 0;
BA_ "GenSigTimeoutTime_IDCM" SG_ 2654339197 DES_FD05_IDCM 0;
BA_ "GenSigTimeoutTime_BPCM" SG_ 2654339197 CurrentFailSts_FD05_IDCM 0;
BA_ "GenSigTimeoutTime_EVCU2" SG_ 2654339197 CurrentFailSts_FD05_IDCM 0;
BA_ "GenSigTimeoutTime_IDCM" SG_ 2654339197 CurrentFailSts_FD05_IDCM 0;
BA_ "GenSigTimeoutTime_BPCM" SG_ 2654339197 CurrentCanNMState_FD05_IDCM 0;
BA_ "GenSigTimeoutTime_EVCU2" SG_ 2654339197 CurrentCanNMState_FD05_IDCM 0;
BA_ "GenSigTimeoutTime_IDCM" SG_ 2654339197 CurrentCanNMState_FD05_IDCM 0;
BA_ "GenSigTimeoutTime_VDCM" SG_ 2654339197 EOL_FD11_IDCM 0;
BA_ "GenSigTimeoutTime_EVCU2" SG_ 2654339197 EOL_FD11_IDCM 0;
BA_ "GenSigTimeoutTime_HCP" SG_ 2654339197 EOL_FD11_IDCM 0;
BA_ "GenSigTimeoutTime_PPIM" SG_ 2654339197 EOL_FD11_IDCM 0;
BA_ "GenSigTimeoutTime_APM2" SG_ 2654339197 EOL_FD11_IDCM 0;
BA_ "GenSigTimeoutTime_BPCM" SG_ 2654339197 EOL_FD11_IDCM 0;
BA_ "GenSigTimeoutTime_IDCM" SG_ 2654339197 EOL_FD11_IDCM 0;
BA_ "GenSigTimeoutTime_HCP" SG_ 134 N_PDU_86 0;
BA_ "GenSigTimeoutTime_PPIM" SG_ 134 N_PDU_86 0;
BA_ "GenSigTimeoutTime_BPCM" SG_ 134 N_PDU_86 0;
BA_ "GenSigTimeoutTime_EVCU2" SG_ 134 N_PDU_86 0;
BA_ "GenSigTimeoutTime_IDCM" SG_ 134 N_PDU_86 0;
BA_ "GenSigTimeoutTime_HCP" SG_ 129 N_PDU_81 0;
BA_ "GenSigTimeoutTime_PPIM" SG_ 129 N_PDU_81 0;
BA_ "GenSigTimeoutTime_BPCM" SG_ 129 N_PDU_81 0;
BA_ "GenSigTimeoutTime_IDCM" SG_ 129 N_PDU_81 0;
BA_ "GenSigTimeoutTime_SGW" SG_ 129 N_PDU_81 0;
BA_ "GenSigTimeoutTime_HCP" SG_ 577 QualifyDriveCycle 0;
BA_ "GenSigTimeoutTime_PPIM" SG_ 577 QualifyDriveCycle 0;
BA_ "GenSigSendType" SG_ 577 QualifyDriveCycle 3;
BA_ "GenSigTimeoutTime_EVCU2" SG_ 577 QualifyDriveCycle 0;
BA_ "GenSigTimeoutTime_IDCM" SG_ 577 QualifyDriveCycle 0;
BA_ "GenSigTimeoutTime_SGW" SG_ 577 QualifyDriveCycle 0;
BA_ "GenSigTimeoutTime_HCP" SG_ 1050 CRC_RPF_FD_2 0;
BA_ "GenSigTimeoutTime_PPIM" SG_ 1050 CRC_RPF_FD_2 0;
BA_ "GenSigTimeoutTime_HCP" SG_ 1050 MC_RPF_FD_2 0;
BA_ "GenSigTimeoutTime_PPIM" SG_ 1050 MC_RPF_FD_2 0;
BA_ "GenSigTimeoutTime_BPCM" SG_ 1050 MC_RPF_FD_2 0;
BA_ "GenSigTimeoutTime_IDCM" SG_ 1050 MC_RPF_FD_2 0;
BA_ "GenSigTimeoutTime_SGW" SG_ 1050 MC_RPF_FD_2 0;
BA_ "GenSigTimeoutTime_HCP" SG_ 1050 V2X_Derate_Status 0;
BA_ "GenSigTimeoutTime_PPIM" SG_ 1050 V2X_Derate_Status 0;
BA_ "GenSigTimeoutTime_BPCM" SG_ 1050 V2X_Derate_Status 0;
BA_ "GenSigTimeoutTime_IDCM" SG_ 1050 V2X_Derate_Status 0;
BA_ "GenSigTimeoutTime_SGW" SG_ 1050 V2X_Derate_Status 0;
BA_ "GenSigTimeoutTime_HCP" SG_ 1050 V2X_Derate_Reason 0;
BA_ "GenSigTimeoutTime_PPIM" SG_ 1050 V2X_Derate_Reason 0;
BA_ "GenSigTimeoutTime_BPCM" SG_ 1050 V2X_Derate_Reason 0;
BA_ "GenSigTimeoutTime_IDCM" SG_ 1050 V2X_Derate_Reason 0;
BA_ "GenSigTimeoutTime_SGW" SG_ 1050 V2X_Derate_Reason 0;
BA_ "GenSigTimeoutTime_HCP" SG_ 1050 Available_Power 0;
BA_ "GenSigTimeoutTime_PPIM" SG_ 1050 Available_Power 0;
BA_ "GenSigTimeoutTime_BPCM" SG_ 1050 Available_Power 0;
BA_ "GenSigTimeoutTime_IDCM" SG_ 1050 Available_Power 0;
BA_ "GenSigTimeoutTime_SGW" SG_ 1050 Available_Power 0;
BA_ "GenSigTimeoutTime_HCP" SG_ 1050 AcOutputVoltage 0;
BA_ "GenSigTimeoutTime_PPIM" SG_ 1050 AcOutputVoltage 0;
BA_ "GenSigTimeoutTime_BPCM" SG_ 1050 AcOutputVoltage 0;
BA_ "GenSigTimeoutTime_IDCM" SG_ 1050 AcOutputVoltage 0;
BA_ "GenSigTimeoutTime_SGW" SG_ 1050 AcOutputVoltage 0;
BA_ "GenSigTimeoutTime_HCP" SG_ 1050 AcOutputFrequency 0;
BA_ "GenSigTimeoutTime_PPIM" SG_ 1050 AcOutputFrequency 0;
BA_ "GenSigTimeoutTime_BPCM" SG_ 1050 AcOutputFrequency 0;
BA_ "GenSigTimeoutTime_IDCM" SG_ 1050 AcOutputFrequency 0;
BA_ "GenSigTimeoutTime_SGW" SG_ 1050 AcOutputFrequency 0;
BA_ "GenSigTimeoutTime_HCP" SG_ 1050 AcOuputCurrent 0;
BA_ "GenSigTimeoutTime_PPIM" SG_ 1050 AcOuputCurrent 0;
BA_ "GenSigTimeoutTime_BPCM" SG_ 1050 AcOuputCurrent 0;
BA_ "GenSigTimeoutTime_IDCM" SG_ 1050 AcOuputCurrent 0;
BA_ "GenSigTimeoutTime_SGW" SG_ 1050 AcOuputCurrent 0;
BA_ "GenSigTimeoutTime_HCP" SG_ 124 N_PDU_7C 0;
BA_ "GenSigTimeoutTime_PPIM" SG_ 124 N_PDU_7C 0;
BA_ "GenSigTimeoutTime_APM2" SG_ 124 N_PDU_7C 0;
BA_ "GenSigTimeoutTime_BPCM" SG_ 124 N_PDU_7C 0;
BA_ "GenSigTimeoutTime_EVCU2" SG_ 124 N_PDU_7C 0;
BA_ "GenSigTimeoutTime_IDCM" SG_ 124 N_PDU_7C 0;
BA_ "GenSigTimeoutTime_HCP" SG_ 126 N_PDU_7E 0;
BA_ "GenSigTimeoutTime_PPIM" SG_ 126 N_PDU_7E 0;
BA_ "GenSigTimeoutTime_APM2" SG_ 126 N_PDU_7E 0;
BA_ "GenSigTimeoutTime_BPCM" SG_ 126 N_PDU_7E 0;
BA_ "GenSigTimeoutTime_IDCM" SG_ 126 N_PDU_7E 0;
BA_ "GenSigTimeoutTime_SGW" SG_ 126 N_PDU_7E 0;
BA_ "GenSigTimeoutTime_HCP" SG_ 123 N_PDU_7B 0;
BA_ "GenSigTimeoutTime_PPIM" SG_ 123 N_PDU_7B 0;
BA_ "GenSigTimeoutTime_APM2" SG_ 123 N_PDU_7B 0;
BA_ "GenSigTimeoutTime_BPCM" SG_ 123 N_PDU_7B 0;
BA_ "GenSigTimeoutTime_EVCU2" SG_ 123 N_PDU_7B 0;
BA_ "GenSigTimeoutTime_IDCM" SG_ 123 N_PDU_7B 0;
BA_ "GenSigTimeoutTime_HCP" SG_ 127 N_PDU_7F 0;
BA_ "GenSigTimeoutTime_PPIM" SG_ 127 N_PDU_7F 0;
BA_ "GenSigTimeoutTime_APM2" SG_ 127 N_PDU_7F 0;
BA_ "GenSigTimeoutTime_BPCM" SG_ 127 N_PDU_7F 0;
BA_ "GenSigTimeoutTime_IDCM" SG_ 127 N_PDU_7F 0;
BA_ "GenSigTimeoutTime_SGW" SG_ 127 N_PDU_7F 0;
BA_ "GenSigTimeoutTime_APM2" SG_ 1072 EVSE_ThrshldVoltage 0;
BA_ "GenSigTimeoutTime_BPCM" SG_ 1072 EVSE_ThrshldVoltage 0;
BA_ "GenSigTimeoutTime_IDCM" SG_ 1072 EVSE_ThrshldVoltage 0;
BA_ "GenSigTimeoutTime_SGW" SG_ 1072 EVSE_ThrshldVoltage 0;
BA_ "GenSigTimeoutTime_APM2" SG_ 1072 EVSE_RemainingSec 0;
BA_ "GenSigTimeoutTime_BPCM" SG_ 1072 EVSE_RemainingSec 0;
BA_ "GenSigTimeoutTime_IDCM" SG_ 1072 EVSE_RemainingSec 0;
BA_ "GenSigTimeoutTime_SGW" SG_ 1072 EVSE_RemainingSec 0;
BA_ "GenSigTimeoutTime_APM2" SG_ 1072 EVSE_RemainingMin 0;
BA_ "GenSigTimeoutTime_BPCM" SG_ 1072 EVSE_RemainingMin 0;
BA_ "GenSigTimeoutTime_IDCM" SG_ 1072 EVSE_RemainingMin 0;
BA_ "GenSigTimeoutTime_SGW" SG_ 1072 EVSE_RemainingMin 0;
BA_ "GenSigTimeoutTime_APM2" SG_ 1072 EVSE_EnergizingState 0;
BA_ "GenSigTimeoutTime_BPCM" SG_ 1072 EVSE_EnergizingState 0;
BA_ "GenSigTimeoutTime_IDCM" SG_ 1072 EVSE_EnergizingState 0;
BA_ "GenSigTimeoutTime_SGW" SG_ 1072 EVSE_EnergizingState 0;
BA_ "GenSigTimeoutTime_APM2" SG_ 1072 EVSE_ChargingSystemError 0;
BA_ "GenSigTimeoutTime_BPCM" SG_ 1072 EVSE_ChargingSystemError 0;
BA_ "GenSigTimeoutTime_IDCM" SG_ 1072 EVSE_ChargingSystemError 0;
BA_ "GenSigTimeoutTime_SGW" SG_ 1072 EVSE_ChargingSystemError 0;
BA_ "GenSigTimeoutTime_APM2" SG_ 1072 EVSE_CHAdeMOProtocol 0;
BA_ "GenSigTimeoutTime_BPCM" SG_ 1072 EVSE_CHAdeMOProtocol 0;
BA_ "GenSigTimeoutTime_IDCM" SG_ 1072 EVSE_CHAdeMOProtocol 0;
BA_ "GenSigTimeoutTime_SGW" SG_ 1072 EVSE_CHAdeMOProtocol 0;
BA_ "GenSigTimeoutTime_APM2" SG_ 1072 EVSE_BatteryCompatibilty 0;
BA_ "GenSigTimeoutTime_BPCM" SG_ 1072 EVSE_BatteryCompatibilty 0;
BA_ "GenSigTimeoutTime_IDCM" SG_ 1072 EVSE_BatteryCompatibilty 0;
BA_ "GenSigTimeoutTime_SGW" SG_ 1072 EVSE_BatteryCompatibilty 0;
BA_ "GenSigTimeoutTime_BPCM" SG_ 1072 CdM_Charger_connector_lock 0;
BA_ "GenSigTimeoutTime_IDCM" SG_ 1072 CdM_Charger_connector_lock 0;
BA_ "GenSigTimeoutTime_SGW" SG_ 1072 CdM_Charger_connector_lock 0;
BA_ "GenSigTimeoutTime_BPCM" SG_ 1072 CdM_ExtFun_Thres_Volt 0;
BA_ "GenSigTimeoutTime_IDCM" SG_ 1072 CdM_ExtFun_Thres_Volt 0;
BA_ "GenSigTimeoutTime_SGW" SG_ 1072 CdM_ExtFun_Thres_Volt 0;
BA_ "GenSigTimeoutTime_BPCM" SG_ 1072 CdM_Avail_output_current_EXT 0;
BA_ "GenSigTimeoutTime_IDCM" SG_ 1072 CdM_Avail_output_current_EXT 0;
BA_ "GenSigTimeoutTime_SGW" SG_ 1072 CdM_Avail_output_current_EXT 0;
BA_ "GenSigTimeoutTime_APM2" SG_ 1073 StopReqBeforeCharge 0;
BA_ "GenSigTimeoutTime_BPCM" SG_ 1073 StopReqBeforeCharge 0;
BA_ "GenSigTimeoutTime_EVCU2" SG_ 1073 StopReqBeforeCharge 0;
BA_ "GenSigTimeoutTime_SGW" SG_ 1073 StopReqBeforeCharge 0;
BA_ "GenSigTimeoutTime_APM2" SG_ 1073 MinBatteryPackVoltage 0;
BA_ "GenSigTimeoutTime_BPCM" SG_ 1073 MinBatteryPackVoltage 0;
BA_ "GenSigTimeoutTime_EVCU2" SG_ 1073 MinBatteryPackVoltage 0;
BA_ "GenSigTimeoutTime_SGW" SG_ 1073 MinBatteryPackVoltage 0;
BA_ "GenSigTimeoutTime_APM2" SG_ 1073 EVContactorSts 0;
BA_ "GenSigTimeoutTime_BPCM" SG_ 1073 EVContactorSts 0;
BA_ "GenSigTimeoutTime_EVCU2" SG_ 1073 EVContactorSts 0;
BA_ "GenSigTimeoutTime_SGW" SG_ 1073 EVContactorSts 0;
BA_ "GenSigTimeoutTime_APM2" SG_ 1073 DisplaySOC 0;
BA_ "GenSigTimeoutTime_BPCM" SG_ 1073 DisplaySOC 0;
BA_ "GenSigTimeoutTime_EVCU2" SG_ 1073 DisplaySOC 0;
BA_ "GenSigTimeoutTime_SGW" SG_ 1073 DisplaySOC 0;
BA_ "GenSigTimeoutTime_APM2" SG_ 1073 ChargedReferenceConstant 0;
BA_ "GenSigTimeoutTime_BPCM" SG_ 1073 ChargedReferenceConstant 0;
BA_ "GenSigTimeoutTime_EVCU2" SG_ 1073 ChargedReferenceConstant 0;
BA_ "GenSigTimeoutTime_SGW" SG_ 1073 ChargedReferenceConstant 0;
BA_ "GenSigTimeoutTime_APM2" SG_ 1073 VehicleDriveSts 0;
BA_ "GenSigTimeoutTime_BPCM" SG_ 1073 VehicleDriveSts 0;
BA_ "GenSigTimeoutTime_EVCU2" SG_ 1073 VehicleDriveSts 0;
BA_ "GenSigTimeoutTime_SGW" SG_ 1073 VehicleDriveSts 0;
BA_ "GenSigTimeoutTime_BPCM" SG_ 1073 CdM_Chrg_current_req_ext 0;
BA_ "GenSigTimeoutTime_EVCU2" SG_ 1073 CdM_Chrg_current_req_ext 0;
BA_ "GenSigTimeoutTime_SGW" SG_ 1073 CdM_Chrg_current_req_ext 0;
BA_ "GenSigTimeoutTime_BPCM" SG_ 1073 CdM_ExtFun_Min_Batt_Volt 0;
BA_ "GenSigTimeoutTime_EVCU2" SG_ 1073 CdM_ExtFun_Min_Batt_Volt 0;
BA_ "GenSigTimeoutTime_SGW" SG_ 1073 CdM_ExtFun_Min_Batt_Volt 0;
BA_ "GenSigTimeoutTime_BPCM" SG_ 1073 CdM_ExtFun_Veh_HC_Control_Comp 0;
BA_ "GenSigTimeoutTime_EVCU2" SG_ 1073 CdM_ExtFun_Veh_HC_Control_Comp 0;
BA_ "GenSigTimeoutTime_SGW" SG_ 1073 CdM_ExtFun_Veh_HC_Control_Comp 0;
BA_ "GenSigTimeoutTime_BPCM" SG_ 1073 CdM_ExtFun_Veh_Dyn_Control_Comp 0;
BA_ "GenSigTimeoutTime_EVCU2" SG_ 1073 CdM_ExtFun_Veh_Dyn_Control_Comp 0;
BA_ "GenSigTimeoutTime_SGW" SG_ 1073 CdM_ExtFun_Veh_Dyn_Control_Comp 0;
BA_ "GenSigTimeoutTime_BPCM" SG_ 1073 CdM_Remained_batt_capacity 0;
BA_ "GenSigTimeoutTime_EVCU2" SG_ 1073 CdM_Remained_batt_capacity 0;
BA_ "GenSigTimeoutTime_SGW" SG_ 1073 CdM_Remained_batt_capacity 0;
BA_ "GenSigTimeoutTime_BPCM" SG_ 1073 EVCU_CP3Cmd 0;
BA_ "GenSigTimeoutTime_EVCU2" SG_ 1073 EVCU_CP3Cmd 0;
BA_ "GenSigTimeoutTime_SGW" SG_ 1073 EVCU_CP3Cmd 0;
BA_ "GenSigTimeoutTime_APM2" SG_ 1073 ChargedCurrentMin 0;
BA_ "GenSigTimeoutTime_BPCM" SG_ 1073 ChargedCurrentMin 0;
BA_ "GenSigTimeoutTime_EVCU2" SG_ 1073 ChargedCurrentMin 0;
BA_ "GenSigTimeoutTime_SGW" SG_ 1073 ChargedCurrentMin 0;
BA_ "GenSigTimeoutTime_APM2" SG_ 1073 CHAdeMOProtocol 0;
BA_ "GenSigTimeoutTime_BPCM" SG_ 1073 CHAdeMOProtocol 0;
BA_ "GenSigTimeoutTime_EVCU2" SG_ 1073 CHAdeMOProtocol 0;
BA_ "GenSigTimeoutTime_SGW" SG_ 1073 CHAdeMOProtocol 0;
BA_ "GenSigTimeoutTime_APM2" SG_ 1073 BattVoltDeviationErr 0;
BA_ "GenSigTimeoutTime_BPCM" SG_ 1073 BattVoltDeviationErr 0;
BA_ "GenSigTimeoutTime_EVCU2" SG_ 1073 BattVoltDeviationErr 0;
BA_ "GenSigTimeoutTime_SGW" SG_ 1073 BattVoltDeviationErr 0;
BA_ "GenSigTimeoutTime_APM2" SG_ 1073 TotalBatteryCapacity 0;
BA_ "GenSigTimeoutTime_BPCM" SG_ 1073 TotalBatteryCapacity 0;
BA_ "GenSigTimeoutTime_EVCU2" SG_ 1073 TotalBatteryCapacity 0;
BA_ "GenSigTimeoutTime_SGW" SG_ 1073 TotalBatteryCapacity 0;
BA_ "GenSigTimeoutTime_HCP" SG_ 222 IDCM_CAL_VN 0;
BA_ "GenSigTimeoutTime_PPIM" SG_ 222 IDCM_CAL_VN 0;
BA_ "GenSigTimeoutTime_BPCM" SG_ 222 IDCM_CAL_VN 0;
BA_ "GenSigTimeoutTime_IDCM" SG_ 222 IDCM_CAL_VN 0;
BA_ "GenSigTimeoutTime_SGW" SG_ 222 IDCM_CAL_VN 0;
BA_ "GenSigTimeoutTime_HCP" SG_ 222 IDCM_CAL_ID 0;
BA_ "GenSigTimeoutTime_PPIM" SG_ 222 IDCM_CAL_ID 0;
BA_ "GenSigTimeoutTime_BPCM" SG_ 222 IDCM_CAL_ID 0;
BA_ "GenSigTimeoutTime_IDCM" SG_ 222 IDCM_CAL_ID 0;
BA_ "GenSigTimeoutTime_SGW" SG_ 222 IDCM_CAL_ID 0;
BA_ "GenSigTimeoutTime_HCP" SG_ 222 CRC_IDCM_OBD_DTC 0;
BA_ "GenSigTimeoutTime_PPIM" SG_ 222 CRC_IDCM_OBD_DTC 0;
BA_ "GenSigTimeoutTime_BPCM" SG_ 222 CRC_IDCM_OBD_DTC 0;
BA_ "GenSigTimeoutTime_IDCM" SG_ 222 CRC_IDCM_OBD_DTC 0;
BA_ "GenSigTimeoutTime_SGW" SG_ 222 CRC_IDCM_OBD_DTC 0;
BA_ "GenSigTimeoutTime_HCP" SG_ 222 MessageCounter_IDCM_OBD_DTC 0;
BA_ "GenSigTimeoutTime_PPIM" SG_ 222 MessageCounter_IDCM_OBD_DTC 0;
BA_ "GenSigTimeoutTime_BPCM" SG_ 222 MessageCounter_IDCM_OBD_DTC 0;
BA_ "GenSigTimeoutTime_IDCM" SG_ 222 MessageCounter_IDCM_OBD_DTC 0;
BA_ "GenSigTimeoutTime_SGW" SG_ 222 MessageCounter_IDCM_OBD_DTC 0;
BA_ "GenSigTimeoutTime_HCP" SG_ 222 IDCM_RBM_Stat 0;
BA_ "GenSigTimeoutTime_PPIM" SG_ 222 IDCM_RBM_Stat 0;
BA_ "GenSigTimeoutTime_BPCM" SG_ 222 IDCM_RBM_Stat 0;
BA_ "GenSigTimeoutTime_IDCM" SG_ 222 IDCM_RBM_Stat 0;
BA_ "GenSigTimeoutTime_SGW" SG_ 222 IDCM_RBM_Stat 0;
BA_ "GenSigTimeoutTime_HCP" SG_ 222 IDCM_RBM_Idx 0;
BA_ "GenSigTimeoutTime_PPIM" SG_ 222 IDCM_RBM_Idx 0;
BA_ "GenSigTimeoutTime_BPCM" SG_ 222 IDCM_RBM_Idx 0;
BA_ "GenSigTimeoutTime_IDCM" SG_ 222 IDCM_RBM_Idx 0;
BA_ "GenSigTimeoutTime_SGW" SG_ 222 IDCM_RBM_Idx 0;
BA_ "GenSigTimeoutTime_HCP" SG_ 222 IDCM_DTC_Stat8 0;
BA_ "GenSigTimeoutTime_PPIM" SG_ 222 IDCM_DTC_Stat8 0;
BA_ "GenSigTimeoutTime_BPCM" SG_ 222 IDCM_DTC_Stat8 0;
BA_ "GenSigTimeoutTime_IDCM" SG_ 222 IDCM_DTC_Stat8 0;
BA_ "GenSigTimeoutTime_SGW" SG_ 222 IDCM_DTC_Stat8 0;
BA_ "GenSigTimeoutTime_HCP" SG_ 222 IDCM_DTC_Stat5 0;
BA_ "GenSigTimeoutTime_PPIM" SG_ 222 IDCM_DTC_Stat5 0;
BA_ "GenSigTimeoutTime_BPCM" SG_ 222 IDCM_DTC_Stat5 0;
BA_ "GenSigTimeoutTime_IDCM" SG_ 222 IDCM_DTC_Stat5 0;
BA_ "GenSigTimeoutTime_SGW" SG_ 222 IDCM_DTC_Stat5 0;
BA_ "GenSigTimeoutTime_BPCM" SG_ 222 IDCM_DTC_Stat4 0;
BA_ "GenSigTimeoutTime_IDCM" SG_ 222 IDCM_DTC_Stat4 0;
BA_ "GenSigTimeoutTime_SGW" SG_ 222 IDCM_DTC_Stat4 0;
BA_ "GenSigTimeoutTime_HCP" SG_ 222 IDCM_DTC_Stat4 0;
BA_ "GenSigTimeoutTime_PPIM" SG_ 222 IDCM_DTC_Stat4 0;
BA_ "GenSigTimeoutTime_BPCM" SG_ 222 IDCM_DTC_Stat3 0;
BA_ "GenSigTimeoutTime_IDCM" SG_ 222 IDCM_DTC_Stat3 0;
BA_ "GenSigTimeoutTime_SGW" SG_ 222 IDCM_DTC_Stat3 0;
BA_ "GenSigTimeoutTime_HCP" SG_ 222 IDCM_DTC_Stat3 0;
BA_ "GenSigTimeoutTime_PPIM" SG_ 222 IDCM_DTC_Stat3 0;
BA_ "GenSigTimeoutTime_BPCM" SG_ 222 IDCM_DTC_Stat2 0;
BA_ "GenSigTimeoutTime_IDCM" SG_ 222 IDCM_DTC_Stat2 0;
BA_ "GenSigTimeoutTime_SGW" SG_ 222 IDCM_DTC_Stat2 0;
BA_ "GenSigTimeoutTime_HCP" SG_ 222 IDCM_DTC_Stat2 0;
BA_ "GenSigTimeoutTime_PPIM" SG_ 222 IDCM_DTC_Stat2 0;
BA_ "GenSigTimeoutTime_BPCM" SG_ 222 IDCM_DTC_Stat1 0;
BA_ "GenSigTimeoutTime_IDCM" SG_ 222 IDCM_DTC_Stat1 0;
BA_ "GenSigTimeoutTime_SGW" SG_ 222 IDCM_DTC_Stat1 0;
BA_ "GenSigTimeoutTime_HCP" SG_ 222 IDCM_DTC_Stat1 0;
BA_ "GenSigTimeoutTime_PPIM" SG_ 222 IDCM_DTC_Stat1 0;
BA_ "GenSigTimeoutTime_BPCM" SG_ 222 IDCM_DTC_Idx8 0;
BA_ "GenSigTimeoutTime_IDCM" SG_ 222 IDCM_DTC_Idx8 0;
BA_ "GenSigTimeoutTime_SGW" SG_ 222 IDCM_DTC_Idx8 0;
BA_ "GenSigTimeoutTime_HCP" SG_ 222 IDCM_DTC_Idx8 0;
BA_ "GenSigTimeoutTime_PPIM" SG_ 222 IDCM_DTC_Idx8 0;
BA_ "GenSigTimeoutTime_HCP" SG_ 222 IDCM_DTC_Idx7 0;
BA_ "GenSigTimeoutTime_PPIM" SG_ 222 IDCM_DTC_Idx7 0;
BA_ "GenSigTimeoutTime_BPCM" SG_ 222 IDCM_DTC_Idx7 0;
BA_ "GenSigTimeoutTime_IDCM" SG_ 222 IDCM_DTC_Idx7 0;
BA_ "GenSigTimeoutTime_SGW" SG_ 222 IDCM_DTC_Idx7 0;
BA_ "GenSigTimeoutTime_HCP" SG_ 503 MCPA_DC_Current_P 0;
BA_ "GenSigTimeoutTime_PPIM" SG_ 503 MCPA_DC_Current_P 0;
BA_ "GenSigTimeoutTime_APM2" SG_ 503 MCPA_DC_Current_P 0;
BA_ "GenSigTimeoutTime_VDCM" SG_ 503 MCPA_DC_Current_P 0;
BA_ "GenSigTimeoutTime_HCP" SG_ 503 CRC_MCPA_STATUS 0;
BA_ "GenSigTimeoutTime_PPIM" SG_ 503 CRC_MCPA_STATUS 0;
BA_ "GenSigTimeoutTime_APM2" SG_ 503 CRC_MCPA_STATUS 0;
BA_ "GenSigTimeoutTime_HCP" SG_ 503 MC_MCPA_STATUS 0;
BA_ "GenSigTimeoutTime_PPIM" SG_ 503 MC_MCPA_STATUS 0;
BA_ "GenSigTimeoutTime_APM2" SG_ 503 MC_MCPA_STATUS 0;
BA_ "GenSigTimeoutTime_HCP" SG_ 222 IDCM_DTC_Idx6 0;
BA_ "GenSigTimeoutTime_PPIM" SG_ 222 IDCM_DTC_Idx6 0;
BA_ "GenSigTimeoutTime_BPCM" SG_ 222 IDCM_DTC_Idx6 0;
BA_ "GenSigTimeoutTime_IDCM" SG_ 222 IDCM_DTC_Idx6 0;
BA_ "GenSigTimeoutTime_SGW" SG_ 222 IDCM_DTC_Idx6 0;
BA_ "GenSigTimeoutTime_HCP" SG_ 222 IDCM_DTC_Idx5 0;
BA_ "GenSigTimeoutTime_PPIM" SG_ 222 IDCM_DTC_Idx5 0;
BA_ "GenSigTimeoutTime_BPCM" SG_ 222 IDCM_DTC_Idx5 0;
BA_ "GenSigTimeoutTime_IDCM" SG_ 222 IDCM_DTC_Idx5 0;
BA_ "GenSigTimeoutTime_SGW" SG_ 222 IDCM_DTC_Idx5 0;
BA_ "GenSigTimeoutTime_HCP" SG_ 222 IDCM_DTC_Idx4 0;
BA_ "GenSigTimeoutTime_PPIM" SG_ 222 IDCM_DTC_Idx4 0;
BA_ "GenSigTimeoutTime_BPCM" SG_ 222 IDCM_DTC_Idx4 0;
BA_ "GenSigTimeoutTime_IDCM" SG_ 222 IDCM_DTC_Idx4 0;
BA_ "GenSigTimeoutTime_SGW" SG_ 222 IDCM_DTC_Idx4 0;
BA_ "GenSigTimeoutTime_HCP" SG_ 222 IDCM_DTC_Idx3 0;
BA_ "GenSigTimeoutTime_PPIM" SG_ 222 IDCM_DTC_Idx3 0;
BA_ "GenSigTimeoutTime_BPCM" SG_ 222 IDCM_DTC_Idx3 0;
BA_ "GenSigTimeoutTime_IDCM" SG_ 222 IDCM_DTC_Idx3 0;
BA_ "GenSigTimeoutTime_SGW" SG_ 222 IDCM_DTC_Idx3 0;
BA_ "GenSigTimeoutTime_HCP" SG_ 222 IDCM_DTC_Idx2 0;
BA_ "GenSigTimeoutTime_PPIM" SG_ 222 IDCM_DTC_Idx2 0;
BA_ "GenSigTimeoutTime_BPCM" SG_ 222 IDCM_DTC_Idx2 0;
BA_ "GenSigTimeoutTime_IDCM" SG_ 222 IDCM_DTC_Idx2 0;
BA_ "GenSigTimeoutTime_SGW" SG_ 222 IDCM_DTC_Idx2 0;
BA_ "GenSigTimeoutTime_HCP" SG_ 222 IDCM_DTC_Stat7 0;
BA_ "GenSigTimeoutTime_PPIM" SG_ 222 IDCM_DTC_Stat7 0;
BA_ "GenSigTimeoutTime_BPCM" SG_ 222 IDCM_DTC_Stat7 0;
BA_ "GenSigTimeoutTime_IDCM" SG_ 222 IDCM_DTC_Stat7 0;
BA_ "GenSigTimeoutTime_SGW" SG_ 222 IDCM_DTC_Stat7 0;
BA_ "GenSigTimeoutTime_HCP" SG_ 222 IDCM_DTC_Stat6 0;
BA_ "GenSigTimeoutTime_PPIM" SG_ 222 IDCM_DTC_Stat6 0;
BA_ "GenSigTimeoutTime_BPCM" SG_ 222 IDCM_DTC_Stat6 0;
BA_ "GenSigTimeoutTime_IDCM" SG_ 222 IDCM_DTC_Stat6 0;
BA_ "GenSigTimeoutTime_SGW" SG_ 222 IDCM_DTC_Stat6 0;
BA_ "GenSigTimeoutTime_HCP" SG_ 222 IDCM_DTC_Idx1 0;
BA_ "GenSigTimeoutTime_PPIM" SG_ 222 IDCM_DTC_Idx1 0;
BA_ "GenSigTimeoutTime_BPCM" SG_ 222 IDCM_DTC_Idx1 0;
BA_ "GenSigTimeoutTime_IDCM" SG_ 222 IDCM_DTC_Idx1 0;
BA_ "GenSigTimeoutTime_SGW" SG_ 222 IDCM_DTC_Idx1 0;
BA_ "GenSigTimeoutTime_HCP" SG_ 1042 CRC_IDCM_ISO15118_STATUS1 0;
BA_ "GenSigTimeoutTime_PPIM" SG_ 1042 CRC_IDCM_ISO15118_STATUS1 0;
BA_ "GenSigTimeoutTime_APM2" SG_ 1042 CRC_IDCM_ISO15118_STATUS1 0;
BA_ "GenSigTimeoutTime_HCP" SG_ 1042 MC_IDCM_ISO15118_STATUS1 0;
BA_ "GenSigTimeoutTime_PPIM" SG_ 1042 MC_IDCM_ISO15118_STATUS1 0;
BA_ "GenSigTimeoutTime_APM2" SG_ 1042 MC_IDCM_ISO15118_STATUS1 0;
BA_ "GenSigTimeoutTime_HCP" SG_ 1042 EVSE_Offered_DC_Extended 0;
BA_ "GenSigTimeoutTime_PPIM" SG_ 1042 EVSE_Offered_DC_Extended 0;
BA_ "GenSigTimeoutTime_APM2" SG_ 1042 EVSE_Offered_DC_Extended 0;
BA_ "GenSigTimeoutTime_VDCM" SG_ 1042 EVSE_Offered_DC_Extended 0;
BA_ "GenSigTimeoutTime_HCP" SG_ 1042 EVSE_Offered_DC_Unique 0;
BA_ "GenSigTimeoutTime_PPIM" SG_ 1042 EVSE_Offered_DC_Unique 0;
BA_ "GenSigTimeoutTime_APM2" SG_ 1042 EVSE_Offered_DC_Unique 0;
BA_ "GenSigTimeoutTime_VDCM" SG_ 1042 EVSE_Offered_DC_Unique 0;
BA_ "GenSigTimeoutTime_HCP" SG_ 1042 V2X_EVSE_Service_6_Free 0;
BA_ "GenSigTimeoutTime_PPIM" SG_ 1042 V2X_EVSE_Service_6_Free 0;
BA_ "GenSigTimeoutTime_APM2" SG_ 1042 V2X_EVSE_Service_6_Free 0;
BA_ "GenSigTimeoutTime_HCP" SG_ 1042 Contract_Certificate_Present 0;
BA_ "GenSigTimeoutTime_PPIM" SG_ 1042 Contract_Certificate_Present 0;
BA_ "GenSigTimeoutTime_APM2" SG_ 1042 Contract_Certificate_Present 0;
BA_ "GenSigTimeoutTime_VDCM" SG_ 1042 Contract_Certificate_Present 0;
BA_ "GenSigTimeoutTime_HCP" SG_ 1042 V2X_EVSE_Service_5_Free 0;
BA_ "GenSigTimeoutTime_PPIM" SG_ 1042 V2X_EVSE_Service_5_Free 0;
BA_ "GenSigTimeoutTime_APM2" SG_ 1042 V2X_EVSE_Service_5_Free 0;
BA_ "GenSigTimeoutTime_HCP" SG_ 1042 EVSE_Offered_DC_Core 0;
BA_ "GenSigTimeoutTime_PPIM" SG_ 1042 EVSE_Offered_DC_Core 0;
BA_ "GenSigTimeoutTime_APM2" SG_ 1042 EVSE_Offered_DC_Core 0;
BA_ "GenSigTimeoutTime_VDCM" SG_ 1042 EVSE_Offered_DC_Core 0;
BA_ "GenSigTimeoutTime_HCP" SG_ 1042 EVSE_Offered_DC_Combo_Core 0;
BA_ "GenSigTimeoutTime_PPIM" SG_ 1042 EVSE_Offered_DC_Combo_Core 0;
BA_ "GenSigTimeoutTime_APM2" SG_ 1042 EVSE_Offered_DC_Combo_Core 0;
BA_ "GenSigTimeoutTime_VDCM" SG_ 1042 EVSE_Offered_DC_Combo_Core 0;
BA_ "GenSigTimeoutTime_HCP" SG_ 1042 EVSE_Offered_AC_Three_Phase 0;
BA_ "GenSigTimeoutTime_PPIM" SG_ 1042 EVSE_Offered_AC_Three_Phase 0;
BA_ "GenSigTimeoutTime_APM2" SG_ 1042 EVSE_Offered_AC_Three_Phase 0;
BA_ "GenSigTimeoutTime_VDCM" SG_ 1042 EVSE_Offered_AC_Three_Phase 0;
BA_ "GenSigTimeoutTime_HCP" SG_ 1042 EVSE_Offered_AC_Single_Phase 0;
BA_ "GenSigTimeoutTime_PPIM" SG_ 1042 EVSE_Offered_AC_Single_Phase 0;
BA_ "GenSigTimeoutTime_APM2" SG_ 1042 EVSE_Offered_AC_Single_Phase 0;
BA_ "GenSigTimeoutTime_VDCM" SG_ 1042 EVSE_Offered_AC_Single_Phase 0;
BA_ "GenSigTimeoutTime_BPCM" SG_ 1041 EVMaxVoltage 0;
BA_ "GenSigTimeoutTime_EVCU2" SG_ 1041 EVMaxVoltage 0;
BA_ "GenSigTimeoutTime_SGW" SG_ 1041 EVMaxVoltage 0;
BA_ "GenSigTimeoutTime_BPCM" SG_ 1041 EVMinCurrent 0;
BA_ "GenSigTimeoutTime_EVCU2" SG_ 1041 EVMinCurrent 0;
BA_ "GenSigTimeoutTime_SGW" SG_ 1041 EVMinCurrent 0;
BA_ "GenSigTimeoutTime_BPCM" SG_ 1041 Protocol_Namespace_Priority_3 0;
BA_ "GenSigTimeoutTime_EVCU2" SG_ 1041 Protocol_Namespace_Priority_3 0;
BA_ "GenSigTimeoutTime_SGW" SG_ 1041 Protocol_Namespace_Priority_3 0;
BA_ "GenSigTimeoutTime_BPCM" SG_ 1041 Protocol_Namespace_Priority_2 0;
BA_ "GenSigTimeoutTime_EVCU2" SG_ 1041 Protocol_Namespace_Priority_2 0;
BA_ "GenSigTimeoutTime_SGW" SG_ 1041 Protocol_Namespace_Priority_2 0;
BA_ "GenSigTimeoutTime_BPCM" SG_ 1041 EVMaxCurrent 0;
BA_ "GenSigTimeoutTime_EVCU2" SG_ 1041 EVMaxCurrent 0;
BA_ "GenSigTimeoutTime_SGW" SG_ 1041 EVMaxCurrent 0;
BA_ "GenSigTimeoutTime_BPCM" SG_ 1041 Protocol_Namespace_Priority_1 0;
BA_ "GenSigTimeoutTime_EVCU2" SG_ 1041 Protocol_Namespace_Priority_1 0;
BA_ "GenSigTimeoutTime_SGW" SG_ 1041 Protocol_Namespace_Priority_1 0;
BA_ "GenSigTimeoutTime_BPCM" SG_ 1041 Protocol_Namespace_Priority_4 0;
BA_ "GenSigTimeoutTime_EVCU2" SG_ 1041 Protocol_Namespace_Priority_4 0;
BA_ "GenSigTimeoutTime_SGW" SG_ 1041 Protocol_Namespace_Priority_4 0;
BA_ "GenSigTimeoutTime_BPCM" SG_ 1041 CRC_EVCU_ISO15118_STATUS1 0;
BA_ "GenSigTimeoutTime_EVCU2" SG_ 1041 CRC_EVCU_ISO15118_STATUS1 0;
BA_ "GenSigTimeoutTime_SGW" SG_ 1041 CRC_EVCU_ISO15118_STATUS1 0;
BA_ "GenSigTimeoutTime_BPCM" SG_ 1041 MC_EVCU_ISO15118_STATUS1 0;
BA_ "GenSigTimeoutTime_EVCU2" SG_ 1041 MC_EVCU_ISO15118_STATUS1 0;
BA_ "GenSigTimeoutTime_SGW" SG_ 1041 MC_EVCU_ISO15118_STATUS1 0;
BA_ "GenSigTimeoutTime_BPCM" SG_ 1041 Eamount 0;
BA_ "GenSigTimeoutTime_EVCU2" SG_ 1041 Eamount 0;
VAL_ 2654339197 EOL_FD11_IDCM 0 "No_EOL_Programming" 1 "EOL_Programming";
VAL_ 1064 SGCP_Temp 255 "SNA";
VAL_ 2654339197 WakeupSource_FD11_IDCM 0 "No_Wakeup";
VAL_ 2654339197 PreviousCanNMState_FD11_IDCM 0 "Uninitialized State" 1 "Bus-Sleep State" 2 "Prepare-Bus State" 3 "Ready-Sleep State" 4 "Normal Operation State" 5 "Repeat Message State" 6 "Synchronize State" 7 "Offline State";
VAL_ 2654339197 GenericFailSts_FD11_IDCM 0 "No_Fail_Present" 1 "Fail_Present";
VAL_ 2654339197 DES_FD11_IDCM 0 "Error_Active_state" 1 "Error_passive_warning_state" 2 "Bus_off_state" 3 "Not_used";
VAL_ 2654339197 CurrentFailSts_FD11_IDCM 0 "No_Fail_Present" 1 "Fail_Present";
VAL_ 2654339197 CurrentCanNMState_FD11_IDCM 0 "Uninitialized State" 1 "Bus-Sleep State" 2 "Prepare-Bus State" 3 "Ready-Sleep State" 4 "Normal Operation State" 5 "Repeat Message State" 6 "Synchronize State" 7 "Offline State";
VAL_ 263 GearEngagedForDisplay_PT 0 "Initialize" 1 "Gear_1st" 2 "Gear_2nd" 3 "Gear_3rd" 4 "Gear_4th" 5 "Gear_5th" 6 "Gear_6th" 7 "Gear_7th" 8 "Gear_8th" 9 "Gear_9th" 12 "Park" 13 "Neutral" 14 "Reverse" 15 "Drive" 16 "Low" 17 "Manual" 18 "Sport_Mode" 31 "SNA";
VAL_ 263 GearEngaged_PT 0 "Neutral" 1 "ForwardGear_1" 2 "ForwardGear_2" 3 "ForwardGear_3" 4 "ForwardGear_4" 5 "ForwardGear_5" 6 "ForwardGear_6" 7 "ForwardGear_7" 8 "ForwardGear_8" 9 "ForwardGear_9" 13 "Parking" 14 "ReverseGear" 15 "SNA";
VAL_ 263 DriveReady_PT 0 "Default" 1 "Veh_Allwd_Shift_Out_Of_P_Or_N";
VAL_ 216 DCChargeInitialized_PT 0 "FALSE" 1 "TRUE";
VAL_ 216 DCChargeEnRq_PT 0 "ChargeNotEnabled" 1 "ChargeEnabled";
VAL_ 216 BPCM_OBCM_AC_ContactorCmd_PT 0 "OPEN" 1 "SYNC" 2 "CLOSE" 7 "SNA";
VAL_ 216 BMS_HV_TracCntctr_Cmd_PT 0 "OPEN" 1 "CLOSED" 2 "IMPACT_OPEN" 3 "FAST_OPEN" 7 "SNA";
VAL_ 216 BMS_HV_RefTracHVBus_V_Vldty_PT 0 "VALID" 1 "INVALID";
VAL_ 216 BMS_HV_RefTracHVBus_V_PT 1023 "SNA";
VAL_ 216 BMS_HV_GFD_Inhibition_PT 0 "GFD_Allowed" 1 "GFD_Inhibited";
VAL_ 216 BMS_HV_DC_Chrgng_Cntct_K_Cmd_PT 0 "OPEN" 2 "CLOSE" 7 "SNA";
VAL_ 216 APM2_TypeCtrl_PT 0 "CC_Mode" 1 "VC_Mode" 2 "POWER_Mode" 7 "SNA";
VAL_ 216 APM_LV_VsetPoint_PT 2047 "SNA";
VAL_ 216 APM_LV_VActual_PT 511 "SNA";
VAL_ 216 APM_LV_IMax_PT 511 "SNA";
VAL_ 2654339197 WakeupSource_FD05_IDCM 0 "No_Wakeup";
VAL_ 2654339197 PreviousCanNMState_FD05_IDCM 0 "Uninitialized State" 1 "Bus-Sleep State" 2 "Prepare-Bus State" 3 "Ready-Sleep State" 4 "Normal Operation State" 5 "Repeat Message State" 6 "Synchronize State" 7 "Offline State";
VAL_ 2654339197 GenericFailSts_FD05_IDCM 0 "No_Fail_Present" 1 "Fail_Present";
VAL_ 2654339197 EOL_FD05_IDCM 0 "No_EOL_Programming" 1 "EOL_Programming";
VAL_ 2654339197 DES_FD05_IDCM 0 "Error_Active_state" 1 "Error_passive_warning_state" 2 "Bus_off_state" 3 "Not_used";
VAL_ 2654339197 CurrentFailSts_FD05_IDCM 0 "No_Fail_Present" 1 "Fail_Present";
VAL_ 2654339197 CurrentCanNMState_FD05_IDCM 0 "Uninitialized State" 1 "Bus-Sleep State" 2 "Prepare-Bus State" 3 "Ready-Sleep State" 4 "Normal Operation State" 5 "Repeat Message State" 6 "Synchronize State" 7 "Offline State";
VAL_ 263 PowertrainPrplsnActv_PT 0 "Not_Active" 1 "Active";
VAL_ 1042 ParameterID_Update 0 "FALSE" 1 "TRUE";
VAL_ 1042 ParameterID_Installation 0 "FALSE" 1 "TRUE";
VAL_ 1042 ISO15118_TLS_Status 0 "Not_Performed" 1 "Conn_Not_Established" 2 "Conn_Established_with_TLS" 3 "Conn_Established_No_TLS" 4 "Failure";
VAL_ 1042 ISO15118_TLS_Offered 0 "NOT_OFFERED" 1 "OFFERED";
VAL_ 1042 ISO15118_ResponseCode 0 "OK" 1 "OK_CertificateExpiresSoon" 2 "OK_NewSessionEstablished" 3 "OK_OldSessionJoined" 4 "FAILED" 5 "FAILED_SequenceError" 6 "FAILED_SignatureError" 7 "FAILED_UnknownSession" 8 "FAILED_ServiceIDInvalid" 9 "FAILED_PaymentSelectionInvalid" 10 "FAILED_ServiceSelectionInvalid" 11 "FAILED_CertificateExpired" 12 "FAILED_NoCertificateAvailable" 13 "FAILED_CertChainError" 14 "FAILED_ContractCanceled" 15 "FAILED_ChallengeInvalid" 16 "FAILED_WrongEnergyTransferType" 17 "FAILED_WrongChargeParameter" 18 "FAILED_ChargingProfileInvalid" 19 "FAILED_TariffSelectionInvalid" 20 "FAILED_EVSEPresentVoltageToLow" 21 "FAILED_PowerDeliveryNotApplied" 22 "FAILED_MeteringSignatureNotValid" 23 "OK_SuccessfullNegotiation" 24 "OK_SucceedNegotiatnMinorDeviatn" 25 "FAILED_NoNegotiation" 26 "FAILED_CertificateRevoked" 27 "FAILED_NoChargeServiceSelected" 28 "FAILED_ContactorError" 29 "FAILED_CertNotAllowedAtThisEVSE" 31 "SNA";
VAL_ 1042 ISO15118_MessageResponse 0 "No_V2G_communication" 1 "SupportedAppProtocolRes" 2 "SessionSetupRes" 3 "ServiceDiscoveryRes" 4 "ServicePaymentSelectionRes" 5 "Contract_AuthenticationRes" 6 "ChargeParameterDiscoveryRes" 7 "CableCheckRes" 8 "Pre_chargeRes" 9 "PowerDeliveryRes_Precharge" 10 "CurrentDemandRes" 11 "PowerDeliveryRes_EnergyTransfer" 12 "WeldingDetectionRes" 13 "SessionStopRes" 14 "DC_BidirectionalControlRes" 15 "ServiceDetailRes" 16 "CertificateUpdateReq" 17 "CertificateInstallationReq" 31 "SNA";
VAL_ 1042 ISO15118_EVCC_ActionRequest 0 "None" 1 "Stop_Charging" 2 "Renegotiation";
VAL_ 1042 EVSE_Service4_UseCaseInfo 0 "NOT_AVAILABLE" 1 "AVAILABLE";
VAL_ 1042 EVSE_Service4_Free 0 "PAID_SERVICE" 1 "FREE_SERVICE";
VAL_ 1042 EVSE_Service3_Internet 0 "NOT_AVAILABLE" 1 "AVAILABLE";
VAL_ 1042 EVSE_Service3_Free 0 "PAID_SERVICE" 1 "FREE_SERVICE";
VAL_ 1042 EVSE_Service2_Free 0 "PAID_SERVICE" 1 "FREE_SERVICE";
VAL_ 1042 EVSE_Service2_Certificates 0 "NOT_AVAILABLE" 1 "AVAILABLE";
VAL_ 1042 EVSE_Service1_Free 0 "PAID_SERVICE" 1 "FREE_SERVICE";
VAL_ 1042 EVSE_Service1_Charging 0 "NOT_AVAILABLE" 1 "AVAILABLE";
VAL_ 1041 SelectionParameterSetID 0 "No_Parameter_Set_ID" 1 "Installation" 2 "Update";
VAL_ 1041 Protocol_Priority3 0 "No_Protocol" 1 "ISO_15118_20" 2 "ISO_15118_2" 3 "DIN_70121";
VAL_ 1041 Protocol_Priority2 0 "No_Protocol" 1 "ISO_15118_20" 2 "ISO_15118_2" 3 "DIN_70121";
VAL_ 1041 Protocol_Priority1 0 "No_Protocol" 1 "ISO_15118_20" 2 "ISO_15118_2" 3 "DIN_70121";
VAL_ 1041 ISO15118_TLS_Connected 0 "FALSE" 1 "TRUE";
VAL_ 1041 ISO15118_EVErrorCode 0 "No_Error" 1 "FAILED_RESSTemperatureInhibit" 2 "FAILED_EVShiftPosition" 3 "FAILED_ChargerConnectorLockFlt" 4 "FAILED_EVRESSMalfunction" 5 "FAILED_ChargeCurrentDifferential" 6 "FAILED_ChargeCurrentVoltageOOR" 7 "Reserved_A_C" 8 "FAILED_ChrgSysIncompatibility" 15 "No_Data";
VAL_ 1041 ISO15118_ChargeSession 0 "No_Request" 1 "Pause" 2 "Terminate";
VAL_ 1041 ISO15118_ChargeProgress 0 "No_Request" 1 "Start" 2 "Stop" 3 "Renegotiate";
VAL_ 2654339286 WakeupSource_FD11_PPIM 0 "No_Wakeup";
VAL_ 2654339286 WakeupSource_FD05_PPIM 0 "No_Wakeup";
VAL_ 2654339286 PreviousCanNMState_FD11_PPIM 0 "Uninitialized State" 1 "Bus-Sleep State" 2 "Prepare-Bus State" 3 "Ready-Sleep State" 4 "Normal Operation State" 5 "Repeat Message State" 6 "Synchronize State" 7 "Offline State";
VAL_ 2654339286 PreviousCanNMState_FD05_PPIM 0 "Uninitialized State" 1 "Bus-Sleep State" 2 "Prepare-Bus State" 3 "Ready-Sleep State" 4 "Normal Operation State" 5 "Repeat Message State" 6 "Synchronize State" 7 "Offline State";
VAL_ 2654339286 GenericFailSts_FD11_PPIM 0 "No_Fail_Present" 1 "Fail_Present";
VAL_ 2654339286 GenericFailSts_FD05_PPIM 0 "No_Fail_Present" 1 "Fail_Present";
VAL_ 2654339286 EOL_FD11_PPIM 0 "No_EOL_Programming" 1 "EOL_Programming";
VAL_ 2654339286 EOL_FD05_PPIM 0 "No_EOL_Programming" 1 "EOL_Programming";
VAL_ 2654339286 DES_FD11_PPIM 0 "Error_Active_state" 1 "Error_passive_warning_state" 2 "Bus_off_state" 3 "Not_used";
VAL_ 2654339286 DES_FD05_PPIM 0 "Error_Active_state" 1 "Error_passive_warning_state" 2 "Bus_off_state" 3 "Not_used";
VAL_ 2654339286 CurrentFailSts_FD11_PPIM 0 "No_Fail_Present" 1 "Fail_Present";
VAL_ 2654339286 CurrentFailSts_FD05_PPIM 0 "No_Fail_Present" 1 "Fail_Present";
VAL_ 2654339286 CurrentCanNMState_FD11_PPIM 0 "Uninitialized State" 1 "Bus-Sleep State" 2 "Prepare-Bus State" 3 "Ready-Sleep State" 4 "Normal Operation State" 5 "Repeat Message State" 6 "Synchronize State" 7 "Offline State";
VAL_ 2654339286 CurrentCanNMState_FD05_PPIM 0 "Uninitialized State" 1 "Bus-Sleep State" 2 "Prepare-Bus State" 3 "Ready-Sleep State" 4 "Normal Operation State" 5 "Repeat Message State" 6 "Synchronize State" 7 "Offline State";
VAL_ 2654486592 CBV_bit4_ActiveWakeupBit_1E384040 0 "PassiveWakeup" 1 "ActiveWakeup";
VAL_ 2654486742 CBV_bit0_RepeatMessageRequestBit_1E3840D6 0 "Repeat_Message_State_not_requested" 1 "Repeat_Message_State_requested";
VAL_ 2654486742 CBV_bit3_NMCoordinatorBit_1E3840D6 0 "Start_of_synchronized_shutdown_is_not_requested_by_main_coordinator" 1 "Start_of_synchronized_shutdown_is_requested_by_main_coordinator";
VAL_ 2654486742 CBV_bit4_ActiveWakeupBit_1E3840D6 0 "PassiveWakeup" 1 "ActiveWakeup";
VAL_ 2654486742 CBV_bit6_PartialNtwInfBit_1E3840D6 0 "NM_PDU_contains_no_Partial_Network_request_information" 1 "NM_PDU_contains_Partial_Network_request_information";
VAL_ 1044 DischargingSysStatus 0 "Inactive" 1 "Active" 2 "Faulted" 3 "SNA";
VAL_ 1041 EVMinCurrent 511 "SNA";
VAL_ 1041 EVMaxVoltage 1023 "SNA";
VAL_ 1041 EVMaxCurrent 511 "SNA";
VAL_ 1041 Eamount 262143 "SNA";
VAL_ 1048 V2X_ModeRequest 0 "No_Request" 1 "Idle" 2 "Discharge" 3 "Reserved";
VAL_ 1050 V2X_Modefeedback 0 "No_Request" 1 "Idle" 2 "Discharge" 3 "Reserved";
VAL_ 1050 V2X_InterlockSts 0 "Not_Performed" 1 "OK" 2 "Fail" 3 "Invaild";
VAL_ 1050 V2X_FailSts 0 "No_Fault" 1 "Faulted";
VAL_ 1050 V2X_Derate_Status 0 "Not_Active" 1 "Active";
VAL_ 1050 V2X_Derate_Reason 0 "No_Derating" 1 "High_Temp_Derating" 2 "Low_Temp_Derating_Res" 3 "Input_Voltage_Limit" 4 "Input_Current_Limit" 5 "Output_Voltage_Limit" 6 "Output_Current_Limit" 7 "Internal_Fault_Derating";
VAL_ 1046 V2X_Status 0 "V2X_Not_detected" 1 "V2X_Detected";
VAL_ 1046 DischargeFaultStatus 0 "No_fault" 1 "Flt_Discharging_Allowed" 2 "Flt_Discharging_Inhibited" 3 "Flt_Discharging_Terminated" 7 "SNA";
VAL_ 1046 DCInputVoltage 8191 "SNA";
VAL_ 1046 DCInputCurrent 1023 "SNA";
VAL_ 1046 ACOutputVoltage3 4095 "SNA";
VAL_ 1046 ACOutputVoltage2 4095 "SNA";
VAL_ 1046 ACOutputVoltage1 4095 "SNA";
VAL_ 1046 ACOutputCurrent3 1023 "SNA";
VAL_ 1046 ACOutputCurrent2 1023 "SNA";
VAL_ 1046 ACOutputCurrent1 1023 "SNA";
VAL_ 216 APM_TypeCtrl_PT 0 "IDLE" 1 "Buck_CV" 2 "Buck_CC" 3 "Buck_CP" 4 "Buck_Special" 6 "PreCharge" 7 "DisCharge" 8 "OFF" 15 "SNA";
VAL_ 1072 EVSE_EnergizingState 0 "Disable" 1 "Enable";
VAL_ 1072 EVSE_ChargingSystemError 0 "Normal" 1 "Error";
VAL_ 1072 EVSE_CHAdeMOProtocol 0 "CHAdeMO_0_9_and_earlier" 1 "CHAdeMO_0_9_and_0_9_1" 2 "CHAdeMO_1_0and1_0_1and1_1and1_2" 3 "CHAdeMO_2_0" 7 "SNA";
VAL_ 1072 EVSE_BatteryCompatibilty 0 "compatible" 1 "Incompatible";
VAL_ 1073 VehicleDriveSts 0 "Parked" 1 "Not_parked";
VAL_ 1073 StopReqBeforeCharge 0 "No_Request" 1 "Request_Stop";
VAL_ 1073 EVContactorSts 0 "Contactor_closed" 1 "EV_Contactor_Open";
VAL_ 1073 CHAdeMOProtocol 0 "CHAdeMO_0_9_and_earlier" 1 "CHAdeMO_0_9_and_0_9_1" 2 "CHAdeMO_1_0and1_0_1and1_1and1_2" 3 "CHAdeMO_2_0" 7 "SNA";
VAL_ 1073 BattVoltDeviationErr 0 "Normal" 1 "Fault";
VAL_ 216 EVCU_Resp_AUX_LoadTurned_Off 0 "FALSE" 1 "TRUE";
VAL_ 216 DC_Charge_Type_Command 1 "Plugged_into_800V" 2 "Plugged_into_400V" 3 "SNA";
VAL_ 1050 V2X_FaultRsn 0 "No_FAULT" 1 "COMM_FAULT" 2 "Batt_12vFault" 3 "PPIM_AC_Fault" 4 "PPIM_DC_Fault" 5 "Wake_up_Circuit_Fault" 6 "Impact" 7 "Over_temperature_Fault" 8 "Fan_fault" 9 "Fault_Protection_Mode" 10 "GFCI_Fault" 15 "SNA";
VAL_ 216 BMS_HV_Char_Main_Contac_Cmd_PT 0 "Open" 1 "Close" 2 "Impact_Open" 3 "Fast_Open" 7 "INV";
VAL_ 1041 Protocol_Namespace_Priority_4 0 "No_Protocol" 1 "ISO_15118_20" 2 "ISO_15118_2" 3 "DIN70121" 4 "SAEJ2842_2" 7 "SNA";
VAL_ 1041 Protocol_Namespace_Priority_3 0 "No_Protocol" 1 "ISO_15118_20" 2 "ISO_15118_2" 3 "DIN70121" 4 "SAEJ2842_2" 7 "SNA";
VAL_ 1041 Protocol_Namespace_Priority_2 0 "No_Protocol" 1 "ISO_15118_20" 2 "ISO_15118_2" 3 "DIN70121" 4 "SAEJ2842_2" 7 "SNA";
VAL_ 1041 Protocol_Namespace_Priority_1 0 "No_Protocol" 1 "ISO_15118_20" 2 "ISO_15118_2" 3 "DIN70121" 4 "SAEJ2842_2" 7 "SNA";
VAL_ 1042 Contract_Certificate_Present 0 "Not_Available" 1 "Available";
VAL_ 1042 EVSE_Offered_AC_Single_Phase 0 "Not_offered" 1 "Offered";
VAL_ 1042 EVSE_Offered_AC_Three_Phase 0 "Not_offered" 1 "Offered";
VAL_ 1042 EVSE_Offered_DC_Combo_Core 0 "Not_offered" 1 "Offered";
VAL_ 1042 EVSE_Offered_DC_Core 0 "Not_offered" 1 "Offered";
VAL_ 1042 EVSE_Offered_DC_Extended 0 "Not_offered" 1 "Offered";
VAL_ 1042 EVSE_Offered_DC_Unique 0 "Not_offered" 1 "Offered";
VAL_ 216 APM2ActDischRq_PT 0 "Not_Requested" 1 "Requested";
VAL_ 1072 CdM_Charger_connector_lock 0 "Lock_release" 1 "Lock";
VAL_ 1073 EVCU_CP3Cmd 0 "Disable_veh_charge_permission" 1 "Enable_veh_charge_permission";
VAL_ 1073 CdM_Remained_batt_capacity 255 "SNA";
VAL_ 1048 ACFrequencyCommand 0 "Hz_50" 1 "Hz_60";
VAL_ 1042 V2X_EVSE_Service_6_Free 0 "Paid_Service" 1 "Free_Service";
VAL_ 1042 V2X_EVSE_Service_5_Free 0 "Paid_Service" 1 "Free_Service";
VAL_ 1044 LID_Status_120V_Socket_B 0 "LID_closed" 1 "LID_Open";
VAL_ 1044 LID_Status_120V_Socket_A 0 "LID_closed" 1 "LID_Open";
VAL_ 577 QualifyDriveCycle 0 "Not_Realized" 1 "Realized";
VAL_ 1046 IDCM_GFCI_Fault_Status 0 "GFCI_Fault_Not_Detected" 1 "GFCI_Fault_Detected";
VAL_ 1044 LID_Status_240V_Socket 0 "LID_closed" 1 "LID_Open";
VAL_ 216 APM2_BoostSwitchControl 0 "Open" 1 "Close" 2 "No_Request";
VAL_ 216 APM2_ModeRequest_PT 0 "Not_Charging" 1 "Idle" 2 "Sync" 3 "BYPass" 4 "Boost" 5 "Charge_Interrupt" 6 "Stop_Failure" 7 "Buck" 15 "SNA";
VAL_ 219 HVBat_Rsrv_Enrgy_Remain 65535 "SNA";
VAL_ 219 HVBatSOH_Distance_Last_Calc 65535 "SNA";
VAL_ 219 HVBatSOH_reg 255 "SNA";
VAL_ 1073 CdM_ExtFun_Veh_HC_Control_Comp 0 "High_current_cntrl_not_applied" 1 "High_current_cntrl_is_applied";
VAL_ 1073 CdM_ExtFun_Veh_Dyn_Control_Comp 0 "No_dyn_cntrl_of_extd_function" 1 "Dyn_cntrl_of_extd_function";
VAL_ 1073 CdM_ExtFun_Min_Batt_Volt 2047 "SNA";
VAL_ 222 IDCM_DTC_Idx8 31 "SNA";
VAL_ 222 IDCM_DTC_Stat1 7 "Not_Supported";
VAL_ 222 IDCM_DTC_Stat2 7 "Not_Supported";
VAL_ 222 IDCM_DTC_Stat3 7 "Not_Supported";
VAL_ 222 IDCM_DTC_Stat4 7 "Not_Supported";
VAL_ 222 IDCM_DTC_Stat5 7 "Not_Supported";
VAL_ 222 IDCM_DTC_Idx2 31 "SNA";
VAL_ 222 IDCM_DTC_Idx3 31 "SNA";
VAL_ 222 IDCM_DTC_Idx4 31 "SNA";
VAL_ 222 IDCM_DTC_Idx5 31 "SNA";
VAL_ 222 IDCM_DTC_Idx6 31 "SNA";
VAL_ 222 IDCM_DTC_Idx7 31 "SNA";
VAL_ 222 IDCM_CAL_ID 63 "SNA";
VAL_ 222 IDCM_CAL_VN 255 "SNA";
VAL_ 222 IDCM_DTC_Idx1 31 "SNA";
VAL_ 222 IDCM_DTC_Stat6 7 "Not_Supported";
VAL_ 222 IDCM_DTC_Stat7 7 "Not_Supported";
VAL_ 222 IDCM_DTC_Stat8 7 "Not_Supported";
VAL_ 222 IDCM_RBM_Idx 31 "SNA";
VAL_ 222 IDCM_RBM_Stat 7 "SNA";

SIG_GROUP_ 1042 IDCM_ISO15118_STATUS1_Pkt 1 : EVSE_Service1_Charging EVSE_Service1_Free EVSE_Service2_Certificates EVSE_Service2_Free EVSE_Service3_Free EVSE_Service3_Internet EVSE_Service4_Free EVSE_Service4_UseCaseInfo ISO15118_EnergyToDeliver ISO15118_EVCC_ActionRequest ISO15118_EVSETimeStamp ISO15118_MessageResponse ISO15118_NotificationMaxDelay ISO15118_PMax ISO15118_PMaxScheduleID ISO15118_ResponseCode ISO15118_SAScheduleTupleID ISO15118_SchemaID ISO15118_ServiceID ISO15118_TLS_Offered ISO15118_TLS_Status ISO15118_VersionNumMajor ISO15118_VersionNumMinor ParameterID_Installation ParameterID_Update PMax_RelDuration_Interval PMax_RelStart_Interval MC_IDCM_ISO15118_STATUS1 CRC_IDCM_ISO15118_STATUS1 EVSE_Offered_DC_Unique EVSE_Offered_DC_Extended EVSE_Offered_DC_Core EVSE_Offered_DC_Combo_Core EVSE_Offered_AC_Three_Phase EVSE_Offered_AC_Single_Phase Contract_Certificate_Present V2X_EVSE_Service_6_Free V2X_EVSE_Service_5_Free;
SIG_GROUP_ 1046 RPF_FD_1_Pkt 1 : V2H_HVCMS_EVSEMaxPowerLimit V2X_Status V2X_Frequency DischargeFaultStatus DCInputVoltage DCInputCurrent ACOutputVoltage3 ACOutputVoltage2 ACOutputVoltage1 ACOutputCurrent3 ACOutputCurrent2 ACOutputCurrent1 ACOutput_Frequency MC_RPF_FD_1 CRC_RPF_FD_1 IDCM_GFCI_Fault_Status;
SIG_GROUP_ 1048 RPF_FD_3_Pkt 1 : V2H_HVCMS_EVMax_P_Limit V2X_ModeRequest DCInputCurrentLimit_V2X MC_RPF_FD_3 CRC_RPF_FD_3 ACFrequencyCommand;
SIG_GROUP_ 1050 RPF_FD_2_Pkt 1 : V2X_Modefeedback V2X_LV_Feed V2X_InterlockSts V2X_InputVoltage V2X_InputCurrent V2X_FailSts V2X_Derate_Status V2X_Derate_Reason Available_Power AcOutputVoltage AcOutputFrequency AcOuputCurrent V2X_FaultRsn MC_RPF_FD_2 CRC_RPF_FD_2;
SIG_GROUP_ 1041 EVCU_ISO15118_STATUS1_Pkt 1 : ISO15118_ChargeProgress ISO15118_ChargeSession ISO15118_DepartureTime ISO15118_EVCCID ISO15118_EVEnergyCapacity ISO15118_EVEnergyRequest ISO15118_EVErrorCode ISO15118_SessionID ISO15118_TimeToBulkSOC ISO15118_TimeToFullSOC ISO15118_TLS_Connected MaxEntriesSASScheduleTuple Protocol_Priority1 Protocol_Priority2 Protocol_Priority3 SelectionParameterSetID Eamount EVMaxCurrent EVMaxVoltage EVMinCurrent Protocol_Namespace_Priority_4 Protocol_Namespace_Priority_3 Protocol_Namespace_Priority_2 Protocol_Namespace_Priority_1 MC_EVCU_ISO15118_STATUS1 CRC_EVCU_ISO15118_STATUS1;
SIG_GROUP_ 216 PT_ENERGY_FD_1_Pkt 1 : MC_PT_ENERGY_FD_1 DCChrgVoltMin_PT DCChrgVoltMax_PT DCChrgPwrLim_PT DCChrgCurrentRq_PT DCChrgCurrentLimit_PT DCChargeInitialized_PT DCChargeEnRq_PT CRC_PT_ENERGY_FD_1 BPCM_OBCM_AC_ContactorCmd_PT BMS_HV_TracCntctr_Cmd_PT BMS_HV_RefTracHVBus_V_Vldty_PT BMS_HV_RefTracHVBus_V_PT BMS_HV_GFD_Inhibition_PT BMS_HV_DC_Chrgng_Cntct_K_Cmd_PT BatteryVoltage_Raw_PT APM2_TypeCtrl_PT APM_LV_VsetPoint_PT APM_LV_VActual_PT APM_LV_IMax_PT APM_HV_IMax_PT APM_TypeCtrl_PT EVCU_Resp_AUX_LoadTurned_Off DC_Charge_Type_Command BMS_HV_Char_Main_Contac_Cmd_PT APM2_EVSEBusPrechargeReq_PT APM2_EVSEBusVoltSetPoint_PT APM2ActDischRq_PT APM2_BoostSwitchControl APM2_ModeRequest_PT;
